VERSION ""

NS_ :

BS_:

BU_: BMU_ID_0 BMU_ID_1 BMU_ID_2 BMU_ID_3 BMU_ID_4 BMU_ID_5 BMU_ID_6 BMU_ID_7 BMU_ID_8 BMU_ID_9 BMU_ID_10 BMU_ID_11 BMU_ID_12 BMU_ID_13 BMU_ID_14 BMU_ID_15

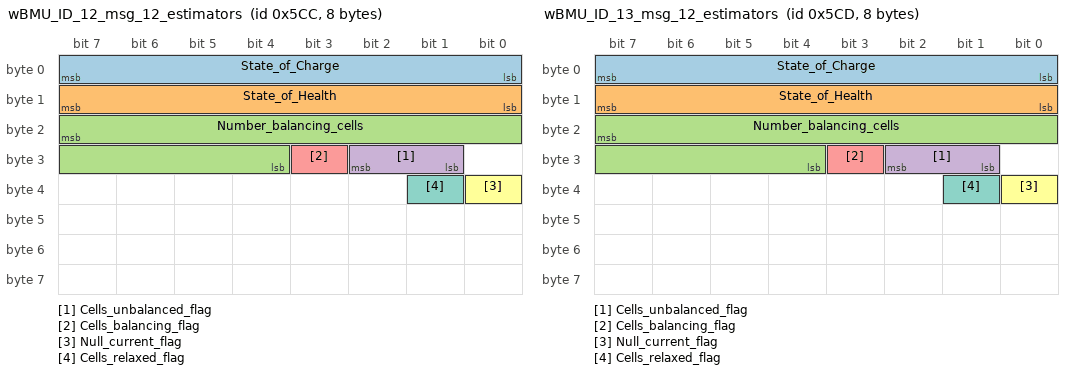
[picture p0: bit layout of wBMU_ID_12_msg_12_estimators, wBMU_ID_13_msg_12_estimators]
BO_ 1484 wBMU_ID_12_msg_12_estimators: 8 BMU_ID_12
 SG_ State_of_Charge : 7|8@0+ (1,0) [0|0] "%"  BMU_ID_0
 SG_ State_of_Health : 15|8@0+ (1,0) [0|0] "%"  BMU_ID_0
 SG_ Number_balancing_cells : 23|12@0+ (1,0) [0|0] "-"  BMU_ID_0
 SG_ Cells_unbalanced_flag : 26|2@0+ (1,0) [0|0] "-"  BMU_ID_0
 SG_ Cells_balancing_flag : 27|1@0+ (1,0) [0|0] "-"  BMU_ID_0
 SG_ Null_current_flag : 32|1@0+ (1,0) [0|0] "" Vector__XXX
 SG_ Cells_relaxed_flag : 33|1@0+ (1,0) [0|0] "" Vector__XXX

BO_ 1485 wBMU_ID_13_msg_12_estimators: 8 BMU_ID_13
 SG_ State_of_Charge : 7|8@0+ (1,0) [0|0] "%"  BMU_ID_0
 SG_ State_of_Health : 15|8@0+ (1,0) [0|0] "%"  BMU_ID_0
 SG_ Number_balancing_cells : 23|12@0+ (1,0) [0|0] "-"  BMU_ID_0
 SG_ Cells_unbalanced_flag : 26|2@0+ (1,0) [0|0] "-"  BMU_ID_0
 SG_ Cells_balancing_flag : 27|1@0+ (1,0) [0|0] "-"  BMU_ID_0
 SG_ Null_current_flag : 32|1@0+ (1,0) [0|0] "" Vector__XXX
 SG_ Cells_relaxed_flag : 33|1@0+ (1,0) [0|0] "" Vector__XXX

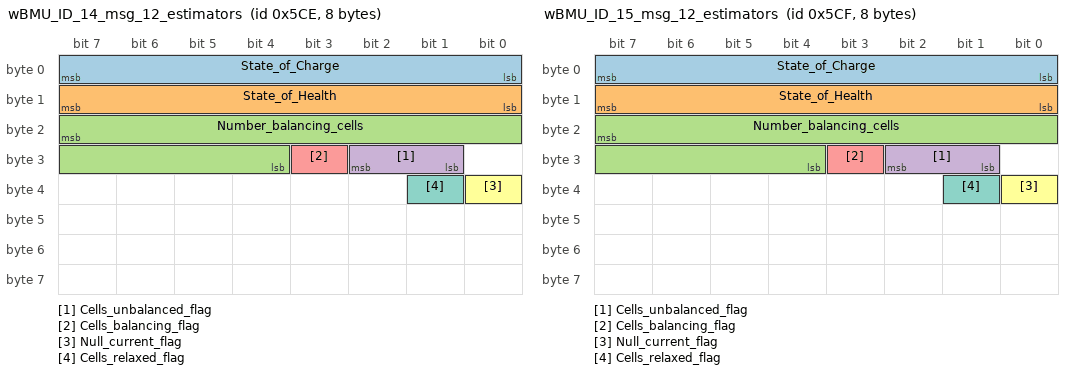
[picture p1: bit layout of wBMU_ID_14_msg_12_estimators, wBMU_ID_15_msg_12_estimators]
BO_ 1486 wBMU_ID_14_msg_12_estimators: 8 BMU_ID_14
 SG_ State_of_Charge : 7|8@0+ (1,0) [0|0] "%"  BMU_ID_0
 SG_ State_of_Health : 15|8@0+ (1,0) [0|0] "%"  BMU_ID_0
 SG_ Number_balancing_cells : 23|12@0+ (1,0) [0|0] "-"  BMU_ID_0
 SG_ Cells_unbalanced_flag : 26|2@0+ (1,0) [0|0] "-"  BMU_ID_0
 SG_ Cells_balancing_flag : 27|1@0+ (1,0) [0|0] "-"  BMU_ID_0
 SG_ Null_current_flag : 32|1@0+ (1,0) [0|0] "" Vector__XXX
 SG_ Cells_relaxed_flag : 33|1@0+ (1,0) [0|0] "" Vector__XXX

BO_ 1487 wBMU_ID_15_msg_12_estimators: 8 BMU_ID_15
 SG_ State_of_Charge : 7|8@0+ (1,0) [0|0] "%"  BMU_ID_0
 SG_ State_of_Health : 15|8@0+ (1,0) [0|0] "%"  BMU_ID_0
 SG_ Number_balancing_cells : 23|12@0+ (1,0) [0|0] "-"  BMU_ID_0
 SG_ Cells_unbalanced_flag : 26|2@0+ (1,0) [0|0] "-"  BMU_ID_0
 SG_ Cells_balancing_flag : 27|1@0+ (1,0) [0|0] "-"  BMU_ID_0
 SG_ Null_current_flag : 32|1@0+ (1,0) [0|0] "" Vector__XXX
 SG_ Cells_relaxed_flag : 33|1@0+ (1,0) [0|0] "" Vector__XXX

BO_ 1488 wBMU_ID_0_msg_13_io: 8 BMU_ID_0
 SG_ Content_ID M : 7|8@0+ (1,0) [0|0] ""  BMU_ID_0
 SG_ Positive_power_relay_status m0 : 8|1@0+ (1,0) [0|0] ""  BMU_ID_0
 SG_ Negative_power_relay_status m0 : 9|1@0+ (1,0) [0|0] ""  BMU_ID_0
 SG_ Precharge_power_relay_status m0 : 10|1@0+ (1,0) [0|0] ""  BMU_ID_0
 SG_ Middle_power_relay_status m0 : 11|1@0+ (1,0) [0|0] ""  BMU_ID_0
 SG_ Sleep_mode_request_flag m0 : 12|1@0+ (1,0) [0|0] ""  BMU_ID_0
 SG_ Emergency_button_alarm_flag m0 : 13|1@0+ (1,0) [0|0] ""  BMU_ID_0
 SG_ Start_signal_interlock_flag m0 : 14|1@0+ (1,0) [0|0] ""  BMU_ID_0
 SG_ Start_signal_actuation_req_flag m0 : 15|1@0+ (1,0) [0|0] ""  BMU_ID_0
 SG_ Heating_pad_request_flag m0 : 48|1@0+ (1,0) [0|0] ""  BMU_ID_0
 SG_ Input_1_state m0 : 16|1@0+ (1,0) [0|0] ""  BMU_ID_0
 SG_ Input_2_state m0 : 17|1@0+ (1,0) [0|0] ""  BMU_ID_0
 SG_ Input_3_state m0 : 18|1@0+ (1,0) [0|0] ""  BMU_ID_0
 SG_ Input_4_state m0 : 19|1@0+ (1,0) [0|0] ""  BMU_ID_0
 SG_ Input_5_state m0 : 20|1@0+ (1,0) [0|0] ""  BMU_ID_0
 SG_ Output_1_state m0 : 32|1@0+ (1,0) [0|0] ""  BMU_ID_0
 SG_ Output_2_state m0 : 33|1@0+ (1,0) [0|0] ""  BMU_ID_0
 SG_ Output_3_state m0 : 34|1@0+ (1,0) [0|0] ""  BMU_ID_0
 SG_ Output_4_state m0 : 35|1@0+ (1,0) [0|0] ""  BMU_ID_0
 SG_ Output_5_state m0 : 36|1@0+ (1,0) [0|0] ""  BMU_ID_0
 SG_ Output_6_state m0 : 37|1@0+ (1,0) [0|0] ""  BMU_ID_0
 SG_ Input_6_state m0 : 21|1@0+ (1,0) [0|0] ""  BMU_ID_0
 SG_ Input_7_state m0 : 22|1@0+ (1,0) [0|0] ""  BMU_ID_0
 SG_ Input_8_state m0 : 23|1@0+ (1,0) [0|0] ""  BMU_ID_0
 SG_ Input_9_state m0 : 24|1@0+ (1,0) [0|0] ""  BMU_ID_0
 SG_ Input_10_state m0 : 25|1@0+ (1,0) [0|0] ""  BMU_ID_0
 SG_ Input_11_state m0 : 26|1@0+ (1,0) [0|0] ""  BMU_ID_0
 SG_ Input_12_state m0 : 27|1@0+ (1,0) [0|0] ""  BMU_ID_0
 SG_ Output_7_state m0 : 38|1@0+ (1,0) [0|0] ""  BMU_ID_0
 SG_ Output_8_state m0 : 39|1@0+ (1,0) [0|0] ""  BMU_ID_0
 SG_ Output_9_state m0 : 40|1@0+ (1,0) [0|0] ""  BMU_ID_0
 SG_ Output_10_state m0 : 41|1@0+ (1,0) [0|0] ""  BMU_ID_0
 SG_ Output_11_state m0 : 42|1@0+ (1,0) [0|0] ""  BMU_ID_0
 SG_ Output_12_state m0 : 43|1@0+ (1,0) [0|0] ""  BMU_ID_0
 SG_ Output_13_state m0 : 44|1@0+ (1,0) [0|0] ""  BMU_ID_0
 SG_ Analog_input_1 m1 : 15|16@0+ (1,0) [0|0] "mV"  BMU_ID_0
 SG_ Analog_input_2 m1 : 31|16@0+ (1,0) [0|0] "mV"  BMU_ID_0
 SG_ Analog_input_3 m1 : 47|16@0+ (1,0) [0|0] "mV"  BMU_ID_0

BO_ 1489 wBMU_ID_1_msg_13_io: 8 BMU_ID_1
 SG_ Content_ID M : 7|8@0+ (1,0) [0|0] ""  BMU_ID_0
 SG_ Positive_power_relay_status m0 : 8|1@0+ (1,0) [0|0] ""  BMU_ID_0
 SG_ Negative_power_relay_status m0 : 9|1@0+ (1,0) [0|0] ""  BMU_ID_0
 SG_ Precharge_power_relay_status m0 : 10|1@0+ (1,0) [0|0] ""  BMU_ID_0
 SG_ Middle_power_relay_status m0 : 11|1@0+ (1,0) [0|0] ""  BMU_ID_0
 SG_ Sleep_mode_request_flag m0 : 12|1@0+ (1,0) [0|0] ""  BMU_ID_0
 SG_ Emergency_button_alarm_flag m0 : 13|1@0+ (1,0) [0|0] ""  BMU_ID_0
 SG_ Start_signal_interlock_flag m0 : 14|1@0+ (1,0) [0|0] ""  BMU_ID_0
 SG_ Start_signal_actuation_req_flag m0 : 15|1@0+ (1,0) [0|0] ""  BMU_ID_0
 SG_ Heating_pad_request_flag m0 : 48|1@0+ (1,0) [0|0] ""  BMU_ID_0
 SG_ Input_1_state m0 : 16|1@0+ (1,0) [0|0] ""  BMU_ID_0
 SG_ Input_2_state m0 : 17|1@0+ (1,0) [0|0] ""  BMU_ID_0
 SG_ Input_3_state m0 : 18|1@0+ (1,0) [0|0] ""  BMU_ID_0
 SG_ Input_4_state m0 : 19|1@0+ (1,0) [0|0] ""  BMU_ID_0
 SG_ Input_5_state m0 : 20|1@0+ (1,0) [0|0] ""  BMU_ID_0
 SG_ Output_1_state m0 : 32|1@0+ (1,0) [0|0] ""  BMU_ID_0
 SG_ Output_2_state m0 : 33|1@0+ (1,0) [0|0] ""  BMU_ID_0
 SG_ Output_3_state m0 : 34|1@0+ (1,0) [0|0] ""  BMU_ID_0
 SG_ Output_4_state m0 : 35|1@0+ (1,0) [0|0] ""  BMU_ID_0
 SG_ Output_5_state m0 : 36|1@0+ (1,0) [0|0] ""  BMU_ID_0
 SG_ Output_6_state m0 : 37|1@0+ (1,0) [0|0] ""  BMU_ID_0
 SG_ Input_6_state m0 : 21|1@0+ (1,0) [0|0] ""  BMU_ID_0
 SG_ Input_7_state m0 : 22|1@0+ (1,0) [0|0] ""  BMU_ID_0
 SG_ Input_8_state m0 : 23|1@0+ (1,0) [0|0] ""  BMU_ID_0
 SG_ Input_9_state m0 : 24|1@0+ (1,0) [0|0] ""  BMU_ID_0
 SG_ Input_10_state m0 : 25|1@0+ (1,0) [0|0] ""  BMU_ID_0
 SG_ Input_11_state m0 : 26|1@0+ (1,0) [0|0] ""  BMU_ID_0
 SG_ Input_12_state m0 : 27|1@0+ (1,0) [0|0] ""  BMU_ID_0
 SG_ Output_7_state m0 : 38|1@0+ (1,0) [0|0] ""  BMU_ID_0
 SG_ Output_8_state m0 : 39|1@0+ (1,0) [0|0] ""  BMU_ID_0
 SG_ Output_9_state m0 : 40|1@0+ (1,0) [0|0] ""  BMU_ID_0
 SG_ Output_10_state m0 : 41|1@0+ (1,0) [0|0] ""  BMU_ID_0
 SG_ Output_11_state m0 : 42|1@0+ (1,0) [0|0] ""  BMU_ID_0
 SG_ Output_12_state m0 : 43|1@0+ (1,0) [0|0] ""  BMU_ID_0
 SG_ Output_13_state m0 : 44|1@0+ (1,0) [0|0] ""  BMU_ID_0
 SG_ Analog_input_1 m1 : 15|16@0+ (1,0) [0|0] "mV"  BMU_ID_0
 SG_ Analog_input_2 m1 : 31|16@0+ (1,0) [0|0] "mV"  BMU_ID_0
 SG_ Analog_input_3 m1 : 47|16@0+ (1,0) [0|0] "mV"  BMU_ID_0

BO_ 1490 wBMU_ID_2_msg_13_io: 8 BMU_ID_2
 SG_ Content_ID M : 7|8@0+ (1,0) [0|0] ""  BMU_ID_0
 SG_ Positive_power_relay_status m0 : 8|1@0+ (1,0) [0|0] ""  BMU_ID_0
 SG_ Negative_power_relay_status m0 : 9|1@0+ (1,0) [0|0] ""  BMU_ID_0
 SG_ Precharge_power_relay_status m0 : 10|1@0+ (1,0) [0|0] ""  BMU_ID_0
 SG_ Middle_power_relay_status m0 : 11|1@0+ (1,0) [0|0] ""  BMU_ID_0
 SG_ Sleep_mode_request_flag m0 : 12|1@0+ (1,0) [0|0] ""  BMU_ID_0
 SG_ Emergency_button_alarm_flag m0 : 13|1@0+ (1,0) [0|0] ""  BMU_ID_0
 SG_ Start_signal_interlock_flag m0 : 14|1@0+ (1,0) [0|0] ""  BMU_ID_0
 SG_ Start_signal_actuation_req_flag m0 : 15|1@0+ (1,0) [0|0] ""  BMU_ID_0
 SG_ Heating_pad_request_flag m0 : 48|1@0+ (1,0) [0|0] ""  BMU_ID_0
 SG_ Input_1_state m0 : 16|1@0+ (1,0) [0|0] ""  BMU_ID_0
 SG_ Input_2_state m0 : 17|1@0+ (1,0) [0|0] ""  BMU_ID_0
 SG_ Input_3_state m0 : 18|1@0+ (1,0) [0|0] ""  BMU_ID_0
 SG_ Input_4_state m0 : 19|1@0+ (1,0) [0|0] ""  BMU_ID_0
 SG_ Input_5_state m0 : 20|1@0+ (1,0) [0|0] ""  BMU_ID_0
 SG_ Output_1_state m0 : 32|1@0+ (1,0) [0|0] ""  BMU_ID_0
 SG_ Output_2_state m0 : 33|1@0+ (1,0) [0|0] ""  BMU_ID_0
 SG_ Output_3_state m0 : 34|1@0+ (1,0) [0|0] ""  BMU_ID_0
 SG_ Output_4_state m0 : 35|1@0+ (1,0) [0|0] ""  BMU_ID_0
 SG_ Output_5_state m0 : 36|1@0+ (1,0) [0|0] ""  BMU_ID_0
 SG_ Output_6_state m0 : 37|1@0+ (1,0) [0|0] ""  BMU_ID_0
 SG_ Input_6_state m0 : 21|1@0+ (1,0) [0|0] ""  BMU_ID_0
 SG_ Input_7_state m0 : 22|1@0+ (1,0) [0|0] ""  BMU_ID_0
 SG_ Input_8_state m0 : 23|1@0+ (1,0) [0|0] ""  BMU_ID_0
 SG_ Input_9_state m0 : 24|1@0+ (1,0) [0|0] ""  BMU_ID_0
 SG_ Input_10_state m0 : 25|1@0+ (1,0) [0|0] ""  BMU_ID_0
 SG_ Input_11_state m0 : 26|1@0+ (1,0) [0|0] ""  BMU_ID_0
 SG_ Input_12_state m0 : 27|1@0+ (1,0) [0|0] ""  BMU_ID_0
 SG_ Output_7_state m0 : 38|1@0+ (1,0) [0|0] ""  BMU_ID_0
 SG_ Output_8_state m0 : 39|1@0+ (1,0) [0|0] ""  BMU_ID_0
 SG_ Output_9_state m0 : 40|1@0+ (1,0) [0|0] ""  BMU_ID_0
 SG_ Output_10_state m0 : 41|1@0+ (1,0) [0|0] ""  BMU_ID_0
 SG_ Output_11_state m0 : 42|1@0+ (1,0) [0|0] ""  BMU_ID_0
 SG_ Output_12_state m0 : 43|1@0+ (1,0) [0|0] ""  BMU_ID_0
 SG_ Output_13_state m0 : 44|1@0+ (1,0) [0|0] ""  BMU_ID_0
 SG_ Analog_input_1 m1 : 15|16@0+ (1,0) [0|0] "mV"  BMU_ID_0
 SG_ Analog_input_2 m1 : 31|16@0+ (1,0) [0|0] "mV"  BMU_ID_0
 SG_ Analog_input_3 m1 : 47|16@0+ (1,0) [0|0] "mV"  BMU_ID_0

BO_ 1491 wBMU_ID_3_msg_13_io: 8 BMU_ID_3
 SG_ Content_ID M : 7|8@0+ (1,0) [0|0] ""  BMU_ID_0
 SG_ Positive_power_relay_status m0 : 8|1@0+ (1,0) [0|0] ""  BMU_ID_0
 SG_ Negative_power_relay_status m0 : 9|1@0+ (1,0) [0|0] ""  BMU_ID_0
 SG_ Precharge_power_relay_status m0 : 10|1@0+ (1,0) [0|0] ""  BMU_ID_0
 SG_ Middle_power_relay_status m0 : 11|1@0+ (1,0) [0|0] ""  BMU_ID_0
 SG_ Sleep_mode_request_flag m0 : 12|1@0+ (1,0) [0|0] ""  BMU_ID_0
 SG_ Emergency_button_alarm_flag m0 : 13|1@0+ (1,0) [0|0] ""  BMU_ID_0
 SG_ Start_signal_interlock_flag m0 : 14|1@0+ (1,0) [0|0] ""  BMU_ID_0
 SG_ Start_signal_actuation_req_flag m0 : 15|1@0+ (1,0) [0|0] ""  BMU_ID_0
 SG_ Heating_pad_request_flag m0 : 48|1@0+ (1,0) [0|0] ""  BMU_ID_0
 SG_ Input_1_state m0 : 16|1@0+ (1,0) [0|0] ""  BMU_ID_0
 SG_ Input_2_state m0 : 17|1@0+ (1,0) [0|0] ""  BMU_ID_0
 SG_ Input_3_state m0 : 18|1@0+ (1,0) [0|0] ""  BMU_ID_0
 SG_ Input_4_state m0 : 19|1@0+ (1,0) [0|0] ""  BMU_ID_0
 SG_ Input_5_state m0 : 20|1@0+ (1,0) [0|0] ""  BMU_ID_0
 SG_ Output_1_state m0 : 32|1@0+ (1,0) [0|0] ""  BMU_ID_0
 SG_ Output_2_state m0 : 33|1@0+ (1,0) [0|0] ""  BMU_ID_0
 SG_ Output_3_state m0 : 34|1@0+ (1,0) [0|0] ""  BMU_ID_0
 SG_ Output_4_state m0 : 35|1@0+ (1,0) [0|0] ""  BMU_ID_0
 SG_ Output_5_state m0 : 36|1@0+ (1,0) [0|0] ""  BMU_ID_0
 SG_ Output_6_state m0 : 37|1@0+ (1,0) [0|0] ""  BMU_ID_0
 SG_ Input_6_state m0 : 21|1@0+ (1,0) [0|0] ""  BMU_ID_0
 SG_ Input_7_state m0 : 22|1@0+ (1,0) [0|0] ""  BMU_ID_0
 SG_ Input_8_state m0 : 23|1@0+ (1,0) [0|0] ""  BMU_ID_0
 SG_ Input_9_state m0 : 24|1@0+ (1,0) [0|0] ""  BMU_ID_0
 SG_ Input_10_state m0 : 25|1@0+ (1,0) [0|0] ""  BMU_ID_0
 SG_ Input_11_state m0 : 26|1@0+ (1,0) [0|0] ""  BMU_ID_0
 SG_ Input_12_state m0 : 27|1@0+ (1,0) [0|0] ""  BMU_ID_0
 SG_ Output_7_state m0 : 38|1@0+ (1,0) [0|0] ""  BMU_ID_0
 SG_ Output_8_state m0 : 39|1@0+ (1,0) [0|0] ""  BMU_ID_0
 SG_ Output_9_state m0 : 40|1@0+ (1,0) [0|0] ""  BMU_ID_0
 SG_ Output_10_state m0 : 41|1@0+ (1,0) [0|0] ""  BMU_ID_0
 SG_ Output_11_state m0 : 42|1@0+ (1,0) [0|0] ""  BMU_ID_0
 SG_ Output_12_state m0 : 43|1@0+ (1,0) [0|0] ""  BMU_ID_0
 SG_ Output_13_state m0 : 44|1@0+ (1,0) [0|0] ""  BMU_ID_0
 SG_ Analog_input_1 m1 : 15|16@0+ (1,0) [0|0] "mV"  BMU_ID_0
 SG_ Analog_input_2 m1 : 31|16@0+ (1,0) [0|0] "mV"  BMU_ID_0
 SG_ Analog_input_3 m1 : 47|16@0+ (1,0) [0|0] "mV"  BMU_ID_0

BO_ 1492 wBMU_ID_4_msg_13_io: 8 BMU_ID_4
 SG_ Content_ID M : 7|8@0+ (1,0) [0|0] ""  BMU_ID_0
 SG_ Positive_power_relay_status m0 : 8|1@0+ (1,0) [0|0] ""  BMU_ID_0
 SG_ Negative_power_relay_status m0 : 9|1@0+ (1,0) [0|0] ""  BMU_ID_0
 SG_ Precharge_power_relay_status m0 : 10|1@0+ (1,0) [0|0] ""  BMU_ID_0
 SG_ Middle_power_relay_status m0 : 11|1@0+ (1,0) [0|0] ""  BMU_ID_0
 SG_ Sleep_mode_request_flag m0 : 12|1@0+ (1,0) [0|0] ""  BMU_ID_0
 SG_ Emergency_button_alarm_flag m0 : 13|1@0+ (1,0) [0|0] ""  BMU_ID_0
 SG_ Start_signal_interlock_flag m0 : 14|1@0+ (1,0) [0|0] ""  BMU_ID_0
 SG_ Start_signal_actuation_req_flag m0 : 15|1@0+ (1,0) [0|0] ""  BMU_ID_0
 SG_ Heating_pad_request_flag m0 : 48|1@0+ (1,0) [0|0] ""  BMU_ID_0
 SG_ Input_1_state m0 : 16|1@0+ (1,0) [0|0] ""  BMU_ID_0
 SG_ Input_2_state m0 : 17|1@0+ (1,0) [0|0] ""  BMU_ID_0
 SG_ Input_3_state m0 : 18|1@0+ (1,0) [0|0] ""  BMU_ID_0
 SG_ Input_4_state m0 : 19|1@0+ (1,0) [0|0] ""  BMU_ID_0
 SG_ Input_5_state m0 : 20|1@0+ (1,0) [0|0] ""  BMU_ID_0
 SG_ Output_1_state m0 : 32|1@0+ (1,0) [0|0] ""  BMU_ID_0
 SG_ Output_2_state m0 : 33|1@0+ (1,0) [0|0] ""  BMU_ID_0
 SG_ Output_3_state m0 : 34|1@0+ (1,0) [0|0] ""  BMU_ID_0
 SG_ Output_4_state m0 : 35|1@0+ (1,0) [0|0] ""  BMU_ID_0
 SG_ Output_5_state m0 : 36|1@0+ (1,0) [0|0] ""  BMU_ID_0
 SG_ Output_6_state m0 : 37|1@0+ (1,0) [0|0] ""  BMU_ID_0
 SG_ Input_6_state m0 : 21|1@0+ (1,0) [0|0] ""  BMU_ID_0
 SG_ Input_7_state m0 : 22|1@0+ (1,0) [0|0] ""  BMU_ID_0
 SG_ Input_8_state m0 : 23|1@0+ (1,0) [0|0] ""  BMU_ID_0
 SG_ Input_9_state m0 : 24|1@0+ (1,0) [0|0] ""  BMU_ID_0
 SG_ Input_10_state m0 : 25|1@0+ (1,0) [0|0] ""  BMU_ID_0
 SG_ Input_11_state m0 : 26|1@0+ (1,0) [0|0] ""  BMU_ID_0
 SG_ Input_12_state m0 : 27|1@0+ (1,0) [0|0] ""  BMU_ID_0
 SG_ Output_7_state m0 : 38|1@0+ (1,0) [0|0] ""  BMU_ID_0
 SG_ Output_8_state m0 : 39|1@0+ (1,0) [0|0] ""  BMU_ID_0
 SG_ Output_9_state m0 : 40|1@0+ (1,0) [0|0] ""  BMU_ID_0
 SG_ Output_10_state m0 : 41|1@0+ (1,0) [0|0] ""  BMU_ID_0
 SG_ Output_11_state m0 : 42|1@0+ (1,0) [0|0] ""  BMU_ID_0
 SG_ Output_12_state m0 : 43|1@0+ (1,0) [0|0] ""  BMU_ID_0
 SG_ Output_13_state m0 : 44|1@0+ (1,0) [0|0] ""  BMU_ID_0
 SG_ Analog_input_1 m1 : 15|16@0+ (1,0) [0|0] "mV"  BMU_ID_0
 SG_ Analog_input_2 m1 : 31|16@0+ (1,0) [0|0] "mV"  BMU_ID_0
 SG_ Analog_input_3 m1 : 47|16@0+ (1,0) [0|0] "mV"  BMU_ID_0

BO_ 1493 wBMU_ID_5_msg_13_io: 8 BMU_ID_5
 SG_ Content_ID M : 7|8@0+ (1,0) [0|0] ""  BMU_ID_0
 SG_ Positive_power_relay_status m0 : 8|1@0+ (1,0) [0|0] ""  BMU_ID_0
 SG_ Negative_power_relay_status m0 : 9|1@0+ (1,0) [0|0] ""  BMU_ID_0
 SG_ Precharge_power_relay_status m0 : 10|1@0+ (1,0) [0|0] ""  BMU_ID_0
 SG_ Middle_power_relay_status m0 : 11|1@0+ (1,0) [0|0] ""  BMU_ID_0
 SG_ Sleep_mode_request_flag m0 : 12|1@0+ (1,0) [0|0] ""  BMU_ID_0
 SG_ Emergency_button_alarm_flag m0 : 13|1@0+ (1,0) [0|0] ""  BMU_ID_0
 SG_ Start_signal_interlock_flag m0 : 14|1@0+ (1,0) [0|0] ""  BMU_ID_0
 SG_ Start_signal_actuation_req_flag m0 : 15|1@0+ (1,0) [0|0] ""  BMU_ID_0
 SG_ Heating_pad_request_flag m0 : 48|1@0+ (1,0) [0|0] ""  BMU_ID_0
 SG_ Input_1_state m0 : 16|1@0+ (1,0) [0|0] ""  BMU_ID_0
 SG_ Input_2_state m0 : 17|1@0+ (1,0) [0|0] ""  BMU_ID_0
 SG_ Input_3_state m0 : 18|1@0+ (1,0) [0|0] ""  BMU_ID_0
 SG_ Input_4_state m0 : 19|1@0+ (1,0) [0|0] ""  BMU_ID_0
 SG_ Input_5_state m0 : 20|1@0+ (1,0) [0|0] ""  BMU_ID_0
 SG_ Output_1_state m0 : 32|1@0+ (1,0) [0|0] ""  BMU_ID_0
 SG_ Output_2_state m0 : 33|1@0+ (1,0) [0|0] ""  BMU_ID_0
 SG_ Output_3_state m0 : 34|1@0+ (1,0) [0|0] ""  BMU_ID_0
 SG_ Output_4_state m0 : 35|1@0+ (1,0) [0|0] ""  BMU_ID_0
 SG_ Output_5_state m0 : 36|1@0+ (1,0) [0|0] ""  BMU_ID_0
 SG_ Output_6_state m0 : 37|1@0+ (1,0) [0|0] ""  BMU_ID_0
 SG_ Input_6_state m0 : 21|1@0+ (1,0) [0|0] ""  BMU_ID_0
 SG_ Input_7_state m0 : 22|1@0+ (1,0) [0|0] ""  BMU_ID_0
 SG_ Input_8_state m0 : 23|1@0+ (1,0) [0|0] ""  BMU_ID_0
 SG_ Input_9_state m0 : 24|1@0+ (1,0) [0|0] ""  BMU_ID_0
 SG_ Input_10_state m0 : 25|1@0+ (1,0) [0|0] ""  BMU_ID_0
 SG_ Input_11_state m0 : 26|1@0+ (1,0) [0|0] ""  BMU_ID_0
 SG_ Input_12_state m0 : 27|1@0+ (1,0) [0|0] ""  BMU_ID_0
 SG_ Output_7_state m0 : 38|1@0+ (1,0) [0|0] ""  BMU_ID_0
 SG_ Output_8_state m0 : 39|1@0+ (1,0) [0|0] ""  BMU_ID_0
 SG_ Output_9_state m0 : 40|1@0+ (1,0) [0|0] ""  BMU_ID_0
 SG_ Output_10_state m0 : 41|1@0+ (1,0) [0|0] ""  BMU_ID_0
 SG_ Output_11_state m0 : 42|1@0+ (1,0) [0|0] ""  BMU_ID_0
 SG_ Output_12_state m0 : 43|1@0+ (1,0) [0|0] ""  BMU_ID_0
 SG_ Output_13_state m0 : 44|1@0+ (1,0) [0|0] ""  BMU_ID_0
 SG_ Analog_input_1 m1 : 15|16@0+ (1,0) [0|0] "mV"  BMU_ID_0
 SG_ Analog_input_2 m1 : 31|16@0+ (1,0) [0|0] "mV"  BMU_ID_0
 SG_ Analog_input_3 m1 : 47|16@0+ (1,0) [0|0] "mV"  BMU_ID_0

BO_ 1494 wBMU_ID_6_msg_13_io: 8 BMU_ID_6
 SG_ Content_ID M : 7|8@0+ (1,0) [0|0] ""  BMU_ID_0
 SG_ Positive_power_relay_status m0 : 8|1@0+ (1,0) [0|0] ""  BMU_ID_0
 SG_ Negative_power_relay_status m0 : 9|1@0+ (1,0) [0|0] ""  BMU_ID_0
 SG_ Precharge_power_relay_status m0 : 10|1@0+ (1,0) [0|0] ""  BMU_ID_0
 SG_ Middle_power_relay_status m0 : 11|1@0+ (1,0) [0|0] ""  BMU_ID_0
 SG_ Sleep_mode_request_flag m0 : 12|1@0+ (1,0) [0|0] ""  BMU_ID_0
 SG_ Emergency_button_alarm_flag m0 : 13|1@0+ (1,0) [0|0] ""  BMU_ID_0
 SG_ Start_signal_interlock_flag m0 : 14|1@0+ (1,0) [0|0] ""  BMU_ID_0
 SG_ Start_signal_actuation_req_flag m0 : 15|1@0+ (1,0) [0|0] ""  BMU_ID_0
 SG_ Heating_pad_request_flag m0 : 48|1@0+ (1,0) [0|0] ""  BMU_ID_0
 SG_ Input_1_state m0 : 16|1@0+ (1,0) [0|0] ""  BMU_ID_0
 SG_ Input_2_state m0 : 17|1@0+ (1,0) [0|0] ""  BMU_ID_0
 SG_ Input_3_state m0 : 18|1@0+ (1,0) [0|0] ""  BMU_ID_0
 SG_ Input_4_state m0 : 19|1@0+ (1,0) [0|0] ""  BMU_ID_0
 SG_ Input_5_state m0 : 20|1@0+ (1,0) [0|0] ""  BMU_ID_0
 SG_ Output_1_state m0 : 32|1@0+ (1,0) [0|0] ""  BMU_ID_0
 SG_ Output_2_state m0 : 33|1@0+ (1,0) [0|0] ""  BMU_ID_0
 SG_ Output_3_state m0 : 34|1@0+ (1,0) [0|0] ""  BMU_ID_0
 SG_ Output_4_state m0 : 35|1@0+ (1,0) [0|0] ""  BMU_ID_0
 SG_ Output_5_state m0 : 36|1@0+ (1,0) [0|0] ""  BMU_ID_0
 SG_ Output_6_state m0 : 37|1@0+ (1,0) [0|0] ""  BMU_ID_0
 SG_ Input_6_state m0 : 21|1@0+ (1,0) [0|0] ""  BMU_ID_0
 SG_ Input_7_state m0 : 22|1@0+ (1,0) [0|0] ""  BMU_ID_0
 SG_ Input_8_state m0 : 23|1@0+ (1,0) [0|0] ""  BMU_ID_0
 SG_ Input_9_state m0 : 24|1@0+ (1,0) [0|0] ""  BMU_ID_0
 SG_ Input_10_state m0 : 25|1@0+ (1,0) [0|0] ""  BMU_ID_0
 SG_ Input_11_state m0 : 26|1@0+ (1,0) [0|0] ""  BMU_ID_0
 SG_ Input_12_state m0 : 27|1@0+ (1,0) [0|0] ""  BMU_ID_0
 SG_ Output_7_state m0 : 38|1@0+ (1,0) [0|0] ""  BMU_ID_0
 SG_ Output_8_state m0 : 39|1@0+ (1,0) [0|0] ""  BMU_ID_0
 SG_ Output_9_state m0 : 40|1@0+ (1,0) [0|0] ""  BMU_ID_0
 SG_ Output_10_state m0 : 41|1@0+ (1,0) [0|0] ""  BMU_ID_0
 SG_ Output_11_state m0 : 42|1@0+ (1,0) [0|0] ""  BMU_ID_0
 SG_ Output_12_state m0 : 43|1@0+ (1,0) [0|0] ""  BMU_ID_0
 SG_ Output_13_state m0 : 44|1@0+ (1,0) [0|0] ""  BMU_ID_0
 SG_ Analog_input_1 m1 : 15|16@0+ (1,0) [0|0] "mV"  BMU_ID_0
 SG_ Analog_input_2 m1 : 31|16@0+ (1,0) [0|0] "mV"  BMU_ID_0
 SG_ Analog_input_3 m1 : 47|16@0+ (1,0) [0|0] "mV"  BMU_ID_0

BO_ 1495 wBMU_ID_7_msg_13_io: 8 BMU_ID_7
 SG_ Content_ID M : 7|8@0+ (1,0) [0|0] ""  BMU_ID_0
 SG_ Positive_power_relay_status m0 : 8|1@0+ (1,0) [0|0] ""  BMU_ID_0
 SG_ Negative_power_relay_status m0 : 9|1@0+ (1,0) [0|0] ""  BMU_ID_0
 SG_ Precharge_power_relay_status m0 : 10|1@0+ (1,0) [0|0] ""  BMU_ID_0
 SG_ Middle_power_relay_status m0 : 11|1@0+ (1,0) [0|0] ""  BMU_ID_0
 SG_ Sleep_mode_request_flag m0 : 12|1@0+ (1,0) [0|0] ""  BMU_ID_0
 SG_ Emergency_button_alarm_flag m0 : 13|1@0+ (1,0) [0|0] ""  BMU_ID_0
 SG_ Start_signal_interlock_flag m0 : 14|1@0+ (1,0) [0|0] ""  BMU_ID_0
 SG_ Start_signal_actuation_req_flag m0 : 15|1@0+ (1,0) [0|0] ""  BMU_ID_0
 SG_ Heating_pad_request_flag m0 : 48|1@0+ (1,0) [0|0] ""  BMU_ID_0
 SG_ Input_1_state m0 : 16|1@0+ (1,0) [0|0] ""  BMU_ID_0
 SG_ Input_2_state m0 : 17|1@0+ (1,0) [0|0] ""  BMU_ID_0
 SG_ Input_3_state m0 : 18|1@0+ (1,0) [0|0] ""  BMU_ID_0
 SG_ Input_4_state m0 : 19|1@0+ (1,0) [0|0] ""  BMU_ID_0
 SG_ Input_5_state m0 : 20|1@0+ (1,0) [0|0] ""  BMU_ID_0
 SG_ Output_1_state m0 : 32|1@0+ (1,0) [0|0] ""  BMU_ID_0
 SG_ Output_2_state m0 : 33|1@0+ (1,0) [0|0] ""  BMU_ID_0
 SG_ Output_3_state m0 : 34|1@0+ (1,0) [0|0] ""  BMU_ID_0
 SG_ Output_4_state m0 : 35|1@0+ (1,0) [0|0] ""  BMU_ID_0
 SG_ Output_5_state m0 : 36|1@0+ (1,0) [0|0] ""  BMU_ID_0
 SG_ Output_6_state m0 : 37|1@0+ (1,0) [0|0] ""  BMU_ID_0
 SG_ Input_6_state m0 : 21|1@0+ (1,0) [0|0] ""  BMU_ID_0
 SG_ Input_7_state m0 : 22|1@0+ (1,0) [0|0] ""  BMU_ID_0
 SG_ Input_8_state m0 : 23|1@0+ (1,0) [0|0] ""  BMU_ID_0
 SG_ Input_9_state m0 : 24|1@0+ (1,0) [0|0] ""  BMU_ID_0
 SG_ Input_10_state m0 : 25|1@0+ (1,0) [0|0] ""  BMU_ID_0
 SG_ Input_11_state m0 : 26|1@0+ (1,0) [0|0] ""  BMU_ID_0
 SG_ Input_12_state m0 : 27|1@0+ (1,0) [0|0] ""  BMU_ID_0
 SG_ Output_7_state m0 : 38|1@0+ (1,0) [0|0] ""  BMU_ID_0
 SG_ Output_8_state m0 : 39|1@0+ (1,0) [0|0] ""  BMU_ID_0
 SG_ Output_9_state m0 : 40|1@0+ (1,0) [0|0] ""  BMU_ID_0
 SG_ Output_10_state m0 : 41|1@0+ (1,0) [0|0] ""  BMU_ID_0
 SG_ Output_11_state m0 : 42|1@0+ (1,0) [0|0] ""  BMU_ID_0
 SG_ Output_12_state m0 : 43|1@0+ (1,0) [0|0] ""  BMU_ID_0
 SG_ Output_13_state m0 : 44|1@0+ (1,0) [0|0] ""  BMU_ID_0
 SG_ Analog_input_1 m1 : 15|16@0+ (1,0) [0|0] "mV"  BMU_ID_0
 SG_ Analog_input_2 m1 : 31|16@0+ (1,0) [0|0] "mV"  BMU_ID_0
 SG_ Analog_input_3 m1 : 47|16@0+ (1,0) [0|0] "mV"  BMU_ID_0

BO_ 1496 wBMU_ID_8_msg_13_io: 8 BMU_ID_8
 SG_ Content_ID M : 7|8@0+ (1,0) [0|0] ""  BMU_ID_0
 SG_ Positive_power_relay_status m0 : 8|1@0+ (1,0) [0|0] ""  BMU_ID_0
 SG_ Negative_power_relay_status m0 : 9|1@0+ (1,0) [0|0] ""  BMU_ID_0
 SG_ Precharge_power_relay_status m0 : 10|1@0+ (1,0) [0|0] ""  BMU_ID_0
 SG_ Middle_power_relay_status m0 : 11|1@0+ (1,0) [0|0] ""  BMU_ID_0
 SG_ Sleep_mode_request_flag m0 : 12|1@0+ (1,0) [0|0] ""  BMU_ID_0
 SG_ Emergency_button_alarm_flag m0 : 13|1@0+ (1,0) [0|0] ""  BMU_ID_0
 SG_ Start_signal_interlock_flag m0 : 14|1@0+ (1,0) [0|0] ""  BMU_ID_0
 SG_ Start_signal_actuation_req_flag m0 : 15|1@0+ (1,0) [0|0] ""  BMU_ID_0
 SG_ Heating_pad_request_flag m0 : 48|1@0+ (1,0) [0|0] ""  BMU_ID_0
 SG_ Input_1_state m0 : 16|1@0+ (1,0) [0|0] ""  BMU_ID_0
 SG_ Input_2_state m0 : 17|1@0+ (1,0) [0|0] ""  BMU_ID_0
 SG_ Input_3_state m0 : 18|1@0+ (1,0) [0|0] ""  BMU_ID_0
 SG_ Input_4_state m0 : 19|1@0+ (1,0) [0|0] ""  BMU_ID_0
 SG_ Input_5_state m0 : 20|1@0+ (1,0) [0|0] ""  BMU_ID_0
 SG_ Output_1_state m0 : 32|1@0+ (1,0) [0|0] ""  BMU_ID_0
 SG_ Output_2_state m0 : 33|1@0+ (1,0) [0|0] ""  BMU_ID_0
 SG_ Output_3_state m0 : 34|1@0+ (1,0) [0|0] ""  BMU_ID_0
 SG_ Output_4_state m0 : 35|1@0+ (1,0) [0|0] ""  BMU_ID_0
 SG_ Output_5_state m0 : 36|1@0+ (1,0) [0|0] ""  BMU_ID_0
 SG_ Output_6_state m0 : 37|1@0+ (1,0) [0|0] ""  BMU_ID_0
 SG_ Input_6_state m0 : 21|1@0+ (1,0) [0|0] ""  BMU_ID_0
 SG_ Input_7_state m0 : 22|1@0+ (1,0) [0|0] ""  BMU_ID_0
 SG_ Input_8_state m0 : 23|1@0+ (1,0) [0|0] ""  BMU_ID_0
 SG_ Input_9_state m0 : 24|1@0+ (1,0) [0|0] ""  BMU_ID_0
 SG_ Input_10_state m0 : 25|1@0+ (1,0) [0|0] ""  BMU_ID_0
 SG_ Input_11_state m0 : 26|1@0+ (1,0) [0|0] ""  BMU_ID_0
 SG_ Input_12_state m0 : 27|1@0+ (1,0) [0|0] ""  BMU_ID_0
 SG_ Output_7_state m0 : 38|1@0+ (1,0) [0|0] ""  BMU_ID_0
 SG_ Output_8_state m0 : 39|1@0+ (1,0) [0|0] ""  BMU_ID_0
 SG_ Output_9_state m0 : 40|1@0+ (1,0) [0|0] ""  BMU_ID_0
 SG_ Output_10_state m0 : 41|1@0+ (1,0) [0|0] ""  BMU_ID_0
 SG_ Output_11_state m0 : 42|1@0+ (1,0) [0|0] ""  BMU_ID_0
 SG_ Output_12_state m0 : 43|1@0+ (1,0) [0|0] ""  BMU_ID_0
 SG_ Output_13_state m0 : 44|1@0+ (1,0) [0|0] ""  BMU_ID_0
 SG_ Analog_input_1 m1 : 15|16@0+ (1,0) [0|0] "mV"  BMU_ID_0
 SG_ Analog_input_2 m1 : 31|16@0+ (1,0) [0|0] "mV"  BMU_ID_0
 SG_ Analog_input_3 m1 : 47|16@0+ (1,0) [0|0] "mV"  BMU_ID_0

BO_ 1497 wBMU_ID_9_msg_13_io: 8 BMU_ID_9
 SG_ Content_ID M : 7|8@0+ (1,0) [0|0] ""  BMU_ID_0
 SG_ Positive_power_relay_status m0 : 8|1@0+ (1,0) [0|0] ""  BMU_ID_0
 SG_ Negative_power_relay_status m0 : 9|1@0+ (1,0) [0|0] ""  BMU_ID_0
 SG_ Precharge_power_relay_status m0 : 10|1@0+ (1,0) [0|0] ""  BMU_ID_0
 SG_ Middle_power_relay_status m0 : 11|1@0+ (1,0) [0|0] ""  BMU_ID_0
 SG_ Sleep_mode_request_flag m0 : 12|1@0+ (1,0) [0|0] ""  BMU_ID_0
 SG_ Emergency_button_alarm_flag m0 : 13|1@0+ (1,0) [0|0] ""  BMU_ID_0
 SG_ Start_signal_interlock_flag m0 : 14|1@0+ (1,0) [0|0] ""  BMU_ID_0
 SG_ Start_signal_actuation_req_flag m0 : 15|1@0+ (1,0) [0|0] ""  BMU_ID_0
 SG_ Heating_pad_request_flag m0 : 48|1@0+ (1,0) [0|0] ""  BMU_ID_0
 SG_ Input_1_state m0 : 16|1@0+ (1,0) [0|0] ""  BMU_ID_0
 SG_ Input_2_state m0 : 17|1@0+ (1,0) [0|0] ""  BMU_ID_0
 SG_ Input_3_state m0 : 18|1@0+ (1,0) [0|0] ""  BMU_ID_0
 SG_ Input_4_state m0 : 19|1@0+ (1,0) [0|0] ""  BMU_ID_0
 SG_ Input_5_state m0 : 20|1@0+ (1,0) [0|0] ""  BMU_ID_0
 SG_ Output_1_state m0 : 32|1@0+ (1,0) [0|0] ""  BMU_ID_0
 SG_ Output_2_state m0 : 33|1@0+ (1,0) [0|0] ""  BMU_ID_0
 SG_ Output_3_state m0 : 34|1@0+ (1,0) [0|0] ""  BMU_ID_0
 SG_ Output_4_state m0 : 35|1@0+ (1,0) [0|0] ""  BMU_ID_0
 SG_ Output_5_state m0 : 36|1@0+ (1,0) [0|0] ""  BMU_ID_0
 SG_ Output_6_state m0 : 37|1@0+ (1,0) [0|0] ""  BMU_ID_0
 SG_ Input_6_state m0 : 21|1@0+ (1,0) [0|0] ""  BMU_ID_0
 SG_ Input_7_state m0 : 22|1@0+ (1,0) [0|0] ""  BMU_ID_0
 SG_ Input_8_state m0 : 23|1@0+ (1,0) [0|0] ""  BMU_ID_0
 SG_ Input_9_state m0 : 24|1@0+ (1,0) [0|0] ""  BMU_ID_0
 SG_ Input_10_state m0 : 25|1@0+ (1,0) [0|0] ""  BMU_ID_0
 SG_ Input_11_state m0 : 26|1@0+ (1,0) [0|0] ""  BMU_ID_0
 SG_ Input_12_state m0 : 27|1@0+ (1,0) [0|0] ""  BMU_ID_0
 SG_ Output_7_state m0 : 38|1@0+ (1,0) [0|0] ""  BMU_ID_0
 SG_ Output_8_state m0 : 39|1@0+ (1,0) [0|0] ""  BMU_ID_0
 SG_ Output_9_state m0 : 40|1@0+ (1,0) [0|0] ""  BMU_ID_0
 SG_ Output_10_state m0 : 41|1@0+ (1,0) [0|0] ""  BMU_ID_0
 SG_ Output_11_state m0 : 42|1@0+ (1,0) [0|0] ""  BMU_ID_0
 SG_ Output_12_state m0 : 43|1@0+ (1,0) [0|0] ""  BMU_ID_0
 SG_ Output_13_state m0 : 44|1@0+ (1,0) [0|0] ""  BMU_ID_0
 SG_ Analog_input_1 m1 : 15|16@0+ (1,0) [0|0] "mV"  BMU_ID_0
 SG_ Analog_input_2 m1 : 31|16@0+ (1,0) [0|0] "mV"  BMU_ID_0
 SG_ Analog_input_3 m1 : 47|16@0+ (1,0) [0|0] "mV"  BMU_ID_0

BO_ 1498 wBMU_ID_10_msg_13_io: 8 BMU_ID_10
 SG_ Content_ID M : 7|8@0+ (1,0) [0|0] ""  BMU_ID_0
 SG_ Positive_power_relay_status m0 : 8|1@0+ (1,0) [0|0] ""  BMU_ID_0
 SG_ Negative_power_relay_status m0 : 9|1@0+ (1,0) [0|0] ""  BMU_ID_0
 SG_ Precharge_power_relay_status m0 : 10|1@0+ (1,0) [0|0] ""  BMU_ID_0
 SG_ Middle_power_relay_status m0 : 11|1@0+ (1,0) [0|0] ""  BMU_ID_0
 SG_ Sleep_mode_request_flag m0 : 12|1@0+ (1,0) [0|0] ""  BMU_ID_0
 SG_ Emergency_button_alarm_flag m0 : 13|1@0+ (1,0) [0|0] ""  BMU_ID_0
 SG_ Start_signal_interlock_flag m0 : 14|1@0+ (1,0) [0|0] ""  BMU_ID_0
 SG_ Start_signal_actuation_req_flag m0 : 15|1@0+ (1,0) [0|0] ""  BMU_ID_0
 SG_ Heating_pad_request_flag m0 : 48|1@0+ (1,0) [0|0] ""  BMU_ID_0
 SG_ Input_1_state m0 : 16|1@0+ (1,0) [0|0] ""  BMU_ID_0
 SG_ Input_2_state m0 : 17|1@0+ (1,0) [0|0] ""  BMU_ID_0
 SG_ Input_3_state m0 : 18|1@0+ (1,0) [0|0] ""  BMU_ID_0
 SG_ Input_4_state m0 : 19|1@0+ (1,0) [0|0] ""  BMU_ID_0
 SG_ Input_5_state m0 : 20|1@0+ (1,0) [0|0] ""  BMU_ID_0
 SG_ Output_1_state m0 : 32|1@0+ (1,0) [0|0] ""  BMU_ID_0
 SG_ Output_2_state m0 : 33|1@0+ (1,0) [0|0] ""  BMU_ID_0
 SG_ Output_3_state m0 : 34|1@0+ (1,0) [0|0] ""  BMU_ID_0
 SG_ Output_4_state m0 : 35|1@0+ (1,0) [0|0] ""  BMU_ID_0
 SG_ Output_5_state m0 : 36|1@0+ (1,0) [0|0] ""  BMU_ID_0
 SG_ Output_6_state m0 : 37|1@0+ (1,0) [0|0] ""  BMU_ID_0
 SG_ Input_6_state m0 : 21|1@0+ (1,0) [0|0] ""  BMU_ID_0
 SG_ Input_7_state m0 : 22|1@0+ (1,0) [0|0] ""  BMU_ID_0
 SG_ Input_8_state m0 : 23|1@0+ (1,0) [0|0] ""  BMU_ID_0
 SG_ Input_9_state m0 : 24|1@0+ (1,0) [0|0] ""  BMU_ID_0
 SG_ Input_10_state m0 : 25|1@0+ (1,0) [0|0] ""  BMU_ID_0
 SG_ Input_11_state m0 : 26|1@0+ (1,0) [0|0] ""  BMU_ID_0
 SG_ Input_12_state m0 : 27|1@0+ (1,0) [0|0] ""  BMU_ID_0
 SG_ Output_7_state m0 : 38|1@0+ (1,0) [0|0] ""  BMU_ID_0
 SG_ Output_8_state m0 : 39|1@0+ (1,0) [0|0] ""  BMU_ID_0
 SG_ Output_9_state m0 : 40|1@0+ (1,0) [0|0] ""  BMU_ID_0
 SG_ Output_10_state m0 : 41|1@0+ (1,0) [0|0] ""  BMU_ID_0
 SG_ Output_11_state m0 : 42|1@0+ (1,0) [0|0] ""  BMU_ID_0
 SG_ Output_12_state m0 : 43|1@0+ (1,0) [0|0] ""  BMU_ID_0
 SG_ Output_13_state m0 : 44|1@0+ (1,0) [0|0] ""  BMU_ID_0
 SG_ Analog_input_1 m1 : 15|16@0+ (1,0) [0|0] "mV"  BMU_ID_0
 SG_ Analog_input_2 m1 : 31|16@0+ (1,0) [0|0] "mV"  BMU_ID_0
 SG_ Analog_input_3 m1 : 47|16@0+ (1,0) [0|0] "mV"  BMU_ID_0

BO_ 1499 wBMU_ID_11_msg_13_io: 8 BMU_ID_11
 SG_ Content_ID M : 7|8@0+ (1,0) [0|0] ""  BMU_ID_0
 SG_ Positive_power_relay_status m0 : 8|1@0+ (1,0) [0|0] ""  BMU_ID_0
 SG_ Negative_power_relay_status m0 : 9|1@0+ (1,0) [0|0] ""  BMU_ID_0
 SG_ Precharge_power_relay_status m0 : 10|1@0+ (1,0) [0|0] ""  BMU_ID_0
 SG_ Middle_power_relay_status m0 : 11|1@0+ (1,0) [0|0] ""  BMU_ID_0
 SG_ Sleep_mode_request_flag m0 : 12|1@0+ (1,0) [0|0] ""  BMU_ID_0
 SG_ Emergency_button_alarm_flag m0 : 13|1@0+ (1,0) [0|0] ""  BMU_ID_0
 SG_ Start_signal_interlock_flag m0 : 14|1@0+ (1,0) [0|0] ""  BMU_ID_0
 SG_ Start_signal_actuation_req_flag m0 : 15|1@0+ (1,0) [0|0] ""  BMU_ID_0
 SG_ Heating_pad_request_flag m0 : 48|1@0+ (1,0) [0|0] ""  BMU_ID_0
 SG_ Input_1_state m0 : 16|1@0+ (1,0) [0|0] ""  BMU_ID_0
 SG_ Input_2_state m0 : 17|1@0+ (1,0) [0|0] ""  BMU_ID_0
 SG_ Input_3_state m0 : 18|1@0+ (1,0) [0|0] ""  BMU_ID_0
 SG_ Input_4_state m0 : 19|1@0+ (1,0) [0|0] ""  BMU_ID_0
 SG_ Input_5_state m0 : 20|1@0+ (1,0) [0|0] ""  BMU_ID_0
 SG_ Output_1_state m0 : 32|1@0+ (1,0) [0|0] ""  BMU_ID_0
 SG_ Output_2_state m0 : 33|1@0+ (1,0) [0|0] ""  BMU_ID_0
 SG_ Output_3_state m0 : 34|1@0+ (1,0) [0|0] ""  BMU_ID_0
 SG_ Output_4_state m0 : 35|1@0+ (1,0) [0|0] ""  BMU_ID_0
 SG_ Output_5_state m0 : 36|1@0+ (1,0) [0|0] ""  BMU_ID_0
 SG_ Output_6_state m0 : 37|1@0+ (1,0) [0|0] ""  BMU_ID_0
 SG_ Input_6_state m0 : 21|1@0+ (1,0) [0|0] ""  BMU_ID_0
 SG_ Input_7_state m0 : 22|1@0+ (1,0) [0|0] ""  BMU_ID_0
 SG_ Input_8_state m0 : 23|1@0+ (1,0) [0|0] ""  BMU_ID_0
 SG_ Input_9_state m0 : 24|1@0+ (1,0) [0|0] ""  BMU_ID_0
 SG_ Input_10_state m0 : 25|1@0+ (1,0) [0|0] ""  BMU_ID_0
 SG_ Input_11_state m0 : 26|1@0+ (1,0) [0|0] ""  BMU_ID_0
 SG_ Input_12_state m0 : 27|1@0+ (1,0) [0|0] ""  BMU_ID_0
 SG_ Output_7_state m0 : 38|1@0+ (1,0) [0|0] ""  BMU_ID_0
 SG_ Output_8_state m0 : 39|1@0+ (1,0) [0|0] ""  BMU_ID_0
 SG_ Output_9_state m0 : 40|1@0+ (1,0) [0|0] ""  BMU_ID_0
 SG_ Output_10_state m0 : 41|1@0+ (1,0) [0|0] ""  BMU_ID_0
 SG_ Output_11_state m0 : 42|1@0+ (1,0) [0|0] ""  BMU_ID_0
 SG_ Output_12_state m0 : 43|1@0+ (1,0) [0|0] ""  BMU_ID_0
 SG_ Output_13_state m0 : 44|1@0+ (1,0) [0|0] ""  BMU_ID_0
 SG_ Analog_input_1 m1 : 15|16@0+ (1,0) [0|0] "mV"  BMU_ID_0
 SG_ Analog_input_2 m1 : 31|16@0+ (1,0) [0|0] "mV"  BMU_ID_0
 SG_ Analog_input_3 m1 : 47|16@0+ (1,0) [0|0] "mV"  BMU_ID_0

BO_ 1500 wBMU_ID_12_msg_13_io: 8 BMU_ID_12
 SG_ Content_ID M : 7|8@0+ (1,0) [0|0] ""  BMU_ID_0
 SG_ Positive_power_relay_status m0 : 8|1@0+ (1,0) [0|0] ""  BMU_ID_0
 SG_ Negative_power_relay_status m0 : 9|1@0+ (1,0) [0|0] ""  BMU_ID_0
 SG_ Precharge_power_relay_status m0 : 10|1@0+ (1,0) [0|0] ""  BMU_ID_0
 SG_ Middle_power_relay_status m0 : 11|1@0+ (1,0) [0|0] ""  BMU_ID_0
 SG_ Sleep_mode_request_flag m0 : 12|1@0+ (1,0) [0|0] ""  BMU_ID_0
 SG_ Emergency_button_alarm_flag m0 : 13|1@0+ (1,0) [0|0] ""  BMU_ID_0
 SG_ Start_signal_interlock_flag m0 : 14|1@0+ (1,0) [0|0] ""  BMU_ID_0
 SG_ Start_signal_actuation_req_flag m0 : 15|1@0+ (1,0) [0|0] ""  BMU_ID_0
 SG_ Heating_pad_request_flag m0 : 48|1@0+ (1,0) [0|0] ""  BMU_ID_0
 SG_ Input_1_state m0 : 16|1@0+ (1,0) [0|0] ""  BMU_ID_0
 SG_ Input_2_state m0 : 17|1@0+ (1,0) [0|0] ""  BMU_ID_0
 SG_ Input_3_state m0 : 18|1@0+ (1,0) [0|0] ""  BMU_ID_0
 SG_ Input_4_state m0 : 19|1@0+ (1,0) [0|0] ""  BMU_ID_0
 SG_ Input_5_state m0 : 20|1@0+ (1,0) [0|0] ""  BMU_ID_0
 SG_ Output_1_state m0 : 32|1@0+ (1,0) [0|0] ""  BMU_ID_0
 SG_ Output_2_state m0 : 33|1@0+ (1,0) [0|0] ""  BMU_ID_0
 SG_ Output_3_state m0 : 34|1@0+ (1,0) [0|0] ""  BMU_ID_0
 SG_ Output_4_state m0 : 35|1@0+ (1,0) [0|0] ""  BMU_ID_0
 SG_ Output_5_state m0 : 36|1@0+ (1,0) [0|0] ""  BMU_ID_0
 SG_ Output_6_state m0 : 37|1@0+ (1,0) [0|0] ""  BMU_ID_0
 SG_ Input_6_state m0 : 21|1@0+ (1,0) [0|0] ""  BMU_ID_0
 SG_ Input_7_state m0 : 22|1@0+ (1,0) [0|0] ""  BMU_ID_0
 SG_ Input_8_state m0 : 23|1@0+ (1,0) [0|0] ""  BMU_ID_0
 SG_ Input_9_state m0 : 24|1@0+ (1,0) [0|0] ""  BMU_ID_0
 SG_ Input_10_state m0 : 25|1@0+ (1,0) [0|0] ""  BMU_ID_0
 SG_ Input_11_state m0 : 26|1@0+ (1,0) [0|0] ""  BMU_ID_0
 SG_ Input_12_state m0 : 27|1@0+ (1,0) [0|0] ""  BMU_ID_0
 SG_ Output_7_state m0 : 38|1@0+ (1,0) [0|0] ""  BMU_ID_0
 SG_ Output_8_state m0 : 39|1@0+ (1,0) [0|0] ""  BMU_ID_0
 SG_ Output_9_state m0 : 40|1@0+ (1,0) [0|0] ""  BMU_ID_0
 SG_ Output_10_state m0 : 41|1@0+ (1,0) [0|0] ""  BMU_ID_0
 SG_ Output_11_state m0 : 42|1@0+ (1,0) [0|0] ""  BMU_ID_0
 SG_ Output_12_state m0 : 43|1@0+ (1,0) [0|0] ""  BMU_ID_0
 SG_ Output_13_state m0 : 44|1@0+ (1,0) [0|0] ""  BMU_ID_0
 SG_ Analog_input_1 m1 : 15|16@0+ (1,0) [0|0] "mV"  BMU_ID_0
 SG_ Analog_input_2 m1 : 31|16@0+ (1,0) [0|0] "mV"  BMU_ID_0
 SG_ Analog_input_3 m1 : 47|16@0+ (1,0) [0|0] "mV"  BMU_ID_0

BO_ 1501 wBMU_ID_13_msg_13_io: 8 BMU_ID_13
 SG_ Content_ID M : 7|8@0+ (1,0) [0|0] ""  BMU_ID_0
 SG_ Positive_power_relay_status m0 : 8|1@0+ (1,0) [0|0] ""  BMU_ID_0
 SG_ Negative_power_relay_status m0 : 9|1@0+ (1,0) [0|0] ""  BMU_ID_0
 SG_ Precharge_power_relay_status m0 : 10|1@0+ (1,0) [0|0] ""  BMU_ID_0
 SG_ Middle_power_relay_status m0 : 11|1@0+ (1,0) [0|0] ""  BMU_ID_0
 SG_ Sleep_mode_request_flag m0 : 12|1@0+ (1,0) [0|0] ""  BMU_ID_0
 SG_ Emergency_button_alarm_flag m0 : 13|1@0+ (1,0) [0|0] ""  BMU_ID_0
 SG_ Start_signal_interlock_flag m0 : 14|1@0+ (1,0) [0|0] ""  BMU_ID_0
 SG_ Start_signal_actuation_req_flag m0 : 15|1@0+ (1,0) [0|0] ""  BMU_ID_0
 SG_ Heating_pad_request_flag m0 : 48|1@0+ (1,0) [0|0] ""  BMU_ID_0
 SG_ Input_1_state m0 : 16|1@0+ (1,0) [0|0] ""  BMU_ID_0
 SG_ Input_2_state m0 : 17|1@0+ (1,0) [0|0] ""  BMU_ID_0
 SG_ Input_3_state m0 : 18|1@0+ (1,0) [0|0] ""  BMU_ID_0
 SG_ Input_4_state m0 : 19|1@0+ (1,0) [0|0] ""  BMU_ID_0
 SG_ Input_5_state m0 : 20|1@0+ (1,0) [0|0] ""  BMU_ID_0
 SG_ Output_1_state m0 : 32|1@0+ (1,0) [0|0] ""  BMU_ID_0
 SG_ Output_2_state m0 : 33|1@0+ (1,0) [0|0] ""  BMU_ID_0
 SG_ Output_3_state m0 : 34|1@0+ (1,0) [0|0] ""  BMU_ID_0
 SG_ Output_4_state m0 : 35|1@0+ (1,0) [0|0] ""  BMU_ID_0
 SG_ Output_5_state m0 : 36|1@0+ (1,0) [0|0] ""  BMU_ID_0
 SG_ Output_6_state m0 : 37|1@0+ (1,0) [0|0] ""  BMU_ID_0
 SG_ Input_6_state m0 : 21|1@0+ (1,0) [0|0] ""  BMU_ID_0
 SG_ Input_7_state m0 : 22|1@0+ (1,0) [0|0] ""  BMU_ID_0
 SG_ Input_8_state m0 : 23|1@0+ (1,0) [0|0] ""  BMU_ID_0
 SG_ Input_9_state m0 : 24|1@0+ (1,0) [0|0] ""  BMU_ID_0
 SG_ Input_10_state m0 : 25|1@0+ (1,0) [0|0] ""  BMU_ID_0
 SG_ Input_11_state m0 : 26|1@0+ (1,0) [0|0] ""  BMU_ID_0
 SG_ Input_12_state m0 : 27|1@0+ (1,0) [0|0] ""  BMU_ID_0
 SG_ Output_7_state m0 : 38|1@0+ (1,0) [0|0] ""  BMU_ID_0
 SG_ Output_8_state m0 : 39|1@0+ (1,0) [0|0] ""  BMU_ID_0
 SG_ Output_9_state m0 : 40|1@0+ (1,0) [0|0] ""  BMU_ID_0
 SG_ Output_10_state m0 : 41|1@0+ (1,0) [0|0] ""  BMU_ID_0
 SG_ Output_11_state m0 : 42|1@0+ (1,0) [0|0] ""  BMU_ID_0
 SG_ Output_12_state m0 : 43|1@0+ (1,0) [0|0] ""  BMU_ID_0
 SG_ Output_13_state m0 : 44|1@0+ (1,0) [0|0] ""  BMU_ID_0
 SG_ Analog_input_1 m1 : 15|16@0+ (1,0) [0|0] "mV"  BMU_ID_0
 SG_ Analog_input_2 m1 : 31|16@0+ (1,0) [0|0] "mV"  BMU_ID_0
 SG_ Analog_input_3 m1 : 47|16@0+ (1,0) [0|0] "mV"  BMU_ID_0

BO_ 1502 wBMU_ID_14_msg_13_io: 8 BMU_ID_14
 SG_ Content_ID M : 7|8@0+ (1,0) [0|0] ""  BMU_ID_0
 SG_ Positive_power_relay_status m0 : 8|1@0+ (1,0) [0|0] ""  BMU_ID_0
 SG_ Negative_power_relay_status m0 : 9|1@0+ (1,0) [0|0] ""  BMU_ID_0
 SG_ Precharge_power_relay_status m0 : 10|1@0+ (1,0) [0|0] ""  BMU_ID_0
 SG_ Middle_power_relay_status m0 : 11|1@0+ (1,0) [0|0] ""  BMU_ID_0
 SG_ Sleep_mode_request_flag m0 : 12|1@0+ (1,0) [0|0] ""  BMU_ID_0
 SG_ Emergency_button_alarm_flag m0 : 13|1@0+ (1,0) [0|0] ""  BMU_ID_0
 SG_ Start_signal_interlock_flag m0 : 14|1@0+ (1,0) [0|0] ""  BMU_ID_0
 SG_ Start_signal_actuation_req_flag m0 : 15|1@0+ (1,0) [0|0] ""  BMU_ID_0
 SG_ Heating_pad_request_flag m0 : 48|1@0+ (1,0) [0|0] ""  BMU_ID_0
 SG_ Input_1_state m0 : 16|1@0+ (1,0) [0|0] ""  BMU_ID_0
 SG_ Input_2_state m0 : 17|1@0+ (1,0) [0|0] ""  BMU_ID_0
 SG_ Input_3_state m0 : 18|1@0+ (1,0) [0|0] ""  BMU_ID_0
 SG_ Input_4_state m0 : 19|1@0+ (1,0) [0|0] ""  BMU_ID_0
 SG_ Input_5_state m0 : 20|1@0+ (1,0) [0|0] ""  BMU_ID_0
 SG_ Output_1_state m0 : 32|1@0+ (1,0) [0|0] ""  BMU_ID_0
 SG_ Output_2_state m0 : 33|1@0+ (1,0) [0|0] ""  BMU_ID_0
 SG_ Output_3_state m0 : 34|1@0+ (1,0) [0|0] ""  BMU_ID_0
 SG_ Output_4_state m0 : 35|1@0+ (1,0) [0|0] ""  BMU_ID_0
 SG_ Output_5_state m0 : 36|1@0+ (1,0) [0|0] ""  BMU_ID_0
 SG_ Output_6_state m0 : 37|1@0+ (1,0) [0|0] ""  BMU_ID_0
 SG_ Input_6_state m0 : 21|1@0+ (1,0) [0|0] ""  BMU_ID_0
 SG_ Input_7_state m0 : 22|1@0+ (1,0) [0|0] ""  BMU_ID_0
 SG_ Input_8_state m0 : 23|1@0+ (1,0) [0|0] ""  BMU_ID_0
 SG_ Input_9_state m0 : 24|1@0+ (1,0) [0|0] ""  BMU_ID_0
 SG_ Input_10_state m0 : 25|1@0+ (1,0) [0|0] ""  BMU_ID_0
 SG_ Input_11_state m0 : 26|1@0+ (1,0) [0|0] ""  BMU_ID_0
 SG_ Input_12_state m0 : 27|1@0+ (1,0) [0|0] ""  BMU_ID_0
 SG_ Output_7_state m0 : 38|1@0+ (1,0) [0|0] ""  BMU_ID_0
 SG_ Output_8_state m0 : 39|1@0+ (1,0) [0|0] ""  BMU_ID_0
 SG_ Output_9_state m0 : 40|1@0+ (1,0) [0|0] ""  BMU_ID_0
 SG_ Output_10_state m0 : 41|1@0+ (1,0) [0|0] ""  BMU_ID_0
 SG_ Output_11_state m0 : 42|1@0+ (1,0) [0|0] ""  BMU_ID_0
 SG_ Output_12_state m0 : 43|1@0+ (1,0) [0|0] ""  BMU_ID_0
 SG_ Output_13_state m0 : 44|1@0+ (1,0) [0|0] ""  BMU_ID_0
 SG_ Analog_input_1 m1 : 15|16@0+ (1,0) [0|0] "mV"  BMU_ID_0
 SG_ Analog_input_2 m1 : 31|16@0+ (1,0) [0|0] "mV"  BMU_ID_0
 SG_ Analog_input_3 m1 : 47|16@0+ (1,0) [0|0] "mV"  BMU_ID_0

BO_ 1503 wBMU_ID_15_msg_13_io: 8 BMU_ID_15
 SG_ Content_ID M : 7|8@0+ (1,0) [0|0] ""  BMU_ID_0
 SG_ Positive_power_relay_status m0 : 8|1@0+ (1,0) [0|0] ""  BMU_ID_0
 SG_ Negative_power_relay_status m0 : 9|1@0+ (1,0) [0|0] ""  BMU_ID_0
 SG_ Precharge_power_relay_status m0 : 10|1@0+ (1,0) [0|0] ""  BMU_ID_0
 SG_ Middle_power_relay_status m0 : 11|1@0+ (1,0) [0|0] ""  BMU_ID_0
 SG_ Sleep_mode_request_flag m0 : 12|1@0+ (1,0) [0|0] ""  BMU_ID_0
 SG_ Emergency_button_alarm_flag m0 : 13|1@0+ (1,0) [0|0] ""  BMU_ID_0
 SG_ Start_signal_interlock_flag m0 : 14|1@0+ (1,0) [0|0] ""  BMU_ID_0
 SG_ Start_signal_actuation_req_flag m0 : 15|1@0+ (1,0) [0|0] ""  BMU_ID_0
 SG_ Heating_pad_request_flag m0 : 48|1@0+ (1,0) [0|0] ""  BMU_ID_0
 SG_ Input_1_state m0 : 16|1@0+ (1,0) [0|0] ""  BMU_ID_0
 SG_ Input_2_state m0 : 17|1@0+ (1,0) [0|0] ""  BMU_ID_0
 SG_ Input_3_state m0 : 18|1@0+ (1,0) [0|0] ""  BMU_ID_0
 SG_ Input_4_state m0 : 19|1@0+ (1,0) [0|0] ""  BMU_ID_0
 SG_ Input_5_state m0 : 20|1@0+ (1,0) [0|0] ""  BMU_ID_0
 SG_ Output_1_state m0 : 32|1@0+ (1,0) [0|0] ""  BMU_ID_0
 SG_ Output_2_state m0 : 33|1@0+ (1,0) [0|0] ""  BMU_ID_0
 SG_ Output_3_state m0 : 34|1@0+ (1,0) [0|0] ""  BMU_ID_0
 SG_ Output_4_state m0 : 35|1@0+ (1,0) [0|0] ""  BMU_ID_0
 SG_ Output_5_state m0 : 36|1@0+ (1,0) [0|0] ""  BMU_ID_0
 SG_ Output_6_state m0 : 37|1@0+ (1,0) [0|0] ""  BMU_ID_0
 SG_ Input_6_state m0 : 21|1@0+ (1,0) [0|0] ""  BMU_ID_0
 SG_ Input_7_state m0 : 22|1@0+ (1,0) [0|0] ""  BMU_ID_0
 SG_ Input_8_state m0 : 23|1@0+ (1,0) [0|0] ""  BMU_ID_0
 SG_ Input_9_state m0 : 24|1@0+ (1,0) [0|0] ""  BMU_ID_0
 SG_ Input_10_state m0 : 25|1@0+ (1,0) [0|0] ""  BMU_ID_0
 SG_ Input_11_state m0 : 26|1@0+ (1,0) [0|0] ""  BMU_ID_0
 SG_ Input_12_state m0 : 27|1@0+ (1,0) [0|0] ""  BMU_ID_0
 SG_ Output_7_state m0 : 38|1@0+ (1,0) [0|0] ""  BMU_ID_0
 SG_ Output_8_state m0 : 39|1@0+ (1,0) [0|0] ""  BMU_ID_0
 SG_ Output_9_state m0 : 40|1@0+ (1,0) [0|0] ""  BMU_ID_0
 SG_ Output_10_state m0 : 41|1@0+ (1,0) [0|0] ""  BMU_ID_0
 SG_ Output_11_state m0 : 42|1@0+ (1,0) [0|0] ""  BMU_ID_0
 SG_ Output_12_state m0 : 43|1@0+ (1,0) [0|0] ""  BMU_ID_0
 SG_ Output_13_state m0 : 44|1@0+ (1,0) [0|0] ""  BMU_ID_0
 SG_ Analog_input_1 m1 : 15|16@0+ (1,0) [0|0] "mV"  BMU_ID_0
 SG_ Analog_input_2 m1 : 31|16@0+ (1,0) [0|0] "mV"  BMU_ID_0
 SG_ Analog_input_3 m1 : 47|16@0+ (1,0) [0|0] "mV"  BMU_ID_0

BO_ 1504 wBMU_ID_0_msg_14_maximeters: 8 BMU_ID_0
 SG_ Content_ID M : 7|8@0+ (1,0) [0|0] ""  BMU_ID_0
 SG_ Remaining_capacity m0 : 15|16@0+ (1,0) [0|0] "Ah"  BMU_ID_0
 SG_ Contactors_opened_under_load_cnt m0 : 31|24@0+ (1,0) [0|0] "-"  BMU_ID_0
 SG_ Equivalent_cycles m1 : 15|16@0+ (1,0) [0|0] "- "  BMU_ID_0
 SG_ Cycles_since_fully_charged m1 : 31|16@0+ (1,0) [0|0] "- "  BMU_ID_0
 SG_ Fully_charged_counter m1 : 47|16@0+ (1,0) [0|0] "- "  BMU_ID_0
 SG_ Total_charged_energy m2 : 15|24@0+ (1,0) [0|0] "kWh"  BMU_ID_0
 SG_ Total_discharged_energy m2 : 39|24@0+ (1,0) [0|0] "kWh"  BMU_ID_0
 SG_ Overvoltage_protection_counter m2 : 63|8@0+ (1,0) [0|0] "-"  BMU_ID_0
 SG_ Total_charged_capacity m3 : 15|32@0+ (0.1,0) [0|0] "Ah"  BMU_ID_0
 SG_ Fully_discharged_counter m3 : 47|16@0+ (1,0) [0|0] ""  BMU_ID_0
 SG_ Overcurrent_protection_counter m3 : 63|8@0+ (1,0) [0|0] ""  BMU_ID_0
 SG_ Total_discharged_capacity m4 : 15|32@0+ (0.1,0) [0|0] "Ah"  BMU_ID_0
 SG_ Overtemperature_protection_count m4 : 47|8@0+ (1,0) [0|0] ""  BMU_ID_0
 SG_ Undertemperature_protection_coun m4 : 55|8@0+ (1,0) [0|0] ""  BMU_ID_0
 SG_ Undervoltage_protection_counter m4 : 63|8@0+ (1,0) [0|0] ""  BMU_ID_0

BO_ 1505 wBMU_ID_1_msg_14_maximeters: 8 BMU_ID_1
 SG_ Content_ID M : 7|8@0+ (1,0) [0|0] ""  BMU_ID_0
 SG_ Remaining_capacity m0 : 15|16@0+ (1,0) [0|0] "Ah"  BMU_ID_0
 SG_ Contactors_opened_under_load_cnt m0 : 31|24@0+ (1,0) [0|0] "-"  BMU_ID_0
 SG_ Equivalent_cycles m1 : 15|16@0+ (1,0) [0|0] "- "  BMU_ID_0
 SG_ Cycles_since_fully_charged m1 : 31|16@0+ (1,0) [0|0] "- "  BMU_ID_0
 SG_ Fully_charged_counter m1 : 47|16@0+ (1,0) [0|0] "- "  BMU_ID_0
 SG_ Total_charged_energy m2 : 15|24@0+ (1,0) [0|0] "kWh"  BMU_ID_0
 SG_ Total_discharged_energy m2 : 39|24@0+ (1,0) [0|0] "kWh"  BMU_ID_0
 SG_ Overvoltage_protection_counter m2 : 63|8@0+ (1,0) [0|0] "-"  BMU_ID_0
 SG_ Total_charged_capacity m3 : 15|32@0+ (0.1,0) [0|0] "Ah"  BMU_ID_0
 SG_ Fully_discharged_counter m3 : 47|16@0+ (1,0) [0|0] ""  BMU_ID_0
 SG_ Overcurrent_protection_counter m3 : 63|8@0+ (1,0) [0|0] ""  BMU_ID_0
 SG_ Total_discharged_capacity m4 : 15|32@0+ (0.1,0) [0|0] "Ah"  BMU_ID_0
 SG_ Overtemperature_protection_count m4 : 47|8@0+ (1,0) [0|0] ""  BMU_ID_0
 SG_ Undertemperature_protection_coun m4 : 55|8@0+ (1,0) [0|0] ""  BMU_ID_0
 SG_ Undervoltage_protection_counter m4 : 63|8@0+ (1,0) [0|0] ""  BMU_ID_0

BO_ 1506 wBMU_ID_2_msg_14_maximeters: 8 BMU_ID_2
 SG_ Content_ID M : 7|8@0+ (1,0) [0|0] ""  BMU_ID_0
 SG_ Remaining_capacity m0 : 15|16@0+ (1,0) [0|0] "Ah"  BMU_ID_0
 SG_ Contactors_opened_under_load_cnt m0 : 31|24@0+ (1,0) [0|0] "-"  BMU_ID_0
 SG_ Equivalent_cycles m1 : 15|16@0+ (1,0) [0|0] "- "  BMU_ID_0
 SG_ Cycles_since_fully_charged m1 : 31|16@0+ (1,0) [0|0] "- "  BMU_ID_0
 SG_ Fully_charged_counter m1 : 47|16@0+ (1,0) [0|0] "- "  BMU_ID_0
 SG_ Total_charged_energy m2 : 15|24@0+ (1,0) [0|0] "kWh"  BMU_ID_0
 SG_ Total_discharged_energy m2 : 39|24@0+ (1,0) [0|0] "kWh"  BMU_ID_0
 SG_ Overvoltage_protection_counter m2 : 63|8@0+ (1,0) [0|0] "-"  BMU_ID_0
 SG_ Total_charged_capacity m3 : 15|32@0+ (0.1,0) [0|0] "Ah"  BMU_ID_0
 SG_ Fully_discharged_counter m3 : 47|16@0+ (1,0) [0|0] ""  BMU_ID_0
 SG_ Overcurrent_protection_counter m3 : 63|8@0+ (1,0) [0|0] ""  BMU_ID_0
 SG_ Total_discharged_capacity m4 : 15|32@0+ (0.1,0) [0|0] "Ah"  BMU_ID_0
 SG_ Overtemperature_protection_count m4 : 47|8@0+ (1,0) [0|0] ""  BMU_ID_0
 SG_ Undertemperature_protection_coun m4 : 55|8@0+ (1,0) [0|0] ""  BMU_ID_0
 SG_ Undervoltage_protection_counter m4 : 63|8@0+ (1,0) [0|0] ""  BMU_ID_0

BO_ 1507 wBMU_ID_3_msg_14_maximeters: 8 BMU_ID_3
 SG_ Content_ID M : 7|8@0+ (1,0) [0|0] ""  BMU_ID_0
 SG_ Remaining_capacity m0 : 15|16@0+ (1,0) [0|0] "Ah"  BMU_ID_0
 SG_ Contactors_opened_under_load_cnt m0 : 31|24@0+ (1,0) [0|0] "-"  BMU_ID_0
 SG_ Equivalent_cycles m1 : 15|16@0+ (1,0) [0|0] "- "  BMU_ID_0
 SG_ Cycles_since_fully_charged m1 : 31|16@0+ (1,0) [0|0] "- "  BMU_ID_0
 SG_ Fully_charged_counter m1 : 47|16@0+ (1,0) [0|0] "- "  BMU_ID_0
 SG_ Total_charged_energy m2 : 15|24@0+ (1,0) [0|0] "kWh"  BMU_ID_0
 SG_ Total_discharged_energy m2 : 39|24@0+ (1,0) [0|0] "kWh"  BMU_ID_0
 SG_ Overvoltage_protection_counter m2 : 63|8@0+ (1,0) [0|0] "-"  BMU_ID_0
 SG_ Total_charged_capacity m3 : 15|32@0+ (0.1,0) [0|0] "Ah"  BMU_ID_0
 SG_ Fully_discharged_counter m3 : 47|16@0+ (1,0) [0|0] ""  BMU_ID_0
 SG_ Overcurrent_protection_counter m3 : 63|8@0+ (1,0) [0|0] ""  BMU_ID_0
 SG_ Total_discharged_capacity m4 : 15|32@0+ (0.1,0) [0|0] "Ah"  BMU_ID_0
 SG_ Overtemperature_protection_count m4 : 47|8@0+ (1,0) [0|0] ""  BMU_ID_0
 SG_ Undertemperature_protection_coun m4 : 55|8@0+ (1,0) [0|0] ""  BMU_ID_0
 SG_ Undervoltage_protection_counter m4 : 63|8@0+ (1,0) [0|0] ""  BMU_ID_0

BO_ 1508 wBMU_ID_4_msg_14_maximeters: 8 BMU_ID_4
 SG_ Content_ID M : 7|8@0+ (1,0) [0|0] ""  BMU_ID_0
 SG_ Remaining_capacity m0 : 15|16@0+ (1,0) [0|0] "Ah"  BMU_ID_0
 SG_ Contactors_opened_under_load_cnt m0 : 31|24@0+ (1,0) [0|0] "-"  BMU_ID_0
 SG_ Equivalent_cycles m1 : 15|16@0+ (1,0) [0|0] "- "  BMU_ID_0
 SG_ Cycles_since_fully_charged m1 : 31|16@0+ (1,0) [0|0] "- "  BMU_ID_0
 SG_ Fully_charged_counter m1 : 47|16@0+ (1,0) [0|0] "- "  BMU_ID_0
 SG_ Total_charged_energy m2 : 15|24@0+ (1,0) [0|0] "kWh"  BMU_ID_0
 SG_ Total_discharged_energy m2 : 39|24@0+ (1,0) [0|0] "kWh"  BMU_ID_0
 SG_ Overvoltage_protection_counter m2 : 63|8@0+ (1,0) [0|0] "-"  BMU_ID_0
 SG_ Total_charged_capacity m3 : 15|32@0+ (0.1,0) [0|0] "Ah"  BMU_ID_0
 SG_ Fully_discharged_counter m3 : 47|16@0+ (1,0) [0|0] ""  BMU_ID_0
 SG_ Overcurrent_protection_counter m3 : 63|8@0+ (1,0) [0|0] ""  BMU_ID_0
 SG_ Total_discharged_capacity m4 : 15|32@0+ (0.1,0) [0|0] "Ah"  BMU_ID_0
 SG_ Overtemperature_protection_count m4 : 47|8@0+ (1,0) [0|0] ""  BMU_ID_0
 SG_ Undertemperature_protection_coun m4 : 55|8@0+ (1,0) [0|0] ""  BMU_ID_0
 SG_ Undervoltage_protection_counter m4 : 63|8@0+ (1,0) [0|0] ""  BMU_ID_0

BO_ 1509 wBMU_ID_5_msg_14_maximeters: 8 BMU_ID_5
 SG_ Content_ID M : 7|8@0+ (1,0) [0|0] ""  BMU_ID_0
 SG_ Remaining_capacity m0 : 15|16@0+ (1,0) [0|0] "Ah"  BMU_ID_0
 SG_ Contactors_opened_under_load_cnt m0 : 31|24@0+ (1,0) [0|0] "-"  BMU_ID_0
 SG_ Equivalent_cycles m1 : 15|16@0+ (1,0) [0|0] "- "  BMU_ID_0
 SG_ Cycles_since_fully_charged m1 : 31|16@0+ (1,0) [0|0] "- "  BMU_ID_0
 SG_ Fully_charged_counter m1 : 47|16@0+ (1,0) [0|0] "- "  BMU_ID_0
 SG_ Total_charged_energy m2 : 15|24@0+ (1,0) [0|0] "kWh"  BMU_ID_0
 SG_ Total_discharged_energy m2 : 39|24@0+ (1,0) [0|0] "kWh"  BMU_ID_0
 SG_ Overvoltage_protection_counter m2 : 63|8@0+ (1,0) [0|0] "-"  BMU_ID_0
 SG_ Total_charged_capacity m3 : 15|32@0+ (0.1,0) [0|0] "Ah"  BMU_ID_0
 SG_ Fully_discharged_counter m3 : 47|16@0+ (1,0) [0|0] ""  BMU_ID_0
 SG_ Overcurrent_protection_counter m3 : 63|8@0+ (1,0) [0|0] ""  BMU_ID_0
 SG_ Total_discharged_capacity m4 : 15|32@0+ (0.1,0) [0|0] "Ah"  BMU_ID_0
 SG_ Overtemperature_protection_count m4 : 47|8@0+ (1,0) [0|0] ""  BMU_ID_0
 SG_ Undertemperature_protection_coun m4 : 55|8@0+ (1,0) [0|0] ""  BMU_ID_0
 SG_ Undervoltage_protection_counter m4 : 63|8@0+ (1,0) [0|0] ""  BMU_ID_0

BO_ 1510 wBMU_ID_6_msg_14_maximeters: 8 BMU_ID_6
 SG_ Content_ID M : 7|8@0+ (1,0) [0|0] ""  BMU_ID_0
 SG_ Remaining_capacity m0 : 15|16@0+ (1,0) [0|0] "Ah"  BMU_ID_0
 SG_ Contactors_opened_under_load_cnt m0 : 31|24@0+ (1,0) [0|0] "-"  BMU_ID_0
 SG_ Equivalent_cycles m1 : 15|16@0+ (1,0) [0|0] "- "  BMU_ID_0
 SG_ Cycles_since_fully_charged m1 : 31|16@0+ (1,0) [0|0] "- "  BMU_ID_0
 SG_ Fully_charged_counter m1 : 47|16@0+ (1,0) [0|0] "- "  BMU_ID_0
 SG_ Total_charged_energy m2 : 15|24@0+ (1,0) [0|0] "kWh"  BMU_ID_0
 SG_ Total_discharged_energy m2 : 39|24@0+ (1,0) [0|0] "kWh"  BMU_ID_0
 SG_ Overvoltage_protection_counter m2 : 63|8@0+ (1,0) [0|0] "-"  BMU_ID_0
 SG_ Total_charged_capacity m3 : 15|32@0+ (0.1,0) [0|0] "Ah"  BMU_ID_0
 SG_ Fully_discharged_counter m3 : 47|16@0+ (1,0) [0|0] ""  BMU_ID_0
 SG_ Overcurrent_protection_counter m3 : 63|8@0+ (1,0) [0|0] ""  BMU_ID_0
 SG_ Total_discharged_capacity m4 : 15|32@0+ (0.1,0) [0|0] "Ah"  BMU_ID_0
 SG_ Overtemperature_protection_count m4 : 47|8@0+ (1,0) [0|0] ""  BMU_ID_0
 SG_ Undertemperature_protection_coun m4 : 55|8@0+ (1,0) [0|0] ""  BMU_ID_0
 SG_ Undervoltage_protection_counter m4 : 63|8@0+ (1,0) [0|0] ""  BMU_ID_0

BO_ 1511 wBMU_ID_7_msg_14_maximeters: 8 BMU_ID_7
 SG_ Content_ID M : 7|8@0+ (1,0) [0|0] ""  BMU_ID_0
 SG_ Remaining_capacity m0 : 15|16@0+ (1,0) [0|0] "Ah"  BMU_ID_0
 SG_ Contactors_opened_under_load_cnt m0 : 31|24@0+ (1,0) [0|0] "-"  BMU_ID_0
 SG_ Equivalent_cycles m1 : 15|16@0+ (1,0) [0|0] "- "  BMU_ID_0
 SG_ Cycles_since_fully_charged m1 : 31|16@0+ (1,0) [0|0] "- "  BMU_ID_0
 SG_ Fully_charged_counter m1 : 47|16@0+ (1,0) [0|0] "- "  BMU_ID_0
 SG_ Total_charged_energy m2 : 15|24@0+ (1,0) [0|0] "kWh"  BMU_ID_0
 SG_ Total_discharged_energy m2 : 39|24@0+ (1,0) [0|0] "kWh"  BMU_ID_0
 SG_ Overvoltage_protection_counter m2 : 63|8@0+ (1,0) [0|0] "-"  BMU_ID_0
 SG_ Total_charged_capacity m3 : 15|32@0+ (0.1,0) [0|0] "Ah"  BMU_ID_0
 SG_ Fully_discharged_counter m3 : 47|16@0+ (1,0) [0|0] ""  BMU_ID_0
 SG_ Overcurrent_protection_counter m3 : 63|8@0+ (1,0) [0|0] ""  BMU_ID_0
 SG_ Total_discharged_capacity m4 : 15|32@0+ (0.1,0) [0|0] "Ah"  BMU_ID_0
 SG_ Overtemperature_protection_count m4 : 47|8@0+ (1,0) [0|0] ""  BMU_ID_0
 SG_ Undertemperature_protection_coun m4 : 55|8@0+ (1,0) [0|0] ""  BMU_ID_0
 SG_ Undervoltage_protection_counter m4 : 63|8@0+ (1,0) [0|0] ""  BMU_ID_0

BO_ 1512 wBMU_ID_8_msg_14_maximeters: 8 BMU_ID_8
 SG_ Content_ID M : 7|8@0+ (1,0) [0|0] ""  BMU_ID_0
 SG_ Remaining_capacity m0 : 15|16@0+ (1,0) [0|0] "Ah"  BMU_ID_0
 SG_ Contactors_opened_under_load_cnt m0 : 31|24@0+ (1,0) [0|0] "-"  BMU_ID_0
 SG_ Equivalent_cycles m1 : 15|16@0+ (1,0) [0|0] "- "  BMU_ID_0
 SG_ Cycles_since_fully_charged m1 : 31|16@0+ (1,0) [0|0] "- "  BMU_ID_0
 SG_ Fully_charged_counter m1 : 47|16@0+ (1,0) [0|0] "- "  BMU_ID_0
 SG_ Total_charged_energy m2 : 15|24@0+ (1,0) [0|0] "kWh"  BMU_ID_0
 SG_ Total_discharged_energy m2 : 39|24@0+ (1,0) [0|0] "kWh"  BMU_ID_0
 SG_ Overvoltage_protection_counter m2 : 63|8@0+ (1,0) [0|0] "-"  BMU_ID_0
 SG_ Total_charged_capacity m3 : 15|32@0+ (0.1,0) [0|0] "Ah"  BMU_ID_0
 SG_ Fully_discharged_counter m3 : 47|16@0+ (1,0) [0|0] ""  BMU_ID_0
 SG_ Overcurrent_protection_counter m3 : 63|8@0+ (1,0) [0|0] ""  BMU_ID_0
 SG_ Total_discharged_capacity m4 : 15|32@0+ (0.1,0) [0|0] "Ah"  BMU_ID_0
 SG_ Overtemperature_protection_count m4 : 47|8@0+ (1,0) [0|0] ""  BMU_ID_0
 SG_ Undertemperature_protection_coun m4 : 55|8@0+ (1,0) [0|0] ""  BMU_ID_0
 SG_ Undervoltage_protection_counter m4 : 63|8@0+ (1,0) [0|0] ""  BMU_ID_0

BO_ 1513 wBMU_ID_9_msg_14_maximeters: 8 BMU_ID_9
 SG_ Content_ID M : 7|8@0+ (1,0) [0|0] ""  BMU_ID_0
 SG_ Remaining_capacity m0 : 15|16@0+ (1,0) [0|0] "Ah"  BMU_ID_0
 SG_ Contactors_opened_under_load_cnt m0 : 31|24@0+ (1,0) [0|0] "-"  BMU_ID_0
 SG_ Equivalent_cycles m1 : 15|16@0+ (1,0) [0|0] "- "  BMU_ID_0
 SG_ Cycles_since_fully_charged m1 : 31|16@0+ (1,0) [0|0] "- "  BMU_ID_0
 SG_ Fully_charged_counter m1 : 47|16@0+ (1,0) [0|0] "- "  BMU_ID_0
 SG_ Total_charged_energy m2 : 15|24@0+ (1,0) [0|0] "kWh"  BMU_ID_0
 SG_ Total_discharged_energy m2 : 39|24@0+ (1,0) [0|0] "kWh"  BMU_ID_0
 SG_ Overvoltage_protection_counter m2 : 63|8@0+ (1,0) [0|0] "-"  BMU_ID_0
 SG_ Total_charged_capacity m3 : 15|32@0+ (0.1,0) [0|0] "Ah"  BMU_ID_0
 SG_ Fully_discharged_counter m3 : 47|16@0+ (1,0) [0|0] ""  BMU_ID_0
 SG_ Overcurrent_protection_counter m3 : 63|8@0+ (1,0) [0|0] ""  BMU_ID_0
 SG_ Total_discharged_capacity m4 : 15|32@0+ (0.1,0) [0|0] "Ah"  BMU_ID_0
 SG_ Overtemperature_protection_count m4 : 47|8@0+ (1,0) [0|0] ""  BMU_ID_0
 SG_ Undertemperature_protection_coun m4 : 55|8@0+ (1,0) [0|0] ""  BMU_ID_0
 SG_ Undervoltage_protection_counter m4 : 63|8@0+ (1,0) [0|0] ""  BMU_ID_0

BO_ 1514 wBMU_ID_10_msg_14_maximeters: 8 BMU_ID_10
 SG_ Content_ID M : 7|8@0+ (1,0) [0|0] ""  BMU_ID_0
 SG_ Remaining_capacity m0 : 15|16@0+ (1,0) [0|0] "Ah"  BMU_ID_0
 SG_ Contactors_opened_under_load_cnt m0 : 31|24@0+ (1,0) [0|0] "-"  BMU_ID_0
 SG_ Equivalent_cycles m1 : 15|16@0+ (1,0) [0|0] "- "  BMU_ID_0
 SG_ Cycles_since_fully_charged m1 : 31|16@0+ (1,0) [0|0] "- "  BMU_ID_0
 SG_ Fully_charged_counter m1 : 47|16@0+ (1,0) [0|0] "- "  BMU_ID_0
 SG_ Total_charged_energy m2 : 15|24@0+ (1,0) [0|0] "kWh"  BMU_ID_0
 SG_ Total_discharged_energy m2 : 39|24@0+ (1,0) [0|0] "kWh"  BMU_ID_0
 SG_ Overvoltage_protection_counter m2 : 63|8@0+ (1,0) [0|0] "-"  BMU_ID_0
 SG_ Total_charged_capacity m3 : 15|32@0+ (0.1,0) [0|0] "Ah"  BMU_ID_0
 SG_ Fully_discharged_counter m3 : 47|16@0+ (1,0) [0|0] ""  BMU_ID_0
 SG_ Overcurrent_protection_counter m3 : 63|8@0+ (1,0) [0|0] ""  BMU_ID_0
 SG_ Total_discharged_capacity m4 : 15|32@0+ (0.1,0) [0|0] "Ah"  BMU_ID_0
 SG_ Overtemperature_protection_count m4 : 47|8@0+ (1,0) [0|0] ""  BMU_ID_0
 SG_ Undertemperature_protection_coun m4 : 55|8@0+ (1,0) [0|0] ""  BMU_ID_0
 SG_ Undervoltage_protection_counter m4 : 63|8@0+ (1,0) [0|0] ""  BMU_ID_0

BO_ 1515 wBMU_ID_11_msg_14_maximeters: 8 BMU_ID_11
 SG_ Content_ID M : 7|8@0+ (1,0) [0|0] ""  BMU_ID_0
 SG_ Remaining_capacity m0 : 15|16@0+ (1,0) [0|0] "Ah"  BMU_ID_0
 SG_ Contactors_opened_under_load_cnt m0 : 31|24@0+ (1,0) [0|0] "-"  BMU_ID_0
 SG_ Equivalent_cycles m1 : 15|16@0+ (1,0) [0|0] "- "  BMU_ID_0
 SG_ Cycles_since_fully_charged m1 : 31|16@0+ (1,0) [0|0] "- "  BMU_ID_0
 SG_ Fully_charged_counter m1 : 47|16@0+ (1,0) [0|0] "- "  BMU_ID_0
 SG_ Total_charged_energy m2 : 15|24@0+ (1,0) [0|0] "kWh"  BMU_ID_0
 SG_ Total_discharged_energy m2 : 39|24@0+ (1,0) [0|0] "kWh"  BMU_ID_0
 SG_ Overvoltage_protection_counter m2 : 63|8@0+ (1,0) [0|0] "-"  BMU_ID_0
 SG_ Total_charged_capacity m3 : 15|32@0+ (0.1,0) [0|0] "Ah"  BMU_ID_0
 SG_ Fully_discharged_counter m3 : 47|16@0+ (1,0) [0|0] ""  BMU_ID_0
 SG_ Overcurrent_protection_counter m3 : 63|8@0+ (1,0) [0|0] ""  BMU_ID_0
 SG_ Total_discharged_capacity m4 : 15|32@0+ (0.1,0) [0|0] "Ah"  BMU_ID_0
 SG_ Overtemperature_protection_count m4 : 47|8@0+ (1,0) [0|0] ""  BMU_ID_0
 SG_ Undertemperature_protection_coun m4 : 55|8@0+ (1,0) [0|0] ""  BMU_ID_0
 SG_ Undervoltage_protection_counter m4 : 63|8@0+ (1,0) [0|0] ""  BMU_ID_0

BO_ 1516 wBMU_ID_12_msg_14_maximeters: 8 BMU_ID_12
 SG_ Content_ID M : 7|8@0+ (1,0) [0|0] ""  BMU_ID_0
 SG_ Remaining_capacity m0 : 15|16@0+ (1,0) [0|0] "Ah"  BMU_ID_0
 SG_ Contactors_opened_under_load_cnt m0 : 31|24@0+ (1,0) [0|0] "-"  BMU_ID_0
 SG_ Equivalent_cycles m1 : 15|16@0+ (1,0) [0|0] "- "  BMU_ID_0
 SG_ Cycles_since_fully_charged m1 : 31|16@0+ (1,0) [0|0] "- "  BMU_ID_0
 SG_ Fully_charged_counter m1 : 47|16@0+ (1,0) [0|0] "- "  BMU_ID_0
 SG_ Total_charged_energy m2 : 15|24@0+ (1,0) [0|0] "kWh"  BMU_ID_0
 SG_ Total_discharged_energy m2 : 39|24@0+ (1,0) [0|0] "kWh"  BMU_ID_0
 SG_ Overvoltage_protection_counter m2 : 63|8@0+ (1,0) [0|0] "-"  BMU_ID_0
 SG_ Total_charged_capacity m3 : 15|32@0+ (0.1,0) [0|0] "Ah"  BMU_ID_0
 SG_ Fully_discharged_counter m3 : 47|16@0+ (1,0) [0|0] ""  BMU_ID_0
 SG_ Overcurrent_protection_counter m3 : 63|8@0+ (1,0) [0|0] ""  BMU_ID_0
 SG_ Total_discharged_capacity m4 : 15|32@0+ (0.1,0) [0|0] "Ah"  BMU_ID_0
 SG_ Overtemperature_protection_count m4 : 47|8@0+ (1,0) [0|0] ""  BMU_ID_0
 SG_ Undertemperature_protection_coun m4 : 55|8@0+ (1,0) [0|0] ""  BMU_ID_0
 SG_ Undervoltage_protection_counter m4 : 63|8@0+ (1,0) [0|0] ""  BMU_ID_0

BO_ 1517 wBMU_ID_13_msg_14_maximeters: 8 BMU_ID_13
 SG_ Content_ID M : 7|8@0+ (1,0) [0|0] ""  BMU_ID_0
 SG_ Remaining_capacity m0 : 15|16@0+ (1,0) [0|0] "Ah"  BMU_ID_0
 SG_ Contactors_opened_under_load_cnt m0 : 31|24@0+ (1,0) [0|0] "-"  BMU_ID_0
 SG_ Equivalent_cycles m1 : 15|16@0+ (1,0) [0|0] "- "  BMU_ID_0
 SG_ Cycles_since_fully_charged m1 : 31|16@0+ (1,0) [0|0] "- "  BMU_ID_0
 SG_ Fully_charged_counter m1 : 47|16@0+ (1,0) [0|0] "- "  BMU_ID_0
 SG_ Total_charged_energy m2 : 15|24@0+ (1,0) [0|0] "kWh"  BMU_ID_0
 SG_ Total_discharged_energy m2 : 39|24@0+ (1,0) [0|0] "kWh"  BMU_ID_0
 SG_ Overvoltage_protection_counter m2 : 63|8@0+ (1,0) [0|0] "-"  BMU_ID_0
 SG_ Total_charged_capacity m3 : 15|32@0+ (0.1,0) [0|0] "Ah"  BMU_ID_0
 SG_ Fully_discharged_counter m3 : 47|16@0+ (1,0) [0|0] ""  BMU_ID_0
 SG_ Overcurrent_protection_counter m3 : 63|8@0+ (1,0) [0|0] ""  BMU_ID_0
 SG_ Total_discharged_capacity m4 : 15|32@0+ (0.1,0) [0|0] "Ah"  BMU_ID_0
 SG_ Overtemperature_protection_count m4 : 47|8@0+ (1,0) [0|0] ""  BMU_ID_0
 SG_ Undertemperature_protection_coun m4 : 55|8@0+ (1,0) [0|0] ""  BMU_ID_0
 SG_ Undervoltage_protection_counter m4 : 63|8@0+ (1,0) [0|0] ""  BMU_ID_0

BO_ 1518 wBMU_ID_14_msg_14_maximeters: 8 BMU_ID_14
 SG_ Content_ID M : 7|8@0+ (1,0) [0|0] ""  BMU_ID_0
 SG_ Remaining_capacity m0 : 15|16@0+ (1,0) [0|0] "Ah"  BMU_ID_0
 SG_ Contactors_opened_under_load_cnt m0 : 31|24@0+ (1,0) [0|0] "-"  BMU_ID_0
 SG_ Equivalent_cycles m1 : 15|16@0+ (1,0) [0|0] "- "  BMU_ID_0
 SG_ Cycles_since_fully_charged m1 : 31|16@0+ (1,0) [0|0] "- "  BMU_ID_0
 SG_ Fully_charged_counter m1 : 47|16@0+ (1,0) [0|0] "- "  BMU_ID_0
 SG_ Total_charged_energy m2 : 15|24@0+ (1,0) [0|0] "kWh"  BMU_ID_0
 SG_ Total_discharged_energy m2 : 39|24@0+ (1,0) [0|0] "kWh"  BMU_ID_0
 SG_ Overvoltage_protection_counter m2 : 63|8@0+ (1,0) [0|0] "-"  BMU_ID_0
 SG_ Total_charged_capacity m3 : 15|32@0+ (0.1,0) [0|0] "Ah"  BMU_ID_0
 SG_ Fully_discharged_counter m3 : 47|16@0+ (1,0) [0|0] ""  BMU_ID_0
 SG_ Overcurrent_protection_counter m3 : 63|8@0+ (1,0) [0|0] ""  BMU_ID_0
 SG_ Total_discharged_capacity m4 : 15|32@0+ (0.1,0) [0|0] "Ah"  BMU_ID_0
 SG_ Overtemperature_protection_count m4 : 47|8@0+ (1,0) [0|0] ""  BMU_ID_0
 SG_ Undertemperature_protection_coun m4 : 55|8@0+ (1,0) [0|0] ""  BMU_ID_0
 SG_ Undervoltage_protection_counter m4 : 63|8@0+ (1,0) [0|0] ""  BMU_ID_0

BO_ 1519 wBMU_ID_15_msg_14_maximeters: 8 BMU_ID_15
 SG_ Content_ID M : 7|8@0+ (1,0) [0|0] ""  BMU_ID_0
 SG_ Remaining_capacity m0 : 15|16@0+ (1,0) [0|0] "Ah"  BMU_ID_0
 SG_ Contactors_opened_under_load_cnt m0 : 31|24@0+ (1,0) [0|0] "-"  BMU_ID_0
 SG_ Equivalent_cycles m1 : 15|16@0+ (1,0) [0|0] "- "  BMU_ID_0
 SG_ Cycles_since_fully_charged m1 : 31|16@0+ (1,0) [0|0] "- "  BMU_ID_0
 SG_ Fully_charged_counter m1 : 47|16@0+ (1,0) [0|0] "- "  BMU_ID_0
 SG_ Total_charged_energy m2 : 15|24@0+ (1,0) [0|0] "kWh"  BMU_ID_0
 SG_ Total_discharged_energy m2 : 39|24@0+ (1,0) [0|0] "kWh"  BMU_ID_0
 SG_ Overvoltage_protection_counter m2 : 63|8@0+ (1,0) [0|0] "-"  BMU_ID_0
 SG_ Total_charged_capacity m3 : 15|32@0+ (0.1,0) [0|0] "Ah"  BMU_ID_0
 SG_ Fully_discharged_counter m3 : 47|16@0+ (1,0) [0|0] ""  BMU_ID_0
 SG_ Overcurrent_protection_counter m3 : 63|8@0+ (1,0) [0|0] ""  BMU_ID_0
 SG_ Total_discharged_capacity m4 : 15|32@0+ (0.1,0) [0|0] "Ah"  BMU_ID_0
 SG_ Overtemperature_protection_count m4 : 47|8@0+ (1,0) [0|0] ""  BMU_ID_0
 SG_ Undertemperature_protection_coun m4 : 55|8@0+ (1,0) [0|0] ""  BMU_ID_0
 SG_ Undervoltage_protection_counter m4 : 63|8@0+ (1,0) [0|0] ""  BMU_ID_0

BO_ 1520 wBMU_ID_0_msg_15_configuration: 8 BMU_ID_0
 SG_ Content_ID M : 7|8@0+ (1,0) [0|0] ""  BMU_ID_0
 SG_ Configuration_CRC m2 : 15|32@0+ (1,0) [0|0] "-"  BMU_ID_0
 SG_ String_capacity m2 : 47|16@0+ (1,0) [0|0] "Ah"  BMU_ID_0
 SG_ Number_of_CMU_link_devices_found m2 : 62|7@0+ (1,0) [0|0] "-"  BMU_ID_0
 SG_ Device_ID m0 : 15|32@0+ (1,0) [0|0] "-"  BMU_ID_0
 SG_ Software_version_major m0 : 47|8@0+ (1,0) [0|0] "-"  BMU_ID_0
 SG_ Software_version_minor m0 : 55|8@0+ (1,0) [0|0] "-"  BMU_ID_0
 SG_ Software_version_patch m0 : 63|8@0+ (1,0) [0|0] "-"  BMU_ID_0
 SG_ Bootloader_version_major m1 : 15|8@0+ (1,0) [0|0] "-"  BMU_ID_0
 SG_ Bootloader_version_minor m1 : 23|8@0+ (1,0) [0|0] "-"  BMU_ID_0
 SG_ Hardware_version_major m1 : 31|8@0+ (1,0) [0|0] "-"  BMU_ID_0
 SG_ Hardware_version_minor m1 : 39|8@0+ (1,0) [0|0] "-"  BMU_ID_0
 SG_ Hardware_type m1 : 47|16@0+ (1,0) [0|0] "-"  BMU_ID_0
 SG_ Precharge_configured_time m1 : 63|8@0+ (1,0) [0|0] "s"  BMU_ID_0
 SG_ Reserved m3 : 15|56@0+ (1,0) [0|0] ""  BMU_ID_0

BO_ 1521 wBMU_ID_1_msg_15_configuration: 8 BMU_ID_1
 SG_ Content_ID M : 7|8@0+ (1,0) [0|0] ""  BMU_ID_0
 SG_ Configuration_CRC m2 : 15|32@0+ (1,0) [0|0] "-"  BMU_ID_0
 SG_ String_capacity m2 : 47|16@0+ (1,0) [0|0] "Ah"  BMU_ID_0
 SG_ Number_of_CMU_link_devices_found m2 : 62|7@0+ (1,0) [0|0] "-"  BMU_ID_0
 SG_ Device_ID m0 : 15|32@0+ (1,0) [0|0] "-"  BMU_ID_0
 SG_ Software_version_major m0 : 47|8@0+ (1,0) [0|0] "-"  BMU_ID_0
 SG_ Software_version_minor m0 : 55|8@0+ (1,0) [0|0] "-"  BMU_ID_0
 SG_ Software_version_patch m0 : 63|8@0+ (1,0) [0|0] "-"  BMU_ID_0
 SG_ Bootloader_version_major m1 : 15|8@0+ (1,0) [0|0] "-"  BMU_ID_0
 SG_ Bootloader_version_minor m1 : 23|8@0+ (1,0) [0|0] "-"  BMU_ID_0
 SG_ Hardware_version_major m1 : 31|8@0+ (1,0) [0|0] "-"  BMU_ID_0
 SG_ Hardware_version_minor m1 : 39|8@0+ (1,0) [0|0] "-"  BMU_ID_0
 SG_ Hardware_type m1 : 47|16@0+ (1,0) [0|0] "-"  BMU_ID_0
 SG_ Precharge_configured_time m1 : 63|8@0+ (1,0) [0|0] "s"  BMU_ID_0
 SG_ Reserved m3 : 15|56@0+ (1,0) [0|0] ""  BMU_ID_0

BO_ 1522 wBMU_ID_2_msg_15_configuration: 8 BMU_ID_2
 SG_ Content_ID M : 7|8@0+ (1,0) [0|0] ""  BMU_ID_0
 SG_ Configuration_CRC m2 : 15|32@0+ (1,0) [0|0] "-"  BMU_ID_0
 SG_ String_capacity m2 : 47|16@0+ (1,0) [0|0] "Ah"  BMU_ID_0
 SG_ Number_of_CMU_link_devices_found m2 : 62|7@0+ (1,0) [0|0] "-"  BMU_ID_0
 SG_ Device_ID m0 : 15|32@0+ (1,0) [0|0] "-"  BMU_ID_0
 SG_ Software_version_major m0 : 47|8@0+ (1,0) [0|0] "-"  BMU_ID_0
 SG_ Software_version_minor m0 : 55|8@0+ (1,0) [0|0] "-"  BMU_ID_0
 SG_ Software_version_patch m0 : 63|8@0+ (1,0) [0|0] "-"  BMU_ID_0
 SG_ Bootloader_version_major m1 : 15|8@0+ (1,0) [0|0] "-"  BMU_ID_0
 SG_ Bootloader_version_minor m1 : 23|8@0+ (1,0) [0|0] "-"  BMU_ID_0
 SG_ Hardware_version_major m1 : 31|8@0+ (1,0) [0|0] "-"  BMU_ID_0
 SG_ Hardware_version_minor m1 : 39|8@0+ (1,0) [0|0] "-"  BMU_ID_0
 SG_ Hardware_type m1 : 47|16@0+ (1,0) [0|0] "-"  BMU_ID_0
 SG_ Precharge_configured_time m1 : 63|8@0+ (1,0) [0|0] "s"  BMU_ID_0
 SG_ Reserved m3 : 15|56@0+ (1,0) [0|0] ""  BMU_ID_0

BO_ 1523 wBMU_ID_3_msg_15_configuration: 8 BMU_ID_3
 SG_ Content_ID M : 7|8@0+ (1,0) [0|0] ""  BMU_ID_0
 SG_ Configuration_CRC m2 : 15|32@0+ (1,0) [0|0] "-"  BMU_ID_0
 SG_ String_capacity m2 : 47|16@0+ (1,0) [0|0] "Ah"  BMU_ID_0
 SG_ Number_of_CMU_link_devices_found m2 : 62|7@0+ (1,0) [0|0] "-"  BMU_ID_0
 SG_ Device_ID m0 : 15|32@0+ (1,0) [0|0] "-"  BMU_ID_0
 SG_ Software_version_major m0 : 47|8@0+ (1,0) [0|0] "-"  BMU_ID_0
 SG_ Software_version_minor m0 : 55|8@0+ (1,0) [0|0] "-"  BMU_ID_0
 SG_ Software_version_patch m0 : 63|8@0+ (1,0) [0|0] "-"  BMU_ID_0
 SG_ Bootloader_version_major m1 : 15|8@0+ (1,0) [0|0] "-"  BMU_ID_0
 SG_ Bootloader_version_minor m1 : 23|8@0+ (1,0) [0|0] "-"  BMU_ID_0
 SG_ Hardware_version_major m1 : 31|8@0+ (1,0) [0|0] "-"  BMU_ID_0
 SG_ Hardware_version_minor m1 : 39|8@0+ (1,0) [0|0] "-"  BMU_ID_0
 SG_ Hardware_type m1 : 47|16@0+ (1,0) [0|0] "-"  BMU_ID_0
 SG_ Precharge_configured_time m1 : 63|8@0+ (1,0) [0|0] "s"  BMU_ID_0
 SG_ Reserved m3 : 15|56@0+ (1,0) [0|0] ""  BMU_ID_0

BO_ 1524 wBMU_ID_4_msg_15_configuration: 8 BMU_ID_4
 SG_ Content_ID M : 7|8@0+ (1,0) [0|0] ""  BMU_ID_0
 SG_ Configuration_CRC m2 : 15|32@0+ (1,0) [0|0] "-"  BMU_ID_0
 SG_ String_capacity m2 : 47|16@0+ (1,0) [0|0] "Ah"  BMU_ID_0
 SG_ Number_of_CMU_link_devices_found m2 : 62|7@0+ (1,0) [0|0] "-"  BMU_ID_0
 SG_ BMU_ID m0 : 15|32@0+ (1,0) [0|0] "-"  BMU_ID_0
 SG_ Software_version_major m0 : 47|8@0+ (1,0) [0|0] "-"  BMU_ID_0
 SG_ Software_version_minor m0 : 55|8@0+ (1,0) [0|0] "-"  BMU_ID_0
 SG_ Software_version_patch m0 : 63|8@0+ (1,0) [0|0] "-"  BMU_ID_0
 SG_ Bootloader_version_major m1 : 15|8@0+ (1,0) [0|0] "-"  BMU_ID_0
 SG_ Bootloader_version_minor m1 : 23|8@0+ (1,0) [0|0] "-"  BMU_ID_0
 SG_ Hardware_version_major m1 : 31|8@0+ (1,0) [0|0] "-"  BMU_ID_0
 SG_ Hardware_version_minor m1 : 39|8@0+ (1,0) [0|0] "-"  BMU_ID_0
 SG_ Hardware_type m1 : 47|16@0+ (1,0) [0|0] "-"  BMU_ID_0
 SG_ Precharge_configured_time m1 : 63|8@0+ (1,0) [0|0] "s"  BMU_ID_0
 SG_ Reserved m3 : 15|56@0+ (1,0) [0|0] ""  BMU_ID_0

BO_ 1525 wBMU_ID_5_msg_15_configuration: 8 BMU_ID_5
 SG_ Content_ID M : 7|8@0+ (1,0) [0|0] ""  BMU_ID_0
 SG_ Configuration_CRC m2 : 15|32@0+ (1,0) [0|0] "-"  BMU_ID_0
 SG_ String_capacity m2 : 47|16@0+ (1,0) [0|0] "Ah"  BMU_ID_0
 SG_ Number_of_CMU_link_devices_found m2 : 62|7@0+ (1,0) [0|0] "-"  BMU_ID_0
 SG_ Device_ID m0 : 15|32@0+ (1,0) [0|0] "-"  BMU_ID_0
 SG_ Software_version_major m0 : 47|8@0+ (1,0) [0|0] "-"  BMU_ID_0
 SG_ Software_version_minor m0 : 55|8@0+ (1,0) [0|0] "-"  BMU_ID_0
 SG_ Software_version_patch m0 : 63|8@0+ (1,0) [0|0] "-"  BMU_ID_0
 SG_ Bootloader_version_major m1 : 15|8@0+ (1,0) [0|0] "-"  BMU_ID_0
 SG_ Bootloader_version_minor m1 : 23|8@0+ (1,0) [0|0] "-"  BMU_ID_0
 SG_ Hardware_version_major m1 : 31|8@0+ (1,0) [0|0] "-"  BMU_ID_0
 SG_ Hardware_version_minor m1 : 39|8@0+ (1,0) [0|0] "-"  BMU_ID_0
 SG_ Hardware_type m1 : 47|16@0+ (1,0) [0|0] "-"  BMU_ID_0
 SG_ Precharge_configured_time m1 : 63|8@0+ (1,0) [0|0] "s"  BMU_ID_0
 SG_ Reserved m3 : 15|56@0+ (1,0) [0|0] ""  BMU_ID_0

BO_ 1526 wBMU_ID_6_msg_15_configuration: 8 BMU_ID_6
 SG_ Content_ID M : 7|8@0+ (1,0) [0|0] ""  BMU_ID_0
 SG_ Configuration_CRC m2 : 15|32@0+ (1,0) [0|0] "-"  BMU_ID_0
 SG_ String_capacity m2 : 47|16@0+ (1,0) [0|0] "Ah"  BMU_ID_0
 SG_ Number_of_CMU_link_devices_found m2 : 62|7@0+ (1,0) [0|0] "-"  BMU_ID_0
 SG_ Device_ID m0 : 15|32@0+ (1,0) [0|0] "-"  BMU_ID_0
 SG_ Software_version_major m0 : 47|8@0+ (1,0) [0|0] "-"  BMU_ID_0
 SG_ Software_version_minor m0 : 55|8@0+ (1,0) [0|0] "-"  BMU_ID_0
 SG_ Software_version_patch m0 : 63|8@0+ (1,0) [0|0] "-"  BMU_ID_0
 SG_ Bootloader_version_major m1 : 15|8@0+ (1,0) [0|0] "-"  BMU_ID_0
 SG_ Bootloader_version_minor m1 : 23|8@0+ (1,0) [0|0] "-"  BMU_ID_0
 SG_ Hardware_version_major m1 : 31|8@0+ (1,0) [0|0] "-"  BMU_ID_0
 SG_ Hardware_version_minor m1 : 39|8@0+ (1,0) [0|0] "-"  BMU_ID_0
 SG_ Hardware_type m1 : 47|16@0+ (1,0) [0|0] "-"  BMU_ID_0
 SG_ Precharge_configured_time m1 : 63|8@0+ (1,0) [0|0] "s"  BMU_ID_0
 SG_ Reserved m3 : 15|56@0+ (1,0) [0|0] ""  BMU_ID_0

BO_ 1527 wBMU_ID_7_msg_15_configuration: 8 BMU_ID_7
 SG_ Content_ID M : 7|8@0+ (1,0) [0|0] ""  BMU_ID_0
 SG_ Configuration_CRC m2 : 15|32@0+ (1,0) [0|0] "-"  BMU_ID_0
 SG_ String_capacity m2 : 47|16@0+ (1,0) [0|0] "Ah"  BMU_ID_0
 SG_ Number_of_CMU_link_devices_found m2 : 62|7@0+ (1,0) [0|0] "-"  BMU_ID_0
 SG_ Device_ID m0 : 15|32@0+ (1,0) [0|0] "-"  BMU_ID_0
 SG_ Software_version_major m0 : 47|8@0+ (1,0) [0|0] "-"  BMU_ID_0
 SG_ Software_version_minor m0 : 55|8@0+ (1,0) [0|0] "-"  BMU_ID_0
 SG_ Software_version_patch m0 : 63|8@0+ (1,0) [0|0] "-"  BMU_ID_0
 SG_ Bootloader_version_major m1 : 15|8@0+ (1,0) [0|0] "-"  BMU_ID_0
 SG_ Bootloader_version_minor m1 : 23|8@0+ (1,0) [0|0] "-"  BMU_ID_0
 SG_ Hardware_version_major m1 : 31|8@0+ (1,0) [0|0] "-"  BMU_ID_0
 SG_ Hardware_version_minor m1 : 39|8@0+ (1,0) [0|0] "-"  BMU_ID_0
 SG_ Hardware_type m1 : 47|16@0+ (1,0) [0|0] "-"  BMU_ID_0
 SG_ Precharge_configured_time m1 : 63|8@0+ (1,0) [0|0] "s"  BMU_ID_0
 SG_ Reserved m3 : 15|56@0+ (1,0) [0|0] ""  BMU_ID_0

BO_ 1528 wBMU_ID_8_msg_15_configuration: 8 BMU_ID_8
 SG_ Content_ID M : 7|8@0+ (1,0) [0|0] ""  BMU_ID_0
 SG_ Configuration_CRC m2 : 15|32@0+ (1,0) [0|0] "-"  BMU_ID_0
 SG_ String_capacity m2 : 47|16@0+ (1,0) [0|0] "Ah"  BMU_ID_0
 SG_ Number_of_CMU_link_devices_found m2 : 62|7@0+ (1,0) [0|0] "-"  BMU_ID_0
 SG_ Device_ID m0 : 15|32@0+ (1,0) [0|0] "-"  BMU_ID_0
 SG_ Software_version_major m0 : 47|8@0+ (1,0) [0|0] "-"  BMU_ID_0
 SG_ Software_version_minor m0 : 55|8@0+ (1,0) [0|0] "-"  BMU_ID_0
 SG_ Software_version_patch m0 : 63|8@0+ (1,0) [0|0] "-"  BMU_ID_0
 SG_ Bootloader_version_major m1 : 15|8@0+ (1,0) [0|0] "-"  BMU_ID_0
 SG_ Bootloader_version_minor m1 : 23|8@0+ (1,0) [0|0] "-"  BMU_ID_0
 SG_ Hardware_version_major m1 : 31|8@0+ (1,0) [0|0] "-"  BMU_ID_0
 SG_ Hardware_version_minor m1 : 39|8@0+ (1,0) [0|0] "-"  BMU_ID_0
 SG_ Hardware_type m1 : 47|16@0+ (1,0) [0|0] "-"  BMU_ID_0
 SG_ Precharge_configured_time m1 : 63|8@0+ (1,0) [0|0] "s"  BMU_ID_0
 SG_ Reserved m3 : 15|56@0+ (1,0) [0|0] ""  BMU_ID_0

BO_ 1529 wBMU_ID_9_msg_15_configuration: 8 BMU_ID_9
 SG_ Content_ID M : 7|8@0+ (1,0) [0|0] ""  BMU_ID_0
 SG_ Configuration_CRC m2 : 15|32@0+ (1,0) [0|0] "-"  BMU_ID_0
 SG_ String_capacity m2 : 47|16@0+ (1,0) [0|0] "Ah"  BMU_ID_0
 SG_ Number_of_CMU_link_devices_found m2 : 62|7@0+ (1,0) [0|0] "-"  BMU_ID_0
 SG_ Device_ID m0 : 15|32@0+ (1,0) [0|0] "-"  BMU_ID_0
 SG_ Software_version_major m0 : 47|8@0+ (1,0) [0|0] "-"  BMU_ID_0
 SG_ Software_version_minor m0 : 55|8@0+ (1,0) [0|0] "-"  BMU_ID_0
 SG_ Software_version_patch m0 : 63|8@0+ (1,0) [0|0] "-"  BMU_ID_0
 SG_ Bootloader_version_major m1 : 15|8@0+ (1,0) [0|0] "-"  BMU_ID_0
 SG_ Bootloader_version_minor m1 : 23|8@0+ (1,0) [0|0] "-"  BMU_ID_0
 SG_ Hardware_version_major m1 : 31|8@0+ (1,0) [0|0] "-"  BMU_ID_0
 SG_ Hardware_version_minor m1 : 39|8@0+ (1,0) [0|0] "-"  BMU_ID_0
 SG_ Hardware_type m1 : 47|16@0+ (1,0) [0|0] "-"  BMU_ID_0
 SG_ Precharge_configured_time m1 : 63|8@0+ (1,0) [0|0] "s"  BMU_ID_0
 SG_ Reserved m3 : 15|56@0+ (1,0) [0|0] ""  BMU_ID_0

BO_ 1530 wBMU_ID_10_msg_15_configuration: 8 BMU_ID_10
 SG_ Content_ID M : 7|8@0+ (1,0) [0|0] ""  BMU_ID_0
 SG_ Configuration_CRC m2 : 15|32@0+ (1,0) [0|0] "-"  BMU_ID_0
 SG_ String_capacity m2 : 47|16@0+ (1,0) [0|0] "Ah"  BMU_ID_0
 SG_ Number_of_CMU_link_devices_found m2 : 62|7@0+ (1,0) [0|0] "-"  BMU_ID_0
 SG_ Device_ID m0 : 15|32@0+ (1,0) [0|0] "-"  BMU_ID_0
 SG_ Software_version_major m0 : 47|8@0+ (1,0) [0|0] "-"  BMU_ID_0
 SG_ Software_version_minor m0 : 55|8@0+ (1,0) [0|0] "-"  BMU_ID_0
 SG_ Software_version_patch m0 : 63|8@0+ (1,0) [0|0] "-"  BMU_ID_0
 SG_ Bootloader_version_major m1 : 15|8@0+ (1,0) [0|0] "-"  BMU_ID_0
 SG_ Bootloader_version_minor m1 : 23|8@0+ (1,0) [0|0] "-"  BMU_ID_0
 SG_ Hardware_version_major m1 : 31|8@0+ (1,0) [0|0] "-"  BMU_ID_0
 SG_ Hardware_version_minor m1 : 39|8@0+ (1,0) [0|0] "-"  BMU_ID_0
 SG_ Hardware_type m1 : 47|16@0+ (1,0) [0|0] "-"  BMU_ID_0
 SG_ Precharge_configured_time m1 : 63|8@0+ (1,0) [0|0] "s"  BMU_ID_0
 SG_ Reserved m3 : 15|56@0+ (1,0) [0|0] ""  BMU_ID_0

BO_ 1531 wBMU_ID_11_msg_15_configuration: 8 BMU_ID_11
 SG_ Content_ID M : 7|8@0+ (1,0) [0|0] ""  BMU_ID_0
 SG_ Configuration_CRC m2 : 15|32@0+ (1,0) [0|0] "-"  BMU_ID_0
 SG_ String_capacity m2 : 47|16@0+ (1,0) [0|0] "Ah"  BMU_ID_0
 SG_ Number_of_CMU_link_devices_found m2 : 62|7@0+ (1,0) [0|0] "-"  BMU_ID_0
 SG_ Device_ID m0 : 15|32@0+ (1,0) [0|0] "-"  BMU_ID_0
 SG_ Software_version_major m0 : 47|8@0+ (1,0) [0|0] "-"  BMU_ID_0
 SG_ Software_version_minor m0 : 55|8@0+ (1,0) [0|0] "-"  BMU_ID_0
 SG_ Software_version_patch m0 : 63|8@0+ (1,0) [0|0] "-"  BMU_ID_0
 SG_ Bootloader_version_major m1 : 15|8@0+ (1,0) [0|0] "-"  BMU_ID_0
 SG_ Bootloader_version_minor m1 : 23|8@0+ (1,0) [0|0] "-"  BMU_ID_0
 SG_ Hardware_version_major m1 : 31|8@0+ (1,0) [0|0] "-"  BMU_ID_0
 SG_ Hardware_version_minor m1 : 39|8@0+ (1,0) [0|0] "-"  BMU_ID_0
 SG_ Hardware_type m1 : 47|16@0+ (1,0) [0|0] "-"  BMU_ID_0
 SG_ Precharge_configured_time m1 : 63|8@0+ (1,0) [0|0] "s"  BMU_ID_0
 SG_ Reserved m3 : 15|56@0+ (1,0) [0|0] ""  BMU_ID_0

BO_ 1532 wBMU_ID_12_msg_15_configuration: 8 BMU_ID_12
 SG_ Content_ID M : 7|8@0+ (1,0) [0|0] ""  BMU_ID_0
 SG_ Configuration_CRC m2 : 15|32@0+ (1,0) [0|0] "-"  BMU_ID_0
 SG_ String_capacity m2 : 47|16@0+ (1,0) [0|0] "Ah"  BMU_ID_0
 SG_ Number_of_CMU_link_devices_found m2 : 62|7@0+ (1,0) [0|0] "-"  BMU_ID_0
 SG_ Device_ID m0 : 15|32@0+ (1,0) [0|0] "-"  BMU_ID_0
 SG_ Software_version_major m0 : 47|8@0+ (1,0) [0|0] "-"  BMU_ID_0
 SG_ Software_version_minor m0 : 55|8@0+ (1,0) [0|0] "-"  BMU_ID_0
 SG_ Software_version_patch m0 : 63|8@0+ (1,0) [0|0] "-"  BMU_ID_0
 SG_ Bootloader_version_major m1 : 15|8@0+ (1,0) [0|0] "-"  BMU_ID_0
 SG_ Bootloader_version_minor m1 : 23|8@0+ (1,0) [0|0] "-"  BMU_ID_0
 SG_ Hardware_version_major m1 : 31|8@0+ (1,0) [0|0] "-"  BMU_ID_0
 SG_ Hardware_version_minor m1 : 39|8@0+ (1,0) [0|0] "-"  BMU_ID_0
 SG_ Hardware_type m1 : 47|16@0+ (1,0) [0|0] "-"  BMU_ID_0
 SG_ Precharge_configured_time m1 : 63|8@0+ (1,0) [0|0] "s"  BMU_ID_0
 SG_ Reserved m3 : 15|56@0+ (1,0) [0|0] ""  BMU_ID_0

BO_ 1533 wBMU_ID_13_msg_15_configuration: 8 BMU_ID_13
 SG_ Content_ID M : 7|8@0+ (1,0) [0|0] ""  BMU_ID_0
 SG_ Configuration_CRC m2 : 15|32@0+ (1,0) [0|0] "-"  BMU_ID_0
 SG_ String_capacity m2 : 47|16@0+ (1,0) [0|0] "Ah"  BMU_ID_0
 SG_ Number_of_CMU_link_devices_found m2 : 62|7@0+ (1,0) [0|0] "-"  BMU_ID_0
 SG_ Device_ID m0 : 15|32@0+ (1,0) [0|0] "-"  BMU_ID_0
 SG_ Software_version_major m0 : 47|8@0+ (1,0) [0|0] "-"  BMU_ID_0
 SG_ Software_version_minor m0 : 55|8@0+ (1,0) [0|0] "-"  BMU_ID_0
 SG_ Software_version_patch m0 : 63|8@0+ (1,0) [0|0] "-"  BMU_ID_0
 SG_ Bootloader_version_major m1 : 15|8@0+ (1,0) [0|0] "-"  BMU_ID_0
 SG_ Bootloader_version_minor m1 : 23|8@0+ (1,0) [0|0] "-"  BMU_ID_0
 SG_ Hardware_version_major m1 : 31|8@0+ (1,0) [0|0] "-"  BMU_ID_0
 SG_ Hardware_version_minor m1 : 39|8@0+ (1,0) [0|0] "-"  BMU_ID_0
 SG_ Hardware_type m1 : 47|16@0+ (1,0) [0|0] "-"  BMU_ID_0
 SG_ Precharge_configured_time m1 : 63|8@0+ (1,0) [0|0] "s"  BMU_ID_0
 SG_ Reserved m3 : 15|56@0+ (1,0) [0|0] ""  BMU_ID_0

BO_ 1534 wBMU_ID_14_msg_15_configuration: 8 BMU_ID_14
 SG_ Content_ID M : 7|8@0+ (1,0) [0|0] ""  BMU_ID_0
 SG_ Configuration_CRC m2 : 15|32@0+ (1,0) [0|0] "-"  BMU_ID_0
 SG_ String_capacity m2 : 47|16@0+ (1,0) [0|0] "Ah"  BMU_ID_0
 SG_ Number_of_CMU_link_devices_found m2 : 62|7@0+ (1,0) [0|0] "-"  BMU_ID_0
 SG_ Device_ID m0 : 15|32@0+ (1,0) [0|0] "-"  BMU_ID_0
 SG_ Software_version_major m0 : 47|8@0+ (1,0) [0|0] "-"  BMU_ID_0
 SG_ Software_version_minor m0 : 55|8@0+ (1,0) [0|0] "-"  BMU_ID_0
 SG_ Software_version_patch m0 : 63|8@0+ (1,0) [0|0] "-"  BMU_ID_0
 SG_ Bootloader_version_major m1 : 15|8@0+ (1,0) [0|0] "-"  BMU_ID_0
 SG_ Bootloader_version_minor m1 : 23|8@0+ (1,0) [0|0] "-"  BMU_ID_0
 SG_ Hardware_version_major m1 : 31|8@0+ (1,0) [0|0] "-"  BMU_ID_0
 SG_ Hardware_version_minor m1 : 39|8@0+ (1,0) [0|0] "-"  BMU_ID_0
 SG_ Hardware_type m1 : 47|16@0+ (1,0) [0|0] "-"  BMU_ID_0
 SG_ Precharge_configured_time m1 : 63|8@0+ (1,0) [0|0] "s"  BMU_ID_0
 SG_ Reserved m3 : 15|56@0+ (1,0) [0|0] ""  BMU_ID_0

BO_ 1535 wBMU_ID_15_msg_15_configuration: 8 BMU_ID_15
 SG_ Content_ID M : 7|8@0+ (1,0) [0|0] ""  BMU_ID_0
 SG_ Configuration_CRC m2 : 15|32@0+ (1,0) [0|0] "-"  BMU_ID_0
 SG_ String_capacity m2 : 47|16@0+ (1,0) [0|0] "Ah"  BMU_ID_0
 SG_ Number_of_CMU_link_devices_found m2 : 62|7@0+ (1,0) [0|0] "-"  BMU_ID_0
 SG_ Device_ID m0 : 15|32@0+ (1,0) [0|0] "-"  BMU_ID_0
 SG_ Software_version_major m0 : 47|8@0+ (1,0) [0|0] "-"  BMU_ID_0
 SG_ Software_version_minor m0 : 55|8@0+ (1,0) [0|0] "-"  BMU_ID_0
 SG_ Software_version_patch m0 : 63|8@0+ (1,0) [0|0] "-"  BMU_ID_0
 SG_ Bootloader_version_major m1 : 15|8@0+ (1,0) [0|0] "-"  BMU_ID_0
 SG_ Bootloader_version_minor m1 : 23|8@0+ (1,0) [0|0] "-"  BMU_ID_0
 SG_ Hardware_version_major m1 : 31|8@0+ (1,0) [0|0] "-"  BMU_ID_0
 SG_ Hardware_version_minor m1 : 39|8@0+ (1,0) [0|0] "-"  BMU_ID_0
 SG_ Hardware_type m1 : 47|16@0+ (1,0) [0|0] "-"  BMU_ID_0
 SG_ Precharge_configured_time m1 : 63|8@0+ (1,0) [0|0] "s"  BMU_ID_0
 SG_ Reserved m3 : 15|56@0+ (1,0) [0|0] ""  BMU_ID_0

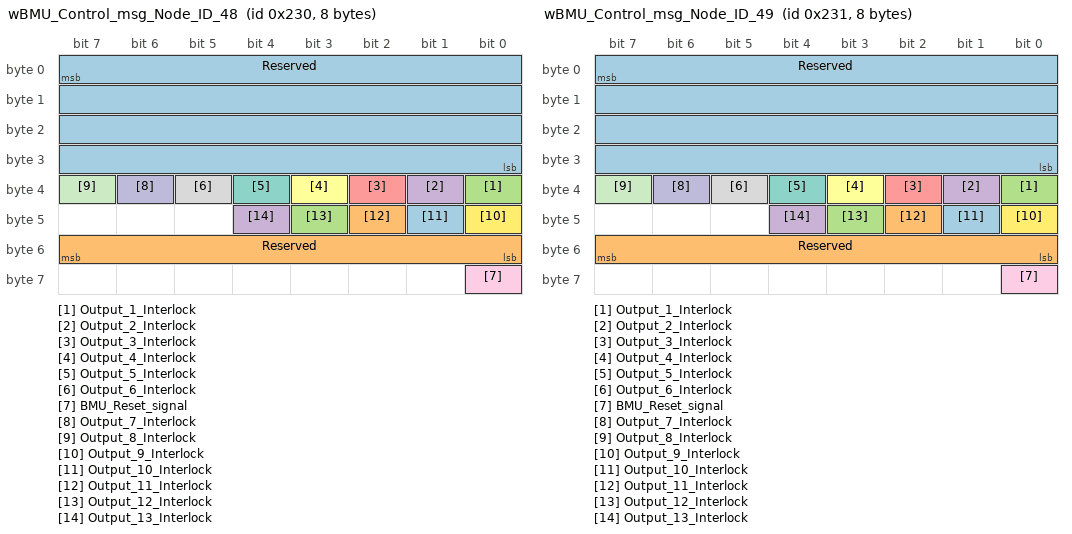
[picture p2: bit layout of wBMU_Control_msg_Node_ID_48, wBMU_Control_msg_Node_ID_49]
BO_ 560 wBMU_Control_msg_Node_ID_48: 8 Vector__XXX
 SG_ Reserved : 7|32@0+ (1,0) [0|0] "" Vector__XXX
 SG_ Reserved : 55|8@0+ (1,0) [0|0] "" Vector__XXX
 SG_ Output_1_Interlock : 32|1@0+ (1,0) [0|0] "" Vector__XXX
 SG_ Output_2_Interlock : 33|1@0+ (1,0) [0|0] "" Vector__XXX
 SG_ Output_3_Interlock : 34|1@0+ (1,0) [0|0] "" Vector__XXX
 SG_ Output_4_Interlock : 35|1@0+ (1,0) [0|0] "" Vector__XXX
 SG_ Output_5_Interlock : 36|1@0+ (1,0) [0|0] "" Vector__XXX
 SG_ Output_6_Interlock : 37|1@0+ (1,0) [0|0] "" Vector__XXX
 SG_ BMU_Reset_signal : 56|1@0+ (1,0) [0|0] "" Vector__XXX
 SG_ Output_7_Interlock : 38|1@0+ (1,0) [0|0] "" Vector__XXX
 SG_ Output_8_Interlock : 39|1@0+ (1,0) [0|0] "" Vector__XXX
 SG_ Output_9_Interlock : 40|1@0+ (1,0) [0|0] "" Vector__XXX
 SG_ Output_10_Interlock : 41|1@0+ (1,0) [0|0] "" Vector__XXX
 SG_ Output_11_Interlock : 42|1@0+ (1,0) [0|0] "" Vector__XXX
 SG_ Output_12_Interlock : 43|1@0+ (1,0) [0|0] "" Vector__XXX
 SG_ Output_13_Interlock : 44|1@0+ (1,0) [0|0] "" Vector__XXX

BO_ 561 wBMU_Control_msg_Node_ID_49: 8 Vector__XXX
 SG_ Reserved : 7|32@0+ (1,0) [0|0] "" Vector__XXX
 SG_ Reserved : 55|8@0+ (1,0) [0|0] "" Vector__XXX
 SG_ Output_1_Interlock : 32|1@0+ (1,0) [0|0] "" Vector__XXX
 SG_ Output_2_Interlock : 33|1@0+ (1,0) [0|0] "" Vector__XXX
 SG_ Output_3_Interlock : 34|1@0+ (1,0) [0|0] "" Vector__XXX
 SG_ Output_4_Interlock : 35|1@0+ (1,0) [0|0] "" Vector__XXX
 SG_ Output_5_Interlock : 36|1@0+ (1,0) [0|0] "" Vector__XXX
 SG_ Output_6_Interlock : 37|1@0+ (1,0) [0|0] "" Vector__XXX
 SG_ BMU_Reset_signal : 56|1@0+ (1,0) [0|0] "" Vector__XXX
 SG_ Output_7_Interlock : 38|1@0+ (1,0) [0|0] "" Vector__XXX
 SG_ Output_8_Interlock : 39|1@0+ (1,0) [0|0] "" Vector__XXX
 SG_ Output_9_Interlock : 40|1@0+ (1,0) [0|0] "" Vector__XXX
 SG_ Output_10_Interlock : 41|1@0+ (1,0) [0|0] "" Vector__XXX
 SG_ Output_11_Interlock : 42|1@0+ (1,0) [0|0] "" Vector__XXX
 SG_ Output_12_Interlock : 43|1@0+ (1,0) [0|0] "" Vector__XXX
 SG_ Output_13_Interlock : 44|1@0+ (1,0) [0|0] "" Vector__XXX

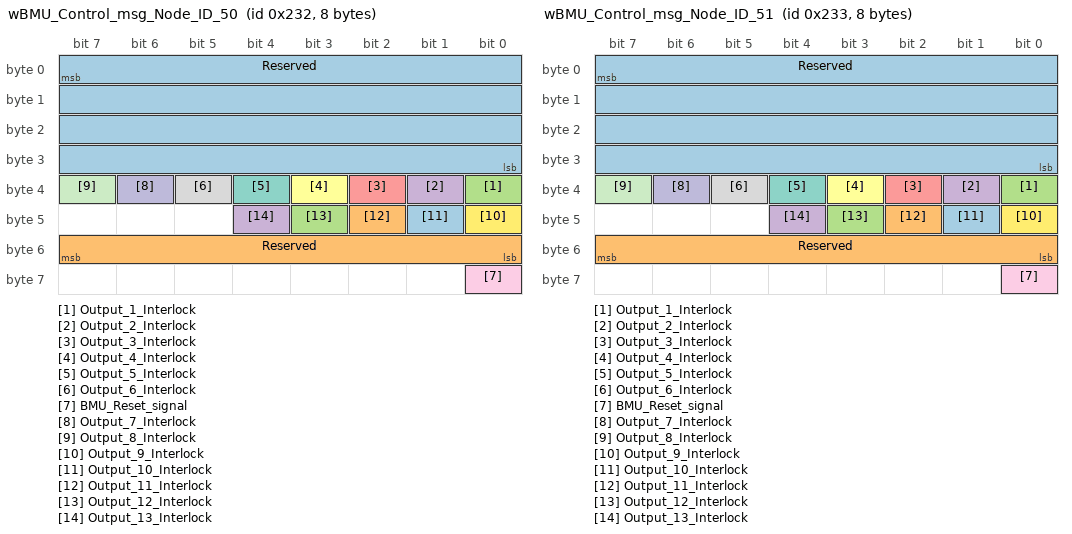
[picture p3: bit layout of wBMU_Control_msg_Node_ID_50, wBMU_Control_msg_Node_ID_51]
BO_ 562 wBMU_Control_msg_Node_ID_50: 8 Vector__XXX
 SG_ Reserved : 7|32@0+ (1,0) [0|0] "" Vector__XXX
 SG_ Reserved : 55|8@0+ (1,0) [0|0] "" Vector__XXX
 SG_ Output_1_Interlock : 32|1@0+ (1,0) [0|0] "" Vector__XXX
 SG_ Output_2_Interlock : 33|1@0+ (1,0) [0|0] "" Vector__XXX
 SG_ Output_3_Interlock : 34|1@0+ (1,0) [0|0] "" Vector__XXX
 SG_ Output_4_Interlock : 35|1@0+ (1,0) [0|0] "" Vector__XXX
 SG_ Output_5_Interlock : 36|1@0+ (1,0) [0|0] "" Vector__XXX
 SG_ Output_6_Interlock : 37|1@0+ (1,0) [0|0] "" Vector__XXX
 SG_ BMU_Reset_signal : 56|1@0+ (1,0) [0|0] "" Vector__XXX
 SG_ Output_7_Interlock : 38|1@0+ (1,0) [0|0] "" Vector__XXX
 SG_ Output_8_Interlock : 39|1@0+ (1,0) [0|0] "" Vector__XXX
 SG_ Output_9_Interlock : 40|1@0+ (1,0) [0|0] "" Vector__XXX
 SG_ Output_10_Interlock : 41|1@0+ (1,0) [0|0] "" Vector__XXX
 SG_ Output_11_Interlock : 42|1@0+ (1,0) [0|0] "" Vector__XXX
 SG_ Output_12_Interlock : 43|1@0+ (1,0) [0|0] "" Vector__XXX
 SG_ Output_13_Interlock : 44|1@0+ (1,0) [0|0] "" Vector__XXX

BO_ 563 wBMU_Control_msg_Node_ID_51: 8 Vector__XXX
 SG_ Reserved : 7|32@0+ (1,0) [0|0] "" Vector__XXX
 SG_ Reserved : 55|8@0+ (1,0) [0|0] "" Vector__XXX
 SG_ Output_1_Interlock : 32|1@0+ (1,0) [0|0] "" Vector__XXX
 SG_ Output_2_Interlock : 33|1@0+ (1,0) [0|0] "" Vector__XXX
 SG_ Output_3_Interlock : 34|1@0+ (1,0) [0|0] "" Vector__XXX
 SG_ Output_4_Interlock : 35|1@0+ (1,0) [0|0] "" Vector__XXX
 SG_ Output_5_Interlock : 36|1@0+ (1,0) [0|0] "" Vector__XXX
 SG_ Output_6_Interlock : 37|1@0+ (1,0) [0|0] "" Vector__XXX
 SG_ BMU_Reset_signal : 56|1@0+ (1,0) [0|0] "" Vector__XXX
 SG_ Output_7_Interlock : 38|1@0+ (1,0) [0|0] "" Vector__XXX
 SG_ Output_8_Interlock : 39|1@0+ (1,0) [0|0] "" Vector__XXX
 SG_ Output_9_Interlock : 40|1@0+ (1,0) [0|0] "" Vector__XXX
 SG_ Output_10_Interlock : 41|1@0+ (1,0) [0|0] "" Vector__XXX
 SG_ Output_11_Interlock : 42|1@0+ (1,0) [0|0] "" Vector__XXX
 SG_ Output_12_Interlock : 43|1@0+ (1,0) [0|0] "" Vector__XXX
 SG_ Output_13_Interlock : 44|1@0+ (1,0) [0|0] "" Vector__XXX

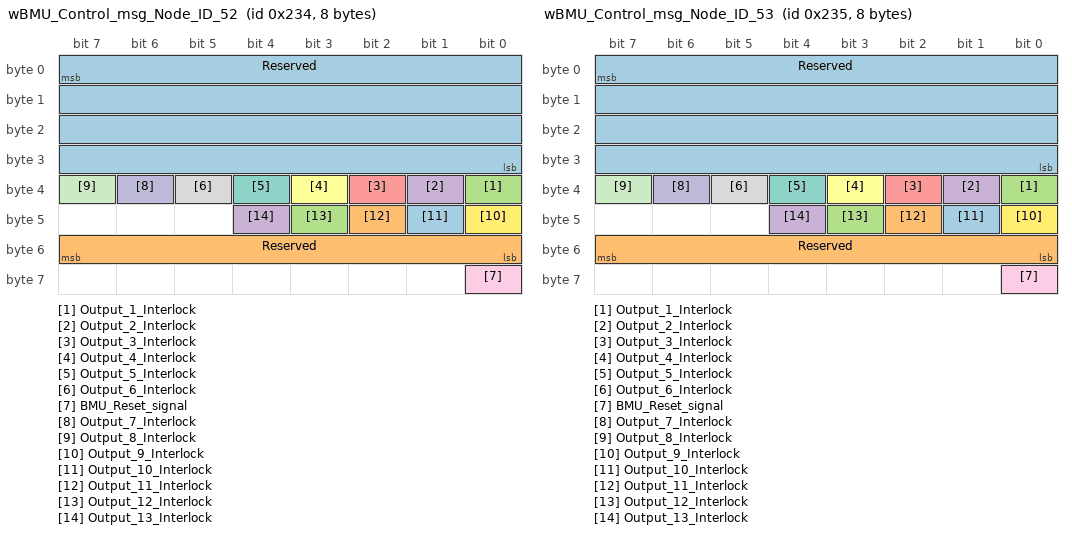
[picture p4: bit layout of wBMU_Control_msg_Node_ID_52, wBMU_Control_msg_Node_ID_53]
BO_ 564 wBMU_Control_msg_Node_ID_52: 8 Vector__XXX
 SG_ Reserved : 7|32@0+ (1,0) [0|0] "" Vector__XXX
 SG_ Reserved : 55|8@0+ (1,0) [0|0] "" Vector__XXX
 SG_ Output_1_Interlock : 32|1@0+ (1,0) [0|0] "" Vector__XXX
 SG_ Output_2_Interlock : 33|1@0+ (1,0) [0|0] "" Vector__XXX
 SG_ Output_3_Interlock : 34|1@0+ (1,0) [0|0] "" Vector__XXX
 SG_ Output_4_Interlock : 35|1@0+ (1,0) [0|0] "" Vector__XXX
 SG_ Output_5_Interlock : 36|1@0+ (1,0) [0|0] "" Vector__XXX
 SG_ Output_6_Interlock : 37|1@0+ (1,0) [0|0] "" Vector__XXX
 SG_ BMU_Reset_signal : 56|1@0+ (1,0) [0|0] "" Vector__XXX
 SG_ Output_7_Interlock : 38|1@0+ (1,0) [0|0] "" Vector__XXX
 SG_ Output_8_Interlock : 39|1@0+ (1,0) [0|0] "" Vector__XXX
 SG_ Output_9_Interlock : 40|1@0+ (1,0) [0|0] "" Vector__XXX
 SG_ Output_10_Interlock : 41|1@0+ (1,0) [0|0] "" Vector__XXX
 SG_ Output_11_Interlock : 42|1@0+ (1,0) [0|0] "" Vector__XXX
 SG_ Output_12_Interlock : 43|1@0+ (1,0) [0|0] "" Vector__XXX
 SG_ Output_13_Interlock : 44|1@0+ (1,0) [0|0] "" Vector__XXX

BO_ 565 wBMU_Control_msg_Node_ID_53: 8 Vector__XXX
 SG_ Reserved : 7|32@0+ (1,0) [0|0] "" Vector__XXX
 SG_ Reserved : 55|8@0+ (1,0) [0|0] "" Vector__XXX
 SG_ Output_1_Interlock : 32|1@0+ (1,0) [0|0] "" Vector__XXX
 SG_ Output_2_Interlock : 33|1@0+ (1,0) [0|0] "" Vector__XXX
 SG_ Output_3_Interlock : 34|1@0+ (1,0) [0|0] "" Vector__XXX
 SG_ Output_4_Interlock : 35|1@0+ (1,0) [0|0] "" Vector__XXX
 SG_ Output_5_Interlock : 36|1@0+ (1,0) [0|0] "" Vector__XXX
 SG_ Output_6_Interlock : 37|1@0+ (1,0) [0|0] "" Vector__XXX
 SG_ BMU_Reset_signal : 56|1@0+ (1,0) [0|0] "" Vector__XXX
 SG_ Output_7_Interlock : 38|1@0+ (1,0) [0|0] "" Vector__XXX
 SG_ Output_8_Interlock : 39|1@0+ (1,0) [0|0] "" Vector__XXX
 SG_ Output_9_Interlock : 40|1@0+ (1,0) [0|0] "" Vector__XXX
 SG_ Output_10_Interlock : 41|1@0+ (1,0) [0|0] "" Vector__XXX
 SG_ Output_11_Interlock : 42|1@0+ (1,0) [0|0] "" Vector__XXX
 SG_ Output_12_Interlock : 43|1@0+ (1,0) [0|0] "" Vector__XXX
 SG_ Output_13_Interlock : 44|1@0+ (1,0) [0|0] "" Vector__XXX

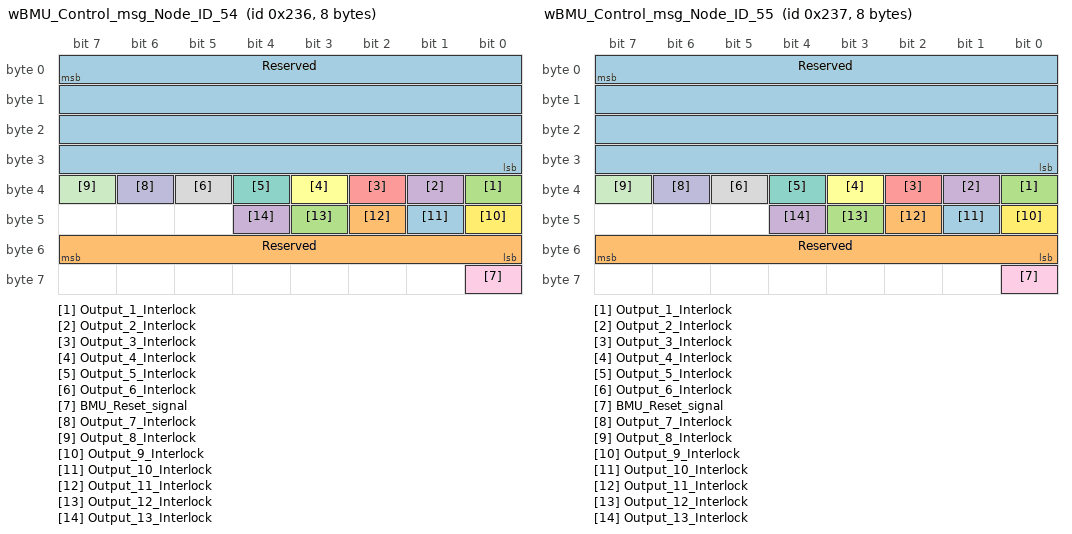
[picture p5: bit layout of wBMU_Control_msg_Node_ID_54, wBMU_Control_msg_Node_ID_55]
BO_ 566 wBMU_Control_msg_Node_ID_54: 8 Vector__XXX
 SG_ Reserved : 7|32@0+ (1,0) [0|0] "" Vector__XXX
 SG_ Reserved : 55|8@0+ (1,0) [0|0] "" Vector__XXX
 SG_ Output_1_Interlock : 32|1@0+ (1,0) [0|0] "" Vector__XXX
 SG_ Output_2_Interlock : 33|1@0+ (1,0) [0|0] "" Vector__XXX
 SG_ Output_3_Interlock : 34|1@0+ (1,0) [0|0] "" Vector__XXX
 SG_ Output_4_Interlock : 35|1@0+ (1,0) [0|0] "" Vector__XXX
 SG_ Output_5_Interlock : 36|1@0+ (1,0) [0|0] "" Vector__XXX
 SG_ Output_6_Interlock : 37|1@0+ (1,0) [0|0] "" Vector__XXX
 SG_ BMU_Reset_signal : 56|1@0+ (1,0) [0|0] "" Vector__XXX
 SG_ Output_7_Interlock : 38|1@0+ (1,0) [0|0] "" Vector__XXX
 SG_ Output_8_Interlock : 39|1@0+ (1,0) [0|0] "" Vector__XXX
 SG_ Output_9_Interlock : 40|1@0+ (1,0) [0|0] "" Vector__XXX
 SG_ Output_10_Interlock : 41|1@0+ (1,0) [0|0] "" Vector__XXX
 SG_ Output_11_Interlock : 42|1@0+ (1,0) [0|0] "" Vector__XXX
 SG_ Output_12_Interlock : 43|1@0+ (1,0) [0|0] "" Vector__XXX
 SG_ Output_13_Interlock : 44|1@0+ (1,0) [0|0] "" Vector__XXX

BO_ 567 wBMU_Control_msg_Node_ID_55: 8 Vector__XXX
 SG_ Reserved : 7|32@0+ (1,0) [0|0] "" Vector__XXX
 SG_ Reserved : 55|8@0+ (1,0) [0|0] "" Vector__XXX
 SG_ Output_1_Interlock : 32|1@0+ (1,0) [0|0] "" Vector__XXX
 SG_ Output_2_Interlock : 33|1@0+ (1,0) [0|0] "" Vector__XXX
 SG_ Output_3_Interlock : 34|1@0+ (1,0) [0|0] "" Vector__XXX
 SG_ Output_4_Interlock : 35|1@0+ (1,0) [0|0] "" Vector__XXX
 SG_ Output_5_Interlock : 36|1@0+ (1,0) [0|0] "" Vector__XXX
 SG_ Output_6_Interlock : 37|1@0+ (1,0) [0|0] "" Vector__XXX
 SG_ BMU_Reset_signal : 56|1@0+ (1,0) [0|0] "" Vector__XXX
 SG_ Output_7_Interlock : 38|1@0+ (1,0) [0|0] "" Vector__XXX
 SG_ Output_8_Interlock : 39|1@0+ (1,0) [0|0] "" Vector__XXX
 SG_ Output_9_Interlock : 40|1@0+ (1,0) [0|0] "" Vector__XXX
 SG_ Output_10_Interlock : 41|1@0+ (1,0) [0|0] "" Vector__XXX
 SG_ Output_11_Interlock : 42|1@0+ (1,0) [0|0] "" Vector__XXX
 SG_ Output_12_Interlock : 43|1@0+ (1,0) [0|0] "" Vector__XXX
 SG_ Output_13_Interlock : 44|1@0+ (1,0) [0|0] "" Vector__XXX

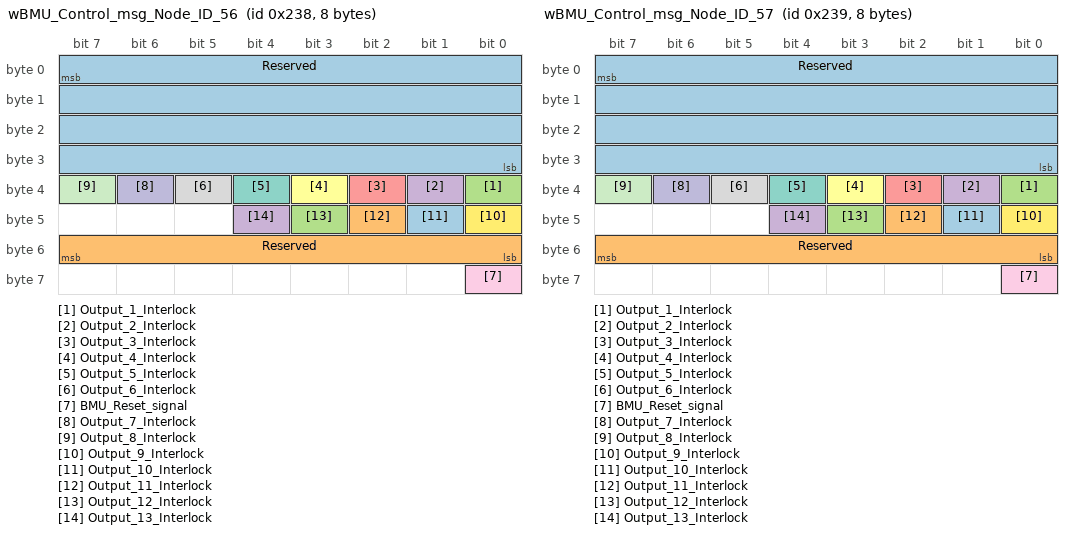
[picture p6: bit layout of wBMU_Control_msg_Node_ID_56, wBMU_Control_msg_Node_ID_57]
BO_ 568 wBMU_Control_msg_Node_ID_56: 8 Vector__XXX
 SG_ Reserved : 7|32@0+ (1,0) [0|0] "" Vector__XXX
 SG_ Reserved : 55|8@0+ (1,0) [0|0] "" Vector__XXX
 SG_ Output_1_Interlock : 32|1@0+ (1,0) [0|0] "" Vector__XXX
 SG_ Output_2_Interlock : 33|1@0+ (1,0) [0|0] "" Vector__XXX
 SG_ Output_3_Interlock : 34|1@0+ (1,0) [0|0] "" Vector__XXX
 SG_ Output_4_Interlock : 35|1@0+ (1,0) [0|0] "" Vector__XXX
 SG_ Output_5_Interlock : 36|1@0+ (1,0) [0|0] "" Vector__XXX
 SG_ Output_6_Interlock : 37|1@0+ (1,0) [0|0] "" Vector__XXX
 SG_ BMU_Reset_signal : 56|1@0+ (1,0) [0|0] "" Vector__XXX
 SG_ Output_7_Interlock : 38|1@0+ (1,0) [0|0] "" Vector__XXX
 SG_ Output_8_Interlock : 39|1@0+ (1,0) [0|0] "" Vector__XXX
 SG_ Output_9_Interlock : 40|1@0+ (1,0) [0|0] "" Vector__XXX
 SG_ Output_10_Interlock : 41|1@0+ (1,0) [0|0] "" Vector__XXX
 SG_ Output_11_Interlock : 42|1@0+ (1,0) [0|0] "" Vector__XXX
 SG_ Output_12_Interlock : 43|1@0+ (1,0) [0|0] "" Vector__XXX
 SG_ Output_13_Interlock : 44|1@0+ (1,0) [0|0] "" Vector__XXX

BO_ 569 wBMU_Control_msg_Node_ID_57: 8 Vector__XXX
 SG_ Reserved : 7|32@0+ (1,0) [0|0] "" Vector__XXX
 SG_ Reserved : 55|8@0+ (1,0) [0|0] "" Vector__XXX
 SG_ Output_1_Interlock : 32|1@0+ (1,0) [0|0] "" Vector__XXX
 SG_ Output_2_Interlock : 33|1@0+ (1,0) [0|0] "" Vector__XXX
 SG_ Output_3_Interlock : 34|1@0+ (1,0) [0|0] "" Vector__XXX
 SG_ Output_4_Interlock : 35|1@0+ (1,0) [0|0] "" Vector__XXX
 SG_ Output_5_Interlock : 36|1@0+ (1,0) [0|0] "" Vector__XXX
 SG_ Output_6_Interlock : 37|1@0+ (1,0) [0|0] "" Vector__XXX
 SG_ BMU_Reset_signal : 56|1@0+ (1,0) [0|0] "" Vector__XXX
 SG_ Output_7_Interlock : 38|1@0+ (1,0) [0|0] "" Vector__XXX
 SG_ Output_8_Interlock : 39|1@0+ (1,0) [0|0] "" Vector__XXX
 SG_ Output_9_Interlock : 40|1@0+ (1,0) [0|0] "" Vector__XXX
 SG_ Output_10_Interlock : 41|1@0+ (1,0) [0|0] "" Vector__XXX
 SG_ Output_11_Interlock : 42|1@0+ (1,0) [0|0] "" Vector__XXX
 SG_ Output_12_Interlock : 43|1@0+ (1,0) [0|0] "" Vector__XXX
 SG_ Output_13_Interlock : 44|1@0+ (1,0) [0|0] "" Vector__XXX

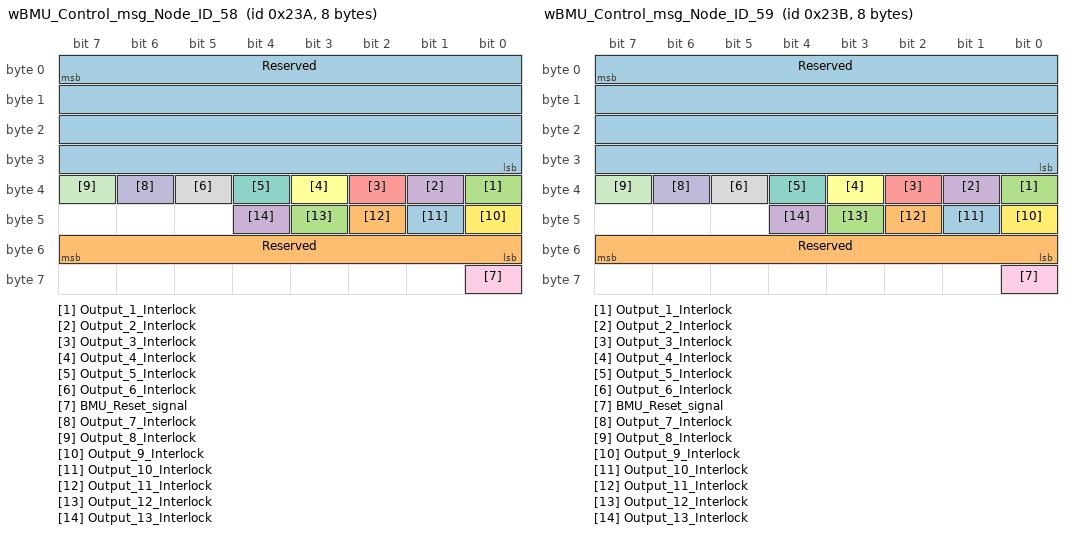
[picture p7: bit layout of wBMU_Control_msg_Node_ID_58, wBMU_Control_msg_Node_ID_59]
BO_ 570 wBMU_Control_msg_Node_ID_58: 8 Vector__XXX
 SG_ Reserved : 7|32@0+ (1,0) [0|0] "" Vector__XXX
 SG_ Reserved : 55|8@0+ (1,0) [0|0] "" Vector__XXX
 SG_ Output_1_Interlock : 32|1@0+ (1,0) [0|0] "" Vector__XXX
 SG_ Output_2_Interlock : 33|1@0+ (1,0) [0|0] "" Vector__XXX
 SG_ Output_3_Interlock : 34|1@0+ (1,0) [0|0] "" Vector__XXX
 SG_ Output_4_Interlock : 35|1@0+ (1,0) [0|0] "" Vector__XXX
 SG_ Output_5_Interlock : 36|1@0+ (1,0) [0|0] "" Vector__XXX
 SG_ Output_6_Interlock : 37|1@0+ (1,0) [0|0] "" Vector__XXX
 SG_ BMU_Reset_signal : 56|1@0+ (1,0) [0|0] "" Vector__XXX
 SG_ Output_7_Interlock : 38|1@0+ (1,0) [0|0] "" Vector__XXX
 SG_ Output_8_Interlock : 39|1@0+ (1,0) [0|0] "" Vector__XXX
 SG_ Output_9_Interlock : 40|1@0+ (1,0) [0|0] "" Vector__XXX
 SG_ Output_10_Interlock : 41|1@0+ (1,0) [0|0] "" Vector__XXX
 SG_ Output_11_Interlock : 42|1@0+ (1,0) [0|0] "" Vector__XXX
 SG_ Output_12_Interlock : 43|1@0+ (1,0) [0|0] "" Vector__XXX
 SG_ Output_13_Interlock : 44|1@0+ (1,0) [0|0] "" Vector__XXX

BO_ 571 wBMU_Control_msg_Node_ID_59: 8 Vector__XXX
 SG_ Reserved : 7|32@0+ (1,0) [0|0] "" Vector__XXX
 SG_ Reserved : 55|8@0+ (1,0) [0|0] "" Vector__XXX
 SG_ Output_1_Interlock : 32|1@0+ (1,0) [0|0] "" Vector__XXX
 SG_ Output_2_Interlock : 33|1@0+ (1,0) [0|0] "" Vector__XXX
 SG_ Output_3_Interlock : 34|1@0+ (1,0) [0|0] "" Vector__XXX
 SG_ Output_4_Interlock : 35|1@0+ (1,0) [0|0] "" Vector__XXX
 SG_ Output_5_Interlock : 36|1@0+ (1,0) [0|0] "" Vector__XXX
 SG_ Output_6_Interlock : 37|1@0+ (1,0) [0|0] "" Vector__XXX
 SG_ BMU_Reset_signal : 56|1@0+ (1,0) [0|0] "" Vector__XXX
 SG_ Output_7_Interlock : 38|1@0+ (1,0) [0|0] "" Vector__XXX
 SG_ Output_8_Interlock : 39|1@0+ (1,0) [0|0] "" Vector__XXX
 SG_ Output_9_Interlock : 40|1@0+ (1,0) [0|0] "" Vector__XXX
 SG_ Output_10_Interlock : 41|1@0+ (1,0) [0|0] "" Vector__XXX
 SG_ Output_11_Interlock : 42|1@0+ (1,0) [0|0] "" Vector__XXX
 SG_ Output_12_Interlock : 43|1@0+ (1,0) [0|0] "" Vector__XXX
 SG_ Output_13_Interlock : 44|1@0+ (1,0) [0|0] "" Vector__XXX

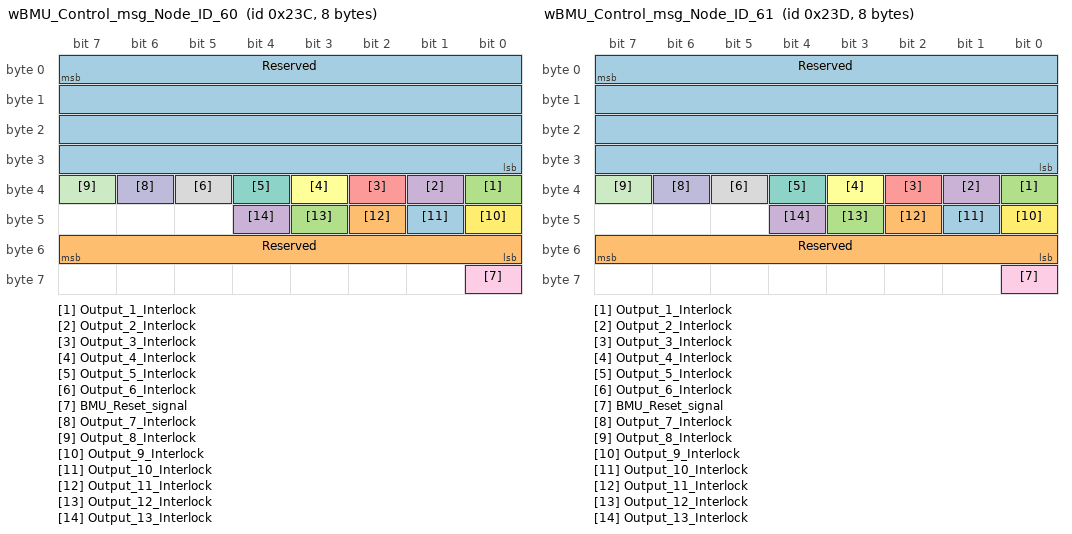
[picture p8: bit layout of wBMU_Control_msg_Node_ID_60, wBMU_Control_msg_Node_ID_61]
BO_ 572 wBMU_Control_msg_Node_ID_60: 8 Vector__XXX
 SG_ Reserved : 7|32@0+ (1,0) [0|0] "" Vector__XXX
 SG_ Reserved : 55|8@0+ (1,0) [0|0] "" Vector__XXX
 SG_ Output_1_Interlock : 32|1@0+ (1,0) [0|0] "" Vector__XXX
 SG_ Output_2_Interlock : 33|1@0+ (1,0) [0|0] "" Vector__XXX
 SG_ Output_3_Interlock : 34|1@0+ (1,0) [0|0] "" Vector__XXX
 SG_ Output_4_Interlock : 35|1@0+ (1,0) [0|0] "" Vector__XXX
 SG_ Output_5_Interlock : 36|1@0+ (1,0) [0|0] "" Vector__XXX
 SG_ Output_6_Interlock : 37|1@0+ (1,0) [0|0] "" Vector__XXX
 SG_ BMU_Reset_signal : 56|1@0+ (1,0) [0|0] "" Vector__XXX
 SG_ Output_7_Interlock : 38|1@0+ (1,0) [0|0] "" Vector__XXX
 SG_ Output_8_Interlock : 39|1@0+ (1,0) [0|0] "" Vector__XXX
 SG_ Output_9_Interlock : 40|1@0+ (1,0) [0|0] "" Vector__XXX
 SG_ Output_10_Interlock : 41|1@0+ (1,0) [0|0] "" Vector__XXX
 SG_ Output_11_Interlock : 42|1@0+ (1,0) [0|0] "" Vector__XXX
 SG_ Output_12_Interlock : 43|1@0+ (1,0) [0|0] "" Vector__XXX
 SG_ Output_13_Interlock : 44|1@0+ (1,0) [0|0] "" Vector__XXX

BO_ 573 wBMU_Control_msg_Node_ID_61: 8 Vector__XXX
 SG_ Reserved : 7|32@0+ (1,0) [0|0] "" Vector__XXX
 SG_ Reserved : 55|8@0+ (1,0) [0|0] "" Vector__XXX
 SG_ Output_1_Interlock : 32|1@0+ (1,0) [0|0] "" Vector__XXX
 SG_ Output_2_Interlock : 33|1@0+ (1,0) [0|0] "" Vector__XXX
 SG_ Output_3_Interlock : 34|1@0+ (1,0) [0|0] "" Vector__XXX
 SG_ Output_4_Interlock : 35|1@0+ (1,0) [0|0] "" Vector__XXX
 SG_ Output_5_Interlock : 36|1@0+ (1,0) [0|0] "" Vector__XXX
 SG_ Output_6_Interlock : 37|1@0+ (1,0) [0|0] "" Vector__XXX
 SG_ BMU_Reset_signal : 56|1@0+ (1,0) [0|0] "" Vector__XXX
 SG_ Output_7_Interlock : 38|1@0+ (1,0) [0|0] "" Vector__XXX
 SG_ Output_8_Interlock : 39|1@0+ (1,0) [0|0] "" Vector__XXX
 SG_ Output_9_Interlock : 40|1@0+ (1,0) [0|0] "" Vector__XXX
 SG_ Output_10_Interlock : 41|1@0+ (1,0) [0|0] "" Vector__XXX
 SG_ Output_11_Interlock : 42|1@0+ (1,0) [0|0] "" Vector__XXX
 SG_ Output_12_Interlock : 43|1@0+ (1,0) [0|0] "" Vector__XXX
 SG_ Output_13_Interlock : 44|1@0+ (1,0) [0|0] "" Vector__XXX

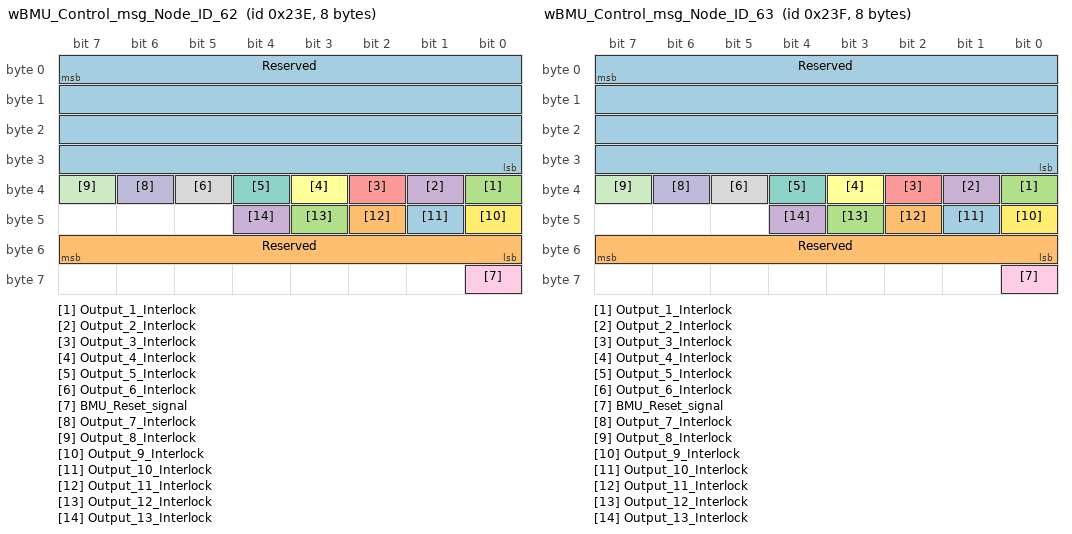
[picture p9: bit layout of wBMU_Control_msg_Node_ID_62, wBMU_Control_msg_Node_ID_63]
BO_ 574 wBMU_Control_msg_Node_ID_62: 8 Vector__XXX
 SG_ Reserved : 7|32@0+ (1,0) [0|0] "" Vector__XXX
 SG_ Reserved : 55|8@0+ (1,0) [0|0] "" Vector__XXX
 SG_ Output_1_Interlock : 32|1@0+ (1,0) [0|0] "" Vector__XXX
 SG_ Output_2_Interlock : 33|1@0+ (1,0) [0|0] "" Vector__XXX
 SG_ Output_3_Interlock : 34|1@0+ (1,0) [0|0] "" Vector__XXX
 SG_ Output_4_Interlock : 35|1@0+ (1,0) [0|0] "" Vector__XXX
 SG_ Output_5_Interlock : 36|1@0+ (1,0) [0|0] "" Vector__XXX
 SG_ Output_6_Interlock : 37|1@0+ (1,0) [0|0] "" Vector__XXX
 SG_ BMU_Reset_signal : 56|1@0+ (1,0) [0|0] "" Vector__XXX
 SG_ Output_7_Interlock : 38|1@0+ (1,0) [0|0] "" Vector__XXX
 SG_ Output_8_Interlock : 39|1@0+ (1,0) [0|0] "" Vector__XXX
 SG_ Output_9_Interlock : 40|1@0+ (1,0) [0|0] "" Vector__XXX
 SG_ Output_10_Interlock : 41|1@0+ (1,0) [0|0] "" Vector__XXX
 SG_ Output_11_Interlock : 42|1@0+ (1,0) [0|0] "" Vector__XXX
 SG_ Output_12_Interlock : 43|1@0+ (1,0) [0|0] "" Vector__XXX
 SG_ Output_13_Interlock : 44|1@0+ (1,0) [0|0] "" Vector__XXX

BO_ 575 wBMU_Control_msg_Node_ID_63: 8 Vector__XXX
 SG_ Reserved : 7|32@0+ (1,0) [0|0] "" Vector__XXX
 SG_ Reserved : 55|8@0+ (1,0) [0|0] "" Vector__XXX
 SG_ Output_1_Interlock : 32|1@0+ (1,0) [0|0] "" Vector__XXX
 SG_ Output_2_Interlock : 33|1@0+ (1,0) [0|0] "" Vector__XXX
 SG_ Output_3_Interlock : 34|1@0+ (1,0) [0|0] "" Vector__XXX
 SG_ Output_4_Interlock : 35|1@0+ (1,0) [0|0] "" Vector__XXX
 SG_ Output_5_Interlock : 36|1@0+ (1,0) [0|0] "" Vector__XXX
 SG_ Output_6_Interlock : 37|1@0+ (1,0) [0|0] "" Vector__XXX
 SG_ BMU_Reset_signal : 56|1@0+ (1,0) [0|0] "" Vector__XXX
 SG_ Output_7_Interlock : 38|1@0+ (1,0) [0|0] "" Vector__XXX
 SG_ Output_8_Interlock : 39|1@0+ (1,0) [0|0] "" Vector__XXX
 SG_ Output_9_Interlock : 40|1@0+ (1,0) [0|0] "" Vector__XXX
 SG_ Output_10_Interlock : 41|1@0+ (1,0) [0|0] "" Vector__XXX
 SG_ Output_11_Interlock : 42|1@0+ (1,0) [0|0] "" Vector__XXX
 SG_ Output_12_Interlock : 43|1@0+ (1,0) [0|0] "" Vector__XXX
 SG_ Output_13_Interlock : 44|1@0+ (1,0) [0|0] "" Vector__XXX

CM_ SG_ 1484 State_of_Charge "BMU state of charge (SoC)";
CM_ SG_ 1484 State_of_Health "BMU state of health (SoH)";
CM_ SG_ 1484 Number_balancing_cells "Number of cells currently balancing.";
CM_ SG_ 1485 State_of_Charge "BMU state of charge (SoC)";
CM_ SG_ 1485 State_of_Health "BMU state of health (SoH)";
CM_ SG_ 1485 Number_balancing_cells "Number of cells currently balancing.";
CM_ SG_ 1486 State_of_Charge "BMU state of charge (SoC)";
CM_ SG_ 1486 State_of_Health "BMU state of health (SoH)";
CM_ SG_ 1486 Number_balancing_cells "Number of cells currently balancing.";
CM_ SG_ 1487 State_of_Charge "BMU state of charge (SoC)";
CM_ SG_ 1487 State_of_Health "BMU state of health (SoH)";
CM_ SG_ 1487 Number_balancing_cells "Number of cells currently balancing.";
CM_ BO_ 1488 "io = inputs and outputs";
CM_ SG_ 1488 Analog_input_1 "Analog Input 6 (HX, MX-Pro) OR Analog Input 5 (R32, R24 and MX)";
CM_ SG_ 1488 Analog_input_2 "Analog Input 7 (HX, MX-Pro) OR Analog Input 6 (R32, R24 and MX)";
CM_ SG_ 1488 Analog_input_3 "Analog Input 8 (HX, MX-Pro) OR empty registers (R32, R24 and MX)";
CM_ BO_ 1489 "io = inputs and outputs";
CM_ SG_ 1489 Analog_input_1 "Analog Input 6 (HX, MX-Pro) OR Analog Input 5 (R32, R24 and MX)";
CM_ SG_ 1489 Analog_input_2 "Analog Input 7 (HX, MX-Pro) OR Analog Input 6 (R32, R24 and MX)";
CM_ SG_ 1489 Analog_input_3 "Analog Input 8 (HX, MX-Pro) OR empty registers (R32, R24 and MX)";
CM_ BO_ 1490 "io = inputs and outputs";
CM_ SG_ 1490 Analog_input_1 "Analog Input 6 (HX, MX-Pro) OR Analog Input 5 (R32, R24 and MX)";
CM_ SG_ 1490 Analog_input_2 "Analog Input 7 (HX, MX-Pro) OR Analog Input 6 (R32, R24 and MX)";
CM_ SG_ 1490 Analog_input_3 "Analog Input 8 (HX, MX-Pro) OR empty registers (R32, R24 and MX)";
CM_ BO_ 1491 "io = inputs and outputs";
CM_ SG_ 1491 Analog_input_1 "Analog Input 6 (HX, MX-Pro) OR Analog Input 5 (R32, R24 and MX)";
CM_ SG_ 1491 Analog_input_2 "Analog Input 7 (HX, MX-Pro) OR Analog Input 6 (R32, R24 and MX)";
CM_ SG_ 1491 Analog_input_3 "Analog Input 8 (HX, MX-Pro) OR empty registers (R32, R24 and MX)";
CM_ BO_ 1492 "io = inputs and outputs";
CM_ SG_ 1492 Analog_input_1 "Analog Input 6 (HX, MX-Pro) OR Analog Input 5 (R32, R24 and MX)";
CM_ SG_ 1492 Analog_input_2 "Analog Input 7 (HX, MX-Pro) OR Analog Input 6 (R32, R24 and MX)";
CM_ SG_ 1492 Analog_input_3 "Analog Input 8 (HX, MX-Pro) OR empty registers (R32, R24 and MX)";
CM_ BO_ 1493 "io = inputs and outputs";
CM_ SG_ 1493 Analog_input_1 "Analog Input 6 (HX, MX-Pro) OR Analog Input 5 (R32, R24 and MX)";
CM_ SG_ 1493 Analog_input_2 "Analog Input 7 (HX, MX-Pro) OR Analog Input 6 (R32, R24 and MX)";
CM_ SG_ 1493 Analog_input_3 "Analog Input 8 (HX, MX-Pro) OR empty registers (R32, R24 and MX)";
CM_ BO_ 1494 "io = inputs and outputs";
CM_ SG_ 1494 Analog_input_1 "Analog Input 6 (HX, MX-Pro) OR Analog Input 5 (R32, R24 and MX)";
CM_ SG_ 1494 Analog_input_2 "Analog Input 7 (HX, MX-Pro) OR Analog Input 6 (R32, R24 and MX)";
CM_ SG_ 1494 Analog_input_3 "Analog Input 8 (HX, MX-Pro) OR empty registers (R32, R24 and MX)";
CM_ BO_ 1495 "io = inputs and outputs";
CM_ SG_ 1495 Analog_input_1 "Analog Input 6 (HX, MX-Pro) OR Analog Input 5 (R32, R24 and MX)";
CM_ SG_ 1495 Analog_input_2 "Analog Input 7 (HX, MX-Pro) OR Analog Input 6 (R32, R24 and MX)";
CM_ SG_ 1495 Analog_input_3 "Analog Input 8 (HX, MX-Pro) OR empty registers (R32, R24 and MX)";
CM_ BO_ 1496 "io = inputs and outputs";
CM_ SG_ 1496 Analog_input_1 "Analog Input 6 (HX, MX-Pro) OR Analog Input 5 (R32, R24 and MX)";
CM_ SG_ 1496 Analog_input_2 "Analog Input 7 (HX, MX-Pro) OR Analog Input 6 (R32, R24 and MX)";
CM_ SG_ 1496 Analog_input_3 "Analog Input 8 (HX, MX-Pro) OR empty registers (R32, R24 and MX)";
CM_ BO_ 1497 "io = inputs and outputs";
CM_ SG_ 1497 Analog_input_1 "Analog Input 6 (HX, MX-Pro) OR Analog Input 5 (R32, R24 and MX)";
CM_ SG_ 1497 Analog_input_2 "Analog Input 7 (HX, MX-Pro) OR Analog Input 6 (R32, R24 and MX)";
CM_ SG_ 1497 Analog_input_3 "Analog Input 8 (HX, MX-Pro) OR empty registers (R32, R24 and MX)";
CM_ BO_ 1498 "io = inputs and outputs";
CM_ SG_ 1498 Analog_input_1 "Analog Input 6 (HX, MX-Pro) OR Analog Input 5 (R32, R24 and MX)";
CM_ SG_ 1498 Analog_input_2 "Analog Input 7 (HX, MX-Pro) OR Analog Input 6 (R32, R24 and MX)";
CM_ SG_ 1498 Analog_input_3 "Analog Input 8 (HX, MX-Pro) OR empty registers (R32, R24 and MX)";
CM_ BO_ 1499 "io = inputs and outputs";
CM_ SG_ 1499 Analog_input_1 "Analog Input 6 (HX, MX-Pro) OR Analog Input 5 (R32, R24 and MX)";
CM_ SG_ 1499 Analog_input_2 "Analog Input 7 (HX, MX-Pro) OR Analog Input 6 (R32, R24 and MX)";
CM_ SG_ 1499 Analog_input_3 "Analog Input 8 (HX, MX-Pro) OR empty registers (R32, R24 and MX)";
CM_ BO_ 1500 "io = inputs and outputs";
CM_ SG_ 1500 Analog_input_1 "Analog Input 6 (HX, MX-Pro) OR Analog Input 5 (R32, R24 and MX)";
CM_ SG_ 1500 Analog_input_2 "Analog Input 7 (HX, MX-Pro) OR Analog Input 6 (R32, R24 and MX)";
CM_ SG_ 1500 Analog_input_3 "Analog Input 8 (HX, MX-Pro) OR empty registers (R32, R24 and MX)";
CM_ BO_ 1501 "io = inputs and outputs";
CM_ SG_ 1501 Analog_input_1 "Analog Input 6 (HX, MX-Pro) OR Analog Input 5 (R32, R24 and MX)";
CM_ SG_ 1501 Analog_input_2 "Analog Input 7 (HX, MX-Pro) OR Analog Input 6 (R32, R24 and MX)";
CM_ SG_ 1501 Analog_input_3 "Analog Input 8 (HX, MX-Pro) OR empty registers (R32, R24 and MX)";
CM_ BO_ 1502 "io = inputs and outputs";
CM_ SG_ 1502 Analog_input_1 "Analog Input 6 (HX, MX-Pro) OR Analog Input 5 (R32, R24 and MX)";
CM_ SG_ 1502 Analog_input_2 "Analog Input 7 (HX, MX-Pro) OR Analog Input 6 (R32, R24 and MX)";
CM_ SG_ 1502 Analog_input_3 "Analog Input 8 (HX, MX-Pro) OR empty registers (R32, R24 and MX)";
CM_ BO_ 1503 "io = inputs and outputs";
CM_ SG_ 1503 Analog_input_1 "Analog Input 6 (HX, MX-Pro) OR Analog Input 5 (R32, R24 and MX)";
CM_ SG_ 1503 Analog_input_2 "Analog Input 7 (HX, MX-Pro) OR Analog Input 6 (R32, R24 and MX)";
CM_ SG_ 1503 Analog_input_3 "Analog Input 8 (HX, MX-Pro) OR empty registers (R32, R24 and MX)";
CM_ SG_ 1504 Remaining_capacity "Remaining capacity in Ah of the BMU";
CM_ SG_ 1504 Contactors_opened_under_load_cnt "Times that power relays have opened while current �Maximum switching current� is exceeded";
CM_ SG_ 1504 Equivalent_cycles "Total charged capacity divided by the nominal capacity (resolution of 1 cycle)";
CM_ SG_ 1504 Cycles_since_fully_charged "Number of equivalent cycles since last fully charged (BMU has entered to CHARGED state)";
CM_ SG_ 1504 Fully_charged_counter "Number of times where the battery has been fully charged (BMU has entered to CHARGED state)";
CM_ SG_ 1504 Total_charged_energy "Integral of the BMU measured charge energy along time. Being energy, the measured current times the battery voltage";
CM_ SG_ 1504 Total_discharged_energy "Integral of the BMU measured discharge energy along time. Being energy, the measured current times the battery voltage";
CM_ SG_ 1504 Overvoltage_protection_counter "Number of times that different protections have been triggered, in this case, overvoltage";
CM_ SG_ 1504 Total_charged_capacity "Integral of the BMU measured charge current along time";
CM_ SG_ 1504 Fully_discharged_counter "Number of times where the battery has been fully discharged (BMU has entered to DISCHARGED state)";
CM_ SG_ 1504 Overcurrent_protection_counter "Number of times that different protections have been triggered, in this case, overcurrent.";
CM_ SG_ 1504 Total_discharged_capacity "Integral of the BMU measured discharge current along time.";
CM_ SG_ 1504 Overtemperature_protection_count "Number of times that different protections have been triggered, in this case, over temperature.";
CM_ SG_ 1504 Undertemperature_protection_coun "Number of times that different protections have been triggered, in this case, undertemperature.";
CM_ SG_ 1504 Undervoltage_protection_counter "Number of times that different protections have been triggered, in this case, undervoltage.";
CM_ SG_ 1505 Remaining_capacity "Remaining capacity in Ah of the BMU";
CM_ SG_ 1505 Contactors_opened_under_load_cnt "Times that power relays have opened while current �Maximum switching current� is exceeded";
CM_ SG_ 1505 Equivalent_cycles "Total charged capacity divided by the nominal capacity (resolution of 1 cycle)";
CM_ SG_ 1505 Cycles_since_fully_charged "Number of equivalent cycles since last fully charged (BMU has entered to CHARGED state)";
CM_ SG_ 1505 Fully_charged_counter "Number of times where the battery has been fully charged (BMU has entered to CHARGED state)";
CM_ SG_ 1505 Total_charged_energy "Integral of the BMU measured charge energy along time. Being energy, the measured current times the battery voltage";
CM_ SG_ 1505 Total_discharged_energy "Integral of the BMU measured discharge energy along time. Being energy, the measured current times the battery voltage";
CM_ SG_ 1505 Overvoltage_protection_counter "Number of times that different protections have been triggered, in this case, overvoltage";
CM_ SG_ 1505 Total_charged_capacity "Integral of the BMU measured charge current along time";
CM_ SG_ 1505 Fully_discharged_counter "Number of times where the battery has been fully discharged (BMU has entered to DISCHARGED state)";
CM_ SG_ 1505 Overcurrent_protection_counter "Number of times that different protections have been triggered, in this case, overcurrent.";
CM_ SG_ 1505 Total_discharged_capacity "Integral of the BMU measured discharge current along time.";
CM_ SG_ 1505 Overtemperature_protection_count "Number of times that different protections have been triggered, in this case, over temperature.";
CM_ SG_ 1505 Undertemperature_protection_coun "Number of times that different protections have been triggered, in this case, undertemperature.";
CM_ SG_ 1505 Undervoltage_protection_counter "Number of times that different protections have been triggered, in this case, undervoltage.";
CM_ SG_ 1506 Remaining_capacity "Remaining capacity in Ah of the BMU";
CM_ SG_ 1506 Contactors_opened_under_load_cnt "Times that power relays have opened while current �Maximum switching current� is exceeded";
CM_ SG_ 1506 Equivalent_cycles "Total charged capacity divided by the nominal capacity (resolution of 1 cycle)";
CM_ SG_ 1506 Cycles_since_fully_charged "Number of equivalent cycles since last fully charged (BMU has entered to CHARGED state)";
CM_ SG_ 1506 Fully_charged_counter "Number of times where the battery has been fully charged (BMU has entered to CHARGED state)";
CM_ SG_ 1506 Total_charged_energy "Integral of the BMU measured charge energy along time. Being energy, the measured current times the battery voltage";
CM_ SG_ 1506 Total_discharged_energy "Integral of the BMU measured discharge energy along time. Being energy, the measured current times the battery voltage";
CM_ SG_ 1506 Overvoltage_protection_counter "Number of times that different protections have been triggered, in this case, overvoltage";
CM_ SG_ 1506 Total_charged_capacity "Integral of the BMU measured charge current along time";
CM_ SG_ 1506 Fully_discharged_counter "Number of times where the battery has been fully discharged (BMU has entered to DISCHARGED state)";
CM_ SG_ 1506 Overcurrent_protection_counter "Number of times that different protections have been triggered, in this case, overcurrent.";
CM_ SG_ 1506 Total_discharged_capacity "Integral of the BMU measured discharge current along time.";
CM_ SG_ 1506 Overtemperature_protection_count "Number of times that different protections have been triggered, in this case, over temperature.";
CM_ SG_ 1506 Undertemperature_protection_coun "Number of times that different protections have been triggered, in this case, undertemperature.";
CM_ SG_ 1506 Undervoltage_protection_counter "Number of times that different protections have been triggered, in this case, undervoltage.";
CM_ SG_ 1507 Remaining_capacity "Remaining capacity in Ah of the BMU";
CM_ SG_ 1507 Contactors_opened_under_load_cnt "Times that power relays have opened while current �Maximum switching current� is exceeded";
CM_ SG_ 1507 Equivalent_cycles "Total charged capacity divided by the nominal capacity (resolution of 1 cycle)";
CM_ SG_ 1507 Cycles_since_fully_charged "Number of equivalent cycles since last fully charged (BMU has entered to CHARGED state)";
CM_ SG_ 1507 Fully_charged_counter "Number of times where the battery has been fully charged (BMU has entered to CHARGED state)";
CM_ SG_ 1507 Total_charged_energy "Integral of the BMU measured charge energy along time. Being energy, the measured current times the battery voltage";
CM_ SG_ 1507 Total_discharged_energy "Integral of the BMU measured discharge energy along time. Being energy, the measured current times the battery voltage";
CM_ SG_ 1507 Overvoltage_protection_counter "Number of times that different protections have been triggered, in this case, overvoltage";
CM_ SG_ 1507 Total_charged_capacity "Integral of the BMU measured charge current along time";
CM_ SG_ 1507 Fully_discharged_counter "Number of times where the battery has been fully discharged (BMU has entered to DISCHARGED state)";
CM_ SG_ 1507 Overcurrent_protection_counter "Number of times that different protections have been triggered, in this case, overcurrent.";
CM_ SG_ 1507 Total_discharged_capacity "Integral of the BMU measured discharge current along time.";
CM_ SG_ 1507 Overtemperature_protection_count "Number of times that different protections have been triggered, in this case, over temperature.";
CM_ SG_ 1507 Undertemperature_protection_coun "Number of times that different protections have been triggered, in this case, undertemperature.";
CM_ SG_ 1507 Undervoltage_protection_counter "Number of times that different protections have been triggered, in this case, undervoltage.";
CM_ SG_ 1508 Remaining_capacity "Remaining capacity in Ah of the BMU";
CM_ SG_ 1508 Contactors_opened_under_load_cnt "Times that power relays have opened while current �Maximum switching current� is exceeded";
CM_ SG_ 1508 Equivalent_cycles "Total charged capacity divided by the nominal capacity (resolution of 1 cycle)";
CM_ SG_ 1508 Cycles_since_fully_charged "Number of equivalent cycles since last fully charged (BMU has entered to CHARGED state)";
CM_ SG_ 1508 Fully_charged_counter "Number of times where the battery has been fully charged (BMU has entered to CHARGED state)";
CM_ SG_ 1508 Total_charged_energy "Integral of the BMU measured charge energy along time. Being energy, the measured current times the battery voltage";
CM_ SG_ 1508 Total_discharged_energy "Integral of the BMU measured discharge energy along time. Being energy, the measured current times the battery voltage";
CM_ SG_ 1508 Overvoltage_protection_counter "Number of times that different protections have been triggered, in this case, overvoltage";
CM_ SG_ 1508 Total_charged_capacity "Integral of the BMU measured charge current along time";
CM_ SG_ 1508 Fully_discharged_counter "Number of times where the battery has been fully discharged (BMU has entered to DISCHARGED state)";
CM_ SG_ 1508 Overcurrent_protection_counter "Number of times that different protections have been triggered, in this case, overcurrent.";
CM_ SG_ 1508 Total_discharged_capacity "Integral of the BMU measured discharge current along time.";
CM_ SG_ 1508 Overtemperature_protection_count "Number of times that different protections have been triggered, in this case, over temperature.";
CM_ SG_ 1508 Undertemperature_protection_coun "Number of times that different protections have been triggered, in this case, undertemperature.";
CM_ SG_ 1508 Undervoltage_protection_counter "Number of times that different protections have been triggered, in this case, undervoltage.";
CM_ SG_ 1509 Remaining_capacity "Remaining capacity in Ah of the BMU";
CM_ SG_ 1509 Contactors_opened_under_load_cnt "Times that power relays have opened while current �Maximum switching current� is exceeded";
CM_ SG_ 1509 Equivalent_cycles "Total charged capacity divided by the nominal capacity (resolution of 1 cycle)";
CM_ SG_ 1509 Cycles_since_fully_charged "Number of equivalent cycles since last fully charged (BMU has entered to CHARGED state)";
CM_ SG_ 1509 Fully_charged_counter "Number of times where the battery has been fully charged (BMU has entered to CHARGED state)";
CM_ SG_ 1509 Total_charged_energy "Integral of the BMU measured charge energy along time. Being energy, the measured current times the battery voltage";
CM_ SG_ 1509 Total_discharged_energy "Integral of the BMU measured discharge energy along time. Being energy, the measured current times the battery voltage";
CM_ SG_ 1509 Overvoltage_protection_counter "Number of times that different protections have been triggered, in this case, overvoltage";
CM_ SG_ 1509 Total_charged_capacity "Integral of the BMU measured charge current along time";
CM_ SG_ 1509 Fully_discharged_counter "Number of times where the battery has been fully discharged (BMU has entered to DISCHARGED state)";
CM_ SG_ 1509 Overcurrent_protection_counter "Number of times that different protections have been triggered, in this case, overcurrent.";
CM_ SG_ 1509 Total_discharged_capacity "Integral of the BMU measured discharge current along time.";
CM_ SG_ 1509 Overtemperature_protection_count "Number of times that different protections have been triggered, in this case, over temperature.";
CM_ SG_ 1509 Undertemperature_protection_coun "Number of times that different protections have been triggered, in this case, undertemperature.";
CM_ SG_ 1509 Undervoltage_protection_counter "Number of times that different protections have been triggered, in this case, undervoltage.";
CM_ SG_ 1510 Remaining_capacity "Remaining capacity in Ah of the BMU";
CM_ SG_ 1510 Contactors_opened_under_load_cnt "Times that power relays have opened while current �Maximum switching current� is exceeded";
CM_ SG_ 1510 Equivalent_cycles "Total charged capacity divided by the nominal capacity (resolution of 1 cycle)";
CM_ SG_ 1510 Cycles_since_fully_charged "Number of equivalent cycles since last fully charged (BMU has entered to CHARGED state)";
CM_ SG_ 1510 Fully_charged_counter "Number of times where the battery has been fully charged (BMU has entered to CHARGED state)";
CM_ SG_ 1510 Total_charged_energy "Integral of the BMU measured charge energy along time. Being energy, the measured current times the battery voltage";
CM_ SG_ 1510 Total_discharged_energy "Integral of the BMU measured discharge energy along time. Being energy, the measured current times the battery voltage";
CM_ SG_ 1510 Overvoltage_protection_counter "Number of times that different protections have been triggered, in this case, overvoltage";
CM_ SG_ 1510 Total_charged_capacity "Integral of the BMU measured charge current along time";
CM_ SG_ 1510 Fully_discharged_counter "Number of times where the battery has been fully discharged (BMU has entered to DISCHARGED state)";
CM_ SG_ 1510 Overcurrent_protection_counter "Number of times that different protections have been triggered, in this case, overcurrent.";
CM_ SG_ 1510 Total_discharged_capacity "Integral of the BMU measured discharge current along time.";
CM_ SG_ 1510 Overtemperature_protection_count "Number of times that different protections have been triggered, in this case, over temperature.";
CM_ SG_ 1510 Undertemperature_protection_coun "Number of times that different protections have been triggered, in this case, undertemperature.";
CM_ SG_ 1510 Undervoltage_protection_counter "Number of times that different protections have been triggered, in this case, undervoltage.";
CM_ SG_ 1511 Remaining_capacity "Remaining capacity in Ah of the BMU";
CM_ SG_ 1511 Contactors_opened_under_load_cnt "Times that power relays have opened while current �Maximum switching current� is exceeded";
CM_ SG_ 1511 Equivalent_cycles "Total charged capacity divided by the nominal capacity (resolution of 1 cycle)";
CM_ SG_ 1511 Cycles_since_fully_charged "Number of equivalent cycles since last fully charged (BMU has entered to CHARGED state)";
CM_ SG_ 1511 Fully_charged_counter "Number of times where the battery has been fully charged (BMU has entered to CHARGED state)";
CM_ SG_ 1511 Total_charged_energy "Integral of the BMU measured charge energy along time. Being energy, the measured current times the battery voltage";
CM_ SG_ 1511 Total_discharged_energy "Integral of the BMU measured discharge energy along time. Being energy, the measured current times the battery voltage";
CM_ SG_ 1511 Overvoltage_protection_counter "Number of times that different protections have been triggered, in this case, overvoltage";
CM_ SG_ 1511 Total_charged_capacity "Integral of the BMU measured charge current along time";
CM_ SG_ 1511 Fully_discharged_counter "Number of times where the battery has been fully discharged (BMU has entered to DISCHARGED state)";
CM_ SG_ 1511 Overcurrent_protection_counter "Number of times that different protections have been triggered, in this case, overcurrent.";
CM_ SG_ 1511 Total_discharged_capacity "Integral of the BMU measured discharge current along time.";
CM_ SG_ 1511 Overtemperature_protection_count "Number of times that different protections have been triggered, in this case, over temperature.";
CM_ SG_ 1511 Undertemperature_protection_coun "Number of times that different protections have been triggered, in this case, undertemperature.";
CM_ SG_ 1511 Undervoltage_protection_counter "Number of times that different protections have been triggered, in this case, undervoltage.";
CM_ SG_ 1512 Remaining_capacity "Remaining capacity in Ah of the BMU";
CM_ SG_ 1512 Contactors_opened_under_load_cnt "Times that power relays have opened while current �Maximum switching current� is exceeded";
CM_ SG_ 1512 Equivalent_cycles "Total charged capacity divided by the nominal capacity (resolution of 1 cycle)";
CM_ SG_ 1512 Cycles_since_fully_charged "Number of equivalent cycles since last fully charged (BMU has entered to CHARGED state)";
CM_ SG_ 1512 Fully_charged_counter "Number of times where the battery has been fully charged (BMU has entered to CHARGED state)";
CM_ SG_ 1512 Total_charged_energy "Integral of the BMU measured charge energy along time. Being energy, the measured current times the battery voltage";
CM_ SG_ 1512 Total_discharged_energy "Integral of the BMU measured discharge energy along time. Being energy, the measured current times the battery voltage";
CM_ SG_ 1512 Overvoltage_protection_counter "Number of times that different protections have been triggered, in this case, overvoltage";
CM_ SG_ 1512 Total_charged_capacity "Integral of the BMU measured charge current along time";
CM_ SG_ 1512 Fully_discharged_counter "Number of times where the battery has been fully discharged (BMU has entered to DISCHARGED state)";
CM_ SG_ 1512 Overcurrent_protection_counter "Number of times that different protections have been triggered, in this case, overcurrent.";
CM_ SG_ 1512 Total_discharged_capacity "Integral of the BMU measured discharge current along time.";
CM_ SG_ 1512 Overtemperature_protection_count "Number of times that different protections have been triggered, in this case, over temperature.";
CM_ SG_ 1512 Undertemperature_protection_coun "Number of times that different protections have been triggered, in this case, undertemperature.";
CM_ SG_ 1512 Undervoltage_protection_counter "Number of times that different protections have been triggered, in this case, undervoltage.";
CM_ SG_ 1513 Remaining_capacity "Remaining capacity in Ah of the BMU";
CM_ SG_ 1513 Contactors_opened_under_load_cnt "Times that power relays have opened while current �Maximum switching current� is exceeded";
CM_ SG_ 1513 Equivalent_cycles "Total charged capacity divided by the nominal capacity (resolution of 1 cycle)";
CM_ SG_ 1513 Cycles_since_fully_charged "Number of equivalent cycles since last fully charged (BMU has entered to CHARGED state)";
CM_ SG_ 1513 Fully_charged_counter "Number of times where the battery has been fully charged (BMU has entered to CHARGED state)";
CM_ SG_ 1513 Total_charged_energy "Integral of the BMU measured charge energy along time. Being energy, the measured current times the battery voltage";
CM_ SG_ 1513 Total_discharged_energy "Integral of the BMU measured discharge energy along time. Being energy, the measured current times the battery voltage";
CM_ SG_ 1513 Overvoltage_protection_counter "Number of times that different protections have been triggered, in this case, overvoltage";
CM_ SG_ 1513 Total_charged_capacity "Integral of the BMU measured charge current along time";
CM_ SG_ 1513 Fully_discharged_counter "Number of times where the battery has been fully discharged (BMU has entered to DISCHARGED state)";
CM_ SG_ 1513 Overcurrent_protection_counter "Number of times that different protections have been triggered, in this case, overcurrent.";
CM_ SG_ 1513 Total_discharged_capacity "Integral of the BMU measured discharge current along time.";
CM_ SG_ 1513 Overtemperature_protection_count "Number of times that different protections have been triggered, in this case, over temperature.";
CM_ SG_ 1513 Undertemperature_protection_coun "Number of times that different protections have been triggered, in this case, undertemperature.";
CM_ SG_ 1513 Undervoltage_protection_counter "Number of times that different protections have been triggered, in this case, undervoltage.";
CM_ SG_ 1514 Remaining_capacity "Remaining capacity in Ah of the BMU";
CM_ SG_ 1514 Contactors_opened_under_load_cnt "Times that power relays have opened while current �Maximum switching current� is exceeded";
CM_ SG_ 1514 Equivalent_cycles "Total charged capacity divided by the nominal capacity (resolution of 1 cycle)";
CM_ SG_ 1514 Cycles_since_fully_charged "Number of equivalent cycles since last fully charged (BMU has entered to CHARGED state)";
CM_ SG_ 1514 Fully_charged_counter "Number of times where the battery has been fully charged (BMU has entered to CHARGED state)";
CM_ SG_ 1514 Total_charged_energy "Integral of the BMU measured charge energy along time. Being energy, the measured current times the battery voltage";
CM_ SG_ 1514 Total_discharged_energy "Integral of the BMU measured discharge energy along time. Being energy, the measured current times the battery voltage";
CM_ SG_ 1514 Overvoltage_protection_counter "Number of times that different protections have been triggered, in this case, overvoltage";
CM_ SG_ 1514 Total_charged_capacity "Integral of the BMU measured charge current along time";
CM_ SG_ 1514 Fully_discharged_counter "Number of times where the battery has been fully discharged (BMU has entered to DISCHARGED state)";
CM_ SG_ 1514 Overcurrent_protection_counter "Number of times that different protections have been triggered, in this case, overcurrent.";
CM_ SG_ 1514 Total_discharged_capacity "Integral of the BMU measured discharge current along time.";
CM_ SG_ 1514 Overtemperature_protection_count "Number of times that different protections have been triggered, in this case, over temperature.";
CM_ SG_ 1514 Undertemperature_protection_coun "Number of times that different protections have been triggered, in this case, undertemperature.";
CM_ SG_ 1514 Undervoltage_protection_counter "Number of times that different protections have been triggered, in this case, undervoltage.";
CM_ SG_ 1515 Remaining_capacity "Remaining capacity in Ah of the BMU";
CM_ SG_ 1515 Contactors_opened_under_load_cnt "Times that power relays have opened while current �Maximum switching current� is exceeded";
CM_ SG_ 1515 Equivalent_cycles "Total charged capacity divided by the nominal capacity (resolution of 1 cycle)";
CM_ SG_ 1515 Cycles_since_fully_charged "Number of equivalent cycles since last fully charged (BMU has entered to CHARGED state)";
CM_ SG_ 1515 Fully_charged_counter "Number of times where the battery has been fully charged (BMU has entered to CHARGED state)";
CM_ SG_ 1515 Total_charged_energy "Integral of the BMU measured charge energy along time. Being energy, the measured current times the battery voltage";
CM_ SG_ 1515 Total_discharged_energy "Integral of the BMU measured discharge energy along time. Being energy, the measured current times the battery voltage";
CM_ SG_ 1515 Overvoltage_protection_counter "Number of times that different protections have been triggered, in this case, overvoltage";
CM_ SG_ 1515 Total_charged_capacity "Integral of the BMU measured charge current along time";
CM_ SG_ 1515 Fully_discharged_counter "Number of times where the battery has been fully discharged (BMU has entered to DISCHARGED state)";
CM_ SG_ 1515 Overcurrent_protection_counter "Number of times that different protections have been triggered, in this case, overcurrent.";
CM_ SG_ 1515 Total_discharged_capacity "Integral of the BMU measured discharge current along time.";
CM_ SG_ 1515 Overtemperature_protection_count "Number of times that different protections have been triggered, in this case, over temperature.";
CM_ SG_ 1515 Undertemperature_protection_coun "Number of times that different protections have been triggered, in this case, undertemperature.";
CM_ SG_ 1515 Undervoltage_protection_counter "Number of times that different protections have been triggered, in this case, undervoltage.";
CM_ SG_ 1516 Remaining_capacity "Remaining capacity in Ah of the BMU";
CM_ SG_ 1516 Contactors_opened_under_load_cnt "Times that power relays have opened while current �Maximum switching current� is exceeded";
CM_ SG_ 1516 Equivalent_cycles "Total charged capacity divided by the nominal capacity (resolution of 1 cycle)";
CM_ SG_ 1516 Cycles_since_fully_charged "Number of equivalent cycles since last fully charged (BMU has entered to CHARGED state)";
CM_ SG_ 1516 Fully_charged_counter "Number of times where the battery has been fully charged (BMU has entered to CHARGED state)";
CM_ SG_ 1516 Total_charged_energy "Integral of the BMU measured charge energy along time. Being energy, the measured current times the battery voltage";
CM_ SG_ 1516 Total_discharged_energy "Integral of the BMU measured discharge energy along time. Being energy, the measured current times the battery voltage";
CM_ SG_ 1516 Overvoltage_protection_counter "Number of times that different protections have been triggered, in this case, overvoltage";
CM_ SG_ 1516 Total_charged_capacity "Integral of the BMU measured charge current along time";
CM_ SG_ 1516 Fully_discharged_counter "Number of times where the battery has been fully discharged (BMU has entered to DISCHARGED state)";
CM_ SG_ 1516 Overcurrent_protection_counter "Number of times that different protections have been triggered, in this case, overcurrent.";
CM_ SG_ 1516 Total_discharged_capacity "Integral of the BMU measured discharge current along time.";
CM_ SG_ 1516 Overtemperature_protection_count "Number of times that different protections have been triggered, in this case, over temperature.";
CM_ SG_ 1516 Undertemperature_protection_coun "Number of times that different protections have been triggered, in this case, undertemperature.";
CM_ SG_ 1516 Undervoltage_protection_counter "Number of times that different protections have been triggered, in this case, undervoltage.";
CM_ SG_ 1517 Remaining_capacity "Remaining capacity in Ah of the BMU";
CM_ SG_ 1517 Contactors_opened_under_load_cnt "Times that power relays have opened while current �Maximum switching current� is exceeded";
CM_ SG_ 1517 Equivalent_cycles "Total charged capacity divided by the nominal capacity (resolution of 1 cycle)";
CM_ SG_ 1517 Cycles_since_fully_charged "Number of equivalent cycles since last fully charged (BMU has entered to CHARGED state)";
CM_ SG_ 1517 Fully_charged_counter "Number of times where the battery has been fully charged (BMU has entered to CHARGED state)";
CM_ SG_ 1517 Total_charged_energy "Integral of the BMU measured charge energy along time. Being energy, the measured current times the battery voltage";
CM_ SG_ 1517 Total_discharged_energy "Integral of the BMU measured discharge energy along time. Being energy, the measured current times the battery voltage";
CM_ SG_ 1517 Overvoltage_protection_counter "Number of times that different protections have been triggered, in this case, overvoltage";
CM_ SG_ 1517 Total_charged_capacity "Integral of the BMU measured charge current along time";
CM_ SG_ 1517 Fully_discharged_counter "Number of times where the battery has been fully discharged (BMU has entered to DISCHARGED state)";
CM_ SG_ 1517 Overcurrent_protection_counter "Number of times that different protections have been triggered, in this case, overcurrent.";
CM_ SG_ 1517 Total_discharged_capacity "Integral of the BMU measured discharge current along time.";
CM_ SG_ 1517 Overtemperature_protection_count "Number of times that different protections have been triggered, in this case, over temperature.";
CM_ SG_ 1517 Undertemperature_protection_coun "Number of times that different protections have been triggered, in this case, undertemperature.";
CM_ SG_ 1517 Undervoltage_protection_counter "Number of times that different protections have been triggered, in this case, undervoltage.";
CM_ SG_ 1518 Remaining_capacity "Remaining capacity in Ah of the BMU";
CM_ SG_ 1518 Contactors_opened_under_load_cnt "Times that power relays have opened while current �Maximum switching current� is exceeded";
CM_ SG_ 1518 Equivalent_cycles "Total charged capacity divided by the nominal capacity (resolution of 1 cycle)";
CM_ SG_ 1518 Cycles_since_fully_charged "Number of equivalent cycles since last fully charged (BMU has entered to CHARGED state)";
CM_ SG_ 1518 Fully_charged_counter "Number of times where the battery has been fully charged (BMU has entered to CHARGED state)";
CM_ SG_ 1518 Total_charged_energy "Integral of the BMU measured charge energy along time. Being energy, the measured current times the battery voltage";
CM_ SG_ 1518 Total_discharged_energy "Integral of the BMU measured discharge energy along time. Being energy, the measured current times the battery voltage";
CM_ SG_ 1518 Overvoltage_protection_counter "Number of times that different protections have been triggered, in this case, overvoltage";
CM_ SG_ 1518 Total_charged_capacity "Integral of the BMU measured charge current along time";
CM_ SG_ 1518 Fully_discharged_counter "Number of times where the battery has been fully discharged (BMU has entered to DISCHARGED state)";
CM_ SG_ 1518 Overcurrent_protection_counter "Number of times that different protections have been triggered, in this case, overcurrent.";
CM_ SG_ 1518 Total_discharged_capacity "Integral of the BMU measured discharge current along time.";
CM_ SG_ 1518 Overtemperature_protection_count "Number of times that different protections have been triggered, in this case, over temperature.";
CM_ SG_ 1518 Undertemperature_protection_coun "Number of times that different protections have been triggered, in this case, undertemperature.";
CM_ SG_ 1518 Undervoltage_protection_counter "Number of times that different protections have been triggered, in this case, undervoltage.";
CM_ SG_ 1519 Remaining_capacity "Remaining capacity in Ah of the BMU";
CM_ SG_ 1519 Contactors_opened_under_load_cnt "Times that power relays have opened while current �Maximum switching current� is exceeded";
CM_ SG_ 1519 Equivalent_cycles "Total charged capacity divided by the nominal capacity (resolution of 1 cycle)";
CM_ SG_ 1519 Cycles_since_fully_charged "Number of equivalent cycles since last fully charged (BMU has entered to CHARGED state)";
CM_ SG_ 1519 Fully_charged_counter "Number of times where the battery has been fully charged (BMU has entered to CHARGED state)";
CM_ SG_ 1519 Total_charged_energy "Integral of the BMU measured charge energy along time. Being energy, the measured current times the battery voltage";
CM_ SG_ 1519 Total_discharged_energy "Integral of the BMU measured discharge energy along time. Being energy, the measured current times the battery voltage";
CM_ SG_ 1519 Overvoltage_protection_counter "Number of times that different protections have been triggered, in this case, overvoltage";
CM_ SG_ 1519 Total_charged_capacity "Integral of the BMU measured charge current along time";
CM_ SG_ 1519 Fully_discharged_counter "Number of times where the battery has been fully discharged (BMU has entered to DISCHARGED state)";
CM_ SG_ 1519 Overcurrent_protection_counter "Number of times that different protections have been triggered, in this case, overcurrent.";
CM_ SG_ 1519 Total_discharged_capacity "Integral of the BMU measured discharge current along time.";
CM_ SG_ 1519 Overtemperature_protection_count "Number of times that different protections have been triggered, in this case, over temperature.";
CM_ SG_ 1519 Undertemperature_protection_coun "Number of times that different protections have been triggered, in this case, undertemperature.";
CM_ SG_ 1519 Undervoltage_protection_counter "Number of times that different protections have been triggered, in this case, undervoltage.";
CM_ SG_ 1520 Configuration_CRC "Configuration CRC";
CM_ SG_ 1520 String_capacity "String capacity configured on BMU Settings -> SoA";
CM_ SG_ 1520 Number_of_CMU_link_devices_found "Number of CMUs and wBMS-VIC devices found during initialization";
CM_ SG_ 1520 Device_ID "Identifier of the BMU";
CM_ SG_ 1520 Software_version_major "BMU software version X.Y.Z (major (X), minor (Y) and patch (Z))";
CM_ SG_ 1520 Software_version_minor "BMU software version X.Y.Z (major (X), minor (Y) and patch (Z))";
CM_ SG_ 1520 Software_version_patch "BMU software version X.Y.Z (major (X), minor (Y) and patch (Z))";
CM_ SG_ 1520 Bootloader_version_major "Bootloader software version X.Y (major (X) and minor (Y))";
CM_ SG_ 1520 Bootloader_version_minor "Bootloader software version X.Y (major (X) and minor (Y))";
CM_ SG_ 1520 Hardware_version_major "Hardware software version X.Y (major (x) and minor (Y))";
CM_ SG_ 1520 Hardware_version_minor "Hardware software version X.Y (major (x) and minor (Y))";
CM_ SG_ 1520 Precharge_configured_time "Configured precharge time on BMU Settings Power Relays";
CM_ SG_ 1521 Configuration_CRC "Configuration CRC";
CM_ SG_ 1521 String_capacity "String capacity configured on BMU Settings -> SoA";
CM_ SG_ 1521 Number_of_CMU_link_devices_found "Number of CMUs and wBMS-VIC devices found during initialization";
CM_ SG_ 1521 Device_ID "Identifier of the BMU";
CM_ SG_ 1521 Software_version_major "BMU software version X.Y.Z (major (X), minor (Y) and patch (Z))";
CM_ SG_ 1521 Software_version_minor "BMU software version X.Y.Z (major (X), minor (Y) and patch (Z))";
CM_ SG_ 1521 Software_version_patch "BMU software version X.Y.Z (major (X), minor (Y) and patch (Z))";
CM_ SG_ 1521 Bootloader_version_major "Bootloader software version X.Y (major (X) and minor (Y))";
CM_ SG_ 1521 Bootloader_version_minor "Bootloader software version X.Y (major (X) and minor (Y))";
CM_ SG_ 1521 Hardware_version_major "Hardware software version X.Y (major (x) and minor (Y))";
CM_ SG_ 1521 Hardware_version_minor "Hardware software version X.Y (major (x) and minor (Y))";
CM_ SG_ 1521 Precharge_configured_time "Configured precharge time on BMU Settings Power Relays";
CM_ SG_ 1522 Configuration_CRC "Configuration CRC";
CM_ SG_ 1522 String_capacity "String capacity configured on BMU Settings -> SoA";
CM_ SG_ 1522 Number_of_CMU_link_devices_found "Number of CMUs and wBMS-VIC devices found during initialization";
CM_ SG_ 1522 Device_ID "Identifier of the BMU";
CM_ SG_ 1522 Software_version_major "BMU software version X.Y.Z (major (X), minor (Y) and patch (Z))";
CM_ SG_ 1522 Software_version_minor "BMU software version X.Y.Z (major (X), minor (Y) and patch (Z))";
CM_ SG_ 1522 Software_version_patch "BMU software version X.Y.Z (major (X), minor (Y) and patch (Z))";
CM_ SG_ 1522 Bootloader_version_major "Bootloader software version X.Y (major (X) and minor (Y))";
CM_ SG_ 1522 Bootloader_version_minor "Bootloader software version X.Y (major (X) and minor (Y))";
CM_ SG_ 1522 Hardware_version_major "Hardware software version X.Y (major (x) and minor (Y))";
CM_ SG_ 1522 Hardware_version_minor "Hardware software version X.Y (major (x) and minor (Y))";
CM_ SG_ 1522 Precharge_configured_time "Configured precharge time on BMU Settings Power Relays";
CM_ SG_ 1523 Configuration_CRC "Configuration CRC";
CM_ SG_ 1523 String_capacity "String capacity configured on BMU Settings -> SoA";
CM_ SG_ 1523 Number_of_CMU_link_devices_found "Number of CMUs and wBMS-VIC devices found during initialization";
CM_ SG_ 1523 Device_ID "Identifier of the BMU";
CM_ SG_ 1523 Software_version_major "BMU software version X.Y.Z (major (X), minor (Y) and patch (Z))";
CM_ SG_ 1523 Software_version_minor "BMU software version X.Y.Z (major (X), minor (Y) and patch (Z))";
CM_ SG_ 1523 Software_version_patch "BMU software version X.Y.Z (major (X), minor (Y) and patch (Z))";
CM_ SG_ 1523 Bootloader_version_major "Bootloader software version X.Y (major (X) and minor (Y))";
CM_ SG_ 1523 Bootloader_version_minor "Bootloader software version X.Y (major (X) and minor (Y))";
CM_ SG_ 1523 Hardware_version_major "Hardware software version X.Y (major (x) and minor (Y))";
CM_ SG_ 1523 Hardware_version_minor "Hardware software version X.Y (major (x) and minor (Y))";
CM_ SG_ 1523 Precharge_configured_time "Configured precharge time on BMU Settings Power Relays";
CM_ SG_ 1524 Configuration_CRC "Configuration CRC";
CM_ SG_ 1524 String_capacity "String capacity configured on BMU Settings -> SoA";
CM_ SG_ 1524 Number_of_CMU_link_devices_found "Number of CMUs and wBMS-VIC devices found during initialization";
CM_ SG_ 1524 BMU_ID "Identifier of the BMU";
CM_ SG_ 1524 Software_version_major "BMU software version X.Y.Z (major (X), minor (Y) and patch (Z))";
CM_ SG_ 1524 Software_version_minor "BMU software version X.Y.Z (major (X), minor (Y) and patch (Z))";
CM_ SG_ 1524 Software_version_patch "BMU software version X.Y.Z (major (X), minor (Y) and patch (Z))";
CM_ SG_ 1524 Bootloader_version_major "Bootloader software version X.Y (major (X) and minor (Y))";
CM_ SG_ 1524 Bootloader_version_minor "Bootloader software version X.Y (major (X) and minor (Y))";
CM_ SG_ 1524 Hardware_version_major "Hardware software version X.Y (major (x) and minor (Y))";
CM_ SG_ 1524 Hardware_version_minor "Hardware software version X.Y (major (x) and minor (Y))";
CM_ SG_ 1524 Precharge_configured_time "Configured precharge time on BMU Settings Power Relays";
CM_ SG_ 1525 Configuration_CRC "Configuration CRC";
CM_ SG_ 1525 String_capacity "String capacity configured on BMU Settings -> SoA";
CM_ SG_ 1525 Number_of_CMU_link_devices_found "Number of CMUs and wBMS-VIC devices found during initialization";
CM_ SG_ 1525 Device_ID "Identifier of the BMU";
CM_ SG_ 1525 Software_version_major "BMU software version X.Y.Z (major (X), minor (Y) and patch (Z))";
CM_ SG_ 1525 Software_version_minor "BMU software version X.Y.Z (major (X), minor (Y) and patch (Z))";
CM_ SG_ 1525 Software_version_patch "BMU software version X.Y.Z (major (X), minor (Y) and patch (Z))";
CM_ SG_ 1525 Bootloader_version_major "Bootloader software version X.Y (major (X) and minor (Y))";
CM_ SG_ 1525 Bootloader_version_minor "Bootloader software version X.Y (major (X) and minor (Y))";
CM_ SG_ 1525 Hardware_version_major "Hardware software version X.Y (major (x) and minor (Y))";
CM_ SG_ 1525 Hardware_version_minor "Hardware software version X.Y (major (x) and minor (Y))";
CM_ SG_ 1525 Precharge_configured_time "Configured precharge time on BMU Settings Power Relays";
CM_ SG_ 1526 Configuration_CRC "Configuration CRC";
CM_ SG_ 1526 String_capacity "String capacity configured on BMU Settings -> SoA";
CM_ SG_ 1526 Number_of_CMU_link_devices_found "Number of CMUs and wBMS-VIC devices found during initialization";
CM_ SG_ 1526 Device_ID "Identifier of the BMU";
CM_ SG_ 1526 Software_version_major "BMU software version X.Y.Z (major (X), minor (Y) and patch (Z))";
CM_ SG_ 1526 Software_version_minor "BMU software version X.Y.Z (major (X), minor (Y) and patch (Z))";
CM_ SG_ 1526 Software_version_patch "BMU software version X.Y.Z (major (X), minor (Y) and patch (Z))";
CM_ SG_ 1526 Bootloader_version_major "Bootloader software version X.Y (major (X) and minor (Y))";
CM_ SG_ 1526 Bootloader_version_minor "Bootloader software version X.Y (major (X) and minor (Y))";
CM_ SG_ 1526 Hardware_version_major "Hardware software version X.Y (major (x) and minor (Y))";
CM_ SG_ 1526 Hardware_version_minor "Hardware software version X.Y (major (x) and minor (Y))";
CM_ SG_ 1526 Precharge_configured_time "Configured precharge time on BMU Settings Power Relays";
CM_ SG_ 1527 Configuration_CRC "Configuration CRC";
CM_ SG_ 1527 String_capacity "String capacity configured on BMU Settings -> SoA";
CM_ SG_ 1527 Number_of_CMU_link_devices_found "Number of CMUs and wBMS-VIC devices found during initialization";
CM_ SG_ 1527 Device_ID "Identifier of the BMU";
CM_ SG_ 1527 Software_version_major "BMU software version X.Y.Z (major (X), minor (Y) and patch (Z))";
CM_ SG_ 1527 Software_version_minor "BMU software version X.Y.Z (major (X), minor (Y) and patch (Z))";
CM_ SG_ 1527 Software_version_patch "BMU software version X.Y.Z (major (X), minor (Y) and patch (Z))";
CM_ SG_ 1527 Bootloader_version_major "Bootloader software version X.Y (major (X) and minor (Y))";
CM_ SG_ 1527 Bootloader_version_minor "Bootloader software version X.Y (major (X) and minor (Y))";
CM_ SG_ 1527 Hardware_version_major "Hardware software version X.Y (major (x) and minor (Y))";
CM_ SG_ 1527 Hardware_version_minor "Hardware software version X.Y (major (x) and minor (Y))";
CM_ SG_ 1527 Precharge_configured_time "Configured precharge time on BMU Settings Power Relays";
CM_ SG_ 1528 Configuration_CRC "Configuration CRC";
CM_ SG_ 1528 String_capacity "String capacity configured on BMU Settings -> SoA";
CM_ SG_ 1528 Number_of_CMU_link_devices_found "Number of CMUs and wBMS-VIC devices found during initialization";
CM_ SG_ 1528 Device_ID "Identifier of the BMU";
CM_ SG_ 1528 Software_version_major "BMU software version X.Y.Z (major (X), minor (Y) and patch (Z))";
CM_ SG_ 1528 Software_version_minor "BMU software version X.Y.Z (major (X), minor (Y) and patch (Z))";
CM_ SG_ 1528 Software_version_patch "BMU software version X.Y.Z (major (X), minor (Y) and patch (Z))";
CM_ SG_ 1528 Bootloader_version_major "Bootloader software version X.Y (major (X) and minor (Y))";
CM_ SG_ 1528 Bootloader_version_minor "Bootloader software version X.Y (major (X) and minor (Y))";
CM_ SG_ 1528 Hardware_version_major "Hardware software version X.Y (major (x) and minor (Y))";
CM_ SG_ 1528 Hardware_version_minor "Hardware software version X.Y (major (x) and minor (Y))";
CM_ SG_ 1528 Precharge_configured_time "Configured precharge time on BMU Settings Power Relays";
CM_ SG_ 1529 Configuration_CRC "Configuration CRC";
CM_ SG_ 1529 String_capacity "String capacity configured on BMU Settings -> SoA";
CM_ SG_ 1529 Number_of_CMU_link_devices_found "Number of CMUs and wBMS-VIC devices found during initialization";
CM_ SG_ 1529 Device_ID "Identifier of the BMU";
CM_ SG_ 1529 Software_version_major "BMU software version X.Y.Z (major (X), minor (Y) and patch (Z))";
CM_ SG_ 1529 Software_version_minor "BMU software version X.Y.Z (major (X), minor (Y) and patch (Z))";
CM_ SG_ 1529 Software_version_patch "BMU software version X.Y.Z (major (X), minor (Y) and patch (Z))";
CM_ SG_ 1529 Bootloader_version_major "Bootloader software version X.Y (major (X) and minor (Y))";
CM_ SG_ 1529 Bootloader_version_minor "Bootloader software version X.Y (major (X) and minor (Y))";
CM_ SG_ 1529 Hardware_version_major "Hardware software version X.Y (major (x) and minor (Y))";
CM_ SG_ 1529 Hardware_version_minor "Hardware software version X.Y (major (x) and minor (Y))";
CM_ SG_ 1529 Precharge_configured_time "Configured precharge time on BMU Settings Power Relays";
CM_ SG_ 1530 Configuration_CRC "Configuration CRC";
CM_ SG_ 1530 String_capacity "String capacity configured on BMU Settings -> SoA";
CM_ SG_ 1530 Number_of_CMU_link_devices_found "Number of CMUs and wBMS-VIC devices found during initialization";
CM_ SG_ 1530 Device_ID "Identifier of the BMU";
CM_ SG_ 1530 Software_version_major "BMU software version X.Y.Z (major (X), minor (Y) and patch (Z))";
CM_ SG_ 1530 Software_version_minor "BMU software version X.Y.Z (major (X), minor (Y) and patch (Z))";
CM_ SG_ 1530 Software_version_patch "BMU software version X.Y.Z (major (X), minor (Y) and patch (Z))";
CM_ SG_ 1530 Bootloader_version_major "Bootloader software version X.Y (major (X) and minor (Y))";
CM_ SG_ 1530 Bootloader_version_minor "Bootloader software version X.Y (major (X) and minor (Y))";
CM_ SG_ 1530 Hardware_version_major "Hardware software version X.Y (major (x) and minor (Y))";
CM_ SG_ 1530 Hardware_version_minor "Hardware software version X.Y (major (x) and minor (Y))";
CM_ SG_ 1530 Precharge_configured_time "Configured precharge time on BMU Settings Power Relays";
CM_ SG_ 1531 Configuration_CRC "Configuration CRC";
CM_ SG_ 1531 String_capacity "String capacity configured on BMU Settings -> SoA";
CM_ SG_ 1531 Number_of_CMU_link_devices_found "Number of CMUs and wBMS-VIC devices found during initialization";
CM_ SG_ 1531 Device_ID "Identifier of the BMU";
CM_ SG_ 1531 Software_version_major "BMU software version X.Y.Z (major (X), minor (Y) and patch (Z))";
CM_ SG_ 1531 Software_version_minor "BMU software version X.Y.Z (major (X), minor (Y) and patch (Z))";
CM_ SG_ 1531 Software_version_patch "BMU software version X.Y.Z (major (X), minor (Y) and patch (Z))";
CM_ SG_ 1531 Bootloader_version_major "Bootloader software version X.Y (major (X) and minor (Y))";
CM_ SG_ 1531 Bootloader_version_minor "Bootloader software version X.Y (major (X) and minor (Y))";
CM_ SG_ 1531 Hardware_version_major "Hardware software version X.Y (major (x) and minor (Y))";
CM_ SG_ 1531 Hardware_version_minor "Hardware software version X.Y (major (x) and minor (Y))";
CM_ SG_ 1531 Precharge_configured_time "Configured precharge time on BMU Settings Power Relays";
CM_ SG_ 1532 Configuration_CRC "Configuration CRC";
CM_ SG_ 1532 String_capacity "String capacity configured on BMU Settings -> SoA";
CM_ SG_ 1532 Number_of_CMU_link_devices_found "Number of CMUs and wBMS-VIC devices found during initialization";
CM_ SG_ 1532 Device_ID "Identifier of the BMU";
CM_ SG_ 1532 Software_version_major "BMU software version X.Y.Z (major (X), minor (Y) and patch (Z))";
CM_ SG_ 1532 Software_version_minor "BMU software version X.Y.Z (major (X), minor (Y) and patch (Z))";
CM_ SG_ 1532 Software_version_patch "BMU software version X.Y.Z (major (X), minor (Y) and patch (Z))";
CM_ SG_ 1532 Bootloader_version_major "Bootloader software version X.Y (major (X) and minor (Y))";
CM_ SG_ 1532 Bootloader_version_minor "Bootloader software version X.Y (major (X) and minor (Y))";
CM_ SG_ 1532 Hardware_version_major "Hardware software version X.Y (major (x) and minor (Y))";
CM_ SG_ 1532 Hardware_version_minor "Hardware software version X.Y (major (x) and minor (Y))";
CM_ SG_ 1532 Precharge_configured_time "Configured precharge time on BMU Settings Power Relays";
CM_ SG_ 1533 Configuration_CRC "Configuration CRC";
CM_ SG_ 1533 String_capacity "String capacity configured on BMU Settings -> SoA";
CM_ SG_ 1533 Number_of_CMU_link_devices_found "Number of CMUs and wBMS-VIC devices found during initialization";
CM_ SG_ 1533 Device_ID "Identifier of the BMU";
CM_ SG_ 1533 Software_version_major "BMU software version X.Y.Z (major (X), minor (Y) and patch (Z))";
CM_ SG_ 1533 Software_version_minor "BMU software version X.Y.Z (major (X), minor (Y) and patch (Z))";
CM_ SG_ 1533 Software_version_patch "BMU software version X.Y.Z (major (X), minor (Y) and patch (Z))";
CM_ SG_ 1533 Bootloader_version_major "Bootloader software version X.Y (major (X) and minor (Y))";
CM_ SG_ 1533 Bootloader_version_minor "Bootloader software version X.Y (major (X) and minor (Y))";
CM_ SG_ 1533 Hardware_version_major "Hardware software version X.Y (major (x) and minor (Y))";
CM_ SG_ 1533 Hardware_version_minor "Hardware software version X.Y (major (x) and minor (Y))";
CM_ SG_ 1533 Precharge_configured_time "Configured precharge time on BMU Settings Power Relays";
CM_ SG_ 1534 Configuration_CRC "Configuration CRC";
CM_ SG_ 1534 String_capacity "String capacity configured on BMU Settings -> SoA";
CM_ SG_ 1534 Number_of_CMU_link_devices_found "Number of CMUs and wBMS-VIC devices found during initialization";
CM_ SG_ 1534 Device_ID "Identifier of the BMU";
CM_ SG_ 1534 Software_version_major "BMU software version X.Y.Z (major (X), minor (Y) and patch (Z))";
CM_ SG_ 1534 Software_version_minor "BMU software version X.Y.Z (major (X), minor (Y) and patch (Z))";
CM_ SG_ 1534 Software_version_patch "BMU software version X.Y.Z (major (X), minor (Y) and patch (Z))";
CM_ SG_ 1534 Bootloader_version_major "Bootloader software version X.Y (major (X) and minor (Y))";
CM_ SG_ 1534 Bootloader_version_minor "Bootloader software version X.Y (major (X) and minor (Y))";
CM_ SG_ 1534 Hardware_version_major "Hardware software version X.Y (major (x) and minor (Y))";
CM_ SG_ 1534 Hardware_version_minor "Hardware software version X.Y (major (x) and minor (Y))";
CM_ SG_ 1534 Precharge_configured_time "Configured precharge time on BMU Settings Power Relays";
CM_ SG_ 1535 Configuration_CRC "Configuration CRC";
CM_ SG_ 1535 String_capacity "String capacity configured on BMU Settings -> SoA";
CM_ SG_ 1535 Number_of_CMU_link_devices_found "Number of CMUs and wBMS-VIC devices found during initialization";
CM_ SG_ 1535 Device_ID "Identifier of the BMU";
CM_ SG_ 1535 Software_version_major "BMU software version X.Y.Z (major (X), minor (Y) and patch (Z))";
CM_ SG_ 1535 Software_version_minor "BMU software version X.Y.Z (major (X), minor (Y) and patch (Z))";
CM_ SG_ 1535 Software_version_patch "BMU software version X.Y.Z (major (X), minor (Y) and patch (Z))";
CM_ SG_ 1535 Bootloader_version_major "Bootloader software version X.Y (major (X) and minor (Y))";
CM_ SG_ 1535 Bootloader_version_minor "Bootloader software version X.Y (major (X) and minor (Y))";
CM_ SG_ 1535 Hardware_version_major "Hardware software version X.Y (major (x) and minor (Y))";
CM_ SG_ 1535 Hardware_version_minor "Hardware software version X.Y (major (x) and minor (Y))";
CM_ SG_ 1535 Precharge_configured_time "Configured precharge time on BMU Settings Power Relays";
VAL_ 1484 Cells_unbalanced_flag 0 "IDLE" 1 "ACTIVE" ;
VAL_ 1484 Cells_balancing_flag 0 "IDLE - NO CELLS ARE BALANCING" 1 "ACTIVE - AT LEAST ONE CELLS IS BALANCING" ;
VAL_ 1484 Null_current_flag 0 "IDLE" 1 "ACTIVE" ;
VAL_ 1484 Cells_relaxed_flag 0 "IDLE" 1 "ACTIVE" ;
VAL_ 1485 Cells_unbalanced_flag 0 "IDLE" 1 "ACTIVE" ;
VAL_ 1485 Cells_balancing_flag 0 "IDLE - NO CELLS ARE BALANCING" 1 "ACTIVE - AT LEAST ONE CELLS IS BALANCING" ;
VAL_ 1485 Null_current_flag 0 "IDLE" 1 "ACTIVE" ;
VAL_ 1485 Cells_relaxed_flag 0 "IDLE" 1 "ACTIVE" ;
VAL_ 1486 Cells_unbalanced_flag 0 "IDLE" 1 "ACTIVE" ;
VAL_ 1486 Cells_balancing_flag 0 "IDLE - NO CELLS ARE BALANCING" 1 "ACTIVE - AT LEAST ONE CELLS IS BALANCING" ;
VAL_ 1486 Null_current_flag 0 "IDLE" 1 "ACTIVE" ;
VAL_ 1486 Cells_relaxed_flag 0 "IDLE" 1 "ACTIVE" ;
VAL_ 1487 Cells_unbalanced_flag 0 "IDLE" 1 "ACTIVE" ;
VAL_ 1487 Cells_balancing_flag 0 "IDLE - NO CELLS ARE BALANCING" 1 "ACTIVE - AT LEAST ONE CELLS IS BALANCING" ;
VAL_ 1487 Null_current_flag 0 "IDLE" 1 "ACTIVE" ;
VAL_ 1487 Cells_relaxed_flag 0 "IDLE" 1 "ACTIVE" ;
VAL_ 1488 Positive_power_relay_status 0 "STATUS_OPEN" 1 "STATUS_CLOSED" ;
VAL_ 1488 Negative_power_relay_status 0 "STATUS_OPEN" 1 "STATUS_CLOSED" ;
VAL_ 1488 Precharge_power_relay_status 0 "STATUS_OPEN" 1 "STATUS_CLOSED" ;
VAL_ 1488 Middle_power_relay_status 0 "STATUS_OPEN" 1 "STATUS_CLOSED" ;
VAL_ 1488 Sleep_mode_request_flag 0 "STATUS_IDLE" 1 "STATUS_ACTIVE" ;
VAL_ 1488 Emergency_button_alarm_flag 0 "STATUS_IDLE" 1 "STATUS_ACTIVE" ;
VAL_ 1488 Start_signal_interlock_flag 0 "STATUS_IDLE" 1 "STATUS_ACTIVE" ;
VAL_ 1488 Start_signal_actuation_req_flag 0 "STATUS_IDLE" 1 "STATUS_ACTIVE" ;
VAL_ 1488 Heating_pad_request_flag 0 "IDLE" 1 "ACTIVE" ;
VAL_ 1488 Input_1_state 0 "IDLE" 1 "ACTIVE" ;
VAL_ 1488 Input_2_state 0 "IDLE" 1 "ACTIVE" ;
VAL_ 1488 Input_3_state 0 "IDLE" 1 "ACTIVE" ;
VAL_ 1488 Input_4_state 0 "IDLE" 1 "ACTIVE" ;
VAL_ 1488 Input_5_state 0 "IDLE" 1 "ACTIVE" ;
VAL_ 1488 Output_1_state 0 "IDLE" 1 "ACTIVE" ;
VAL_ 1488 Output_2_state 0 "IDLE" 1 "ACTIVE" ;
VAL_ 1488 Output_3_state 0 "IDLE" 1 "ACTIVE" ;
VAL_ 1488 Output_4_state 0 "IDLE" 1 "ACTIVE" ;
VAL_ 1488 Output_5_state 0 "IDLE" 1 "ACTIVE" ;
VAL_ 1488 Output_6_state 0 "IDLE" 1 "ACTIVE" ;
VAL_ 1488 Input_6_state 0 "IDLE" 1 "ACTIVE" ;
VAL_ 1488 Input_7_state 0 "IDLE" 1 "ACTIVE" ;
VAL_ 1488 Input_8_state 0 "IDLE" 1 "ACTIVE" ;
VAL_ 1488 Input_9_state 0 "IDLE" 1 "ACTIVE" ;
VAL_ 1488 Input_10_state 0 "IDLE" 1 "ACTIVE" ;
VAL_ 1488 Input_11_state 0 "IDLE" 1 "ACTIVE" ;
VAL_ 1488 Input_12_state 0 "IDLE" 1 "ACTIVE" ;
VAL_ 1488 Output_7_state 0 "IDLE" 1 "ACTIVE" ;
VAL_ 1488 Output_8_state 0 "IDLE" 1 "ACTIVE" ;
VAL_ 1488 Output_9_state 0 "IDLE" 1 "ACTIVE" ;
VAL_ 1488 Output_10_state 0 "IDLE" 1 "ACTIVE" ;
VAL_ 1488 Output_11_state 0 "IDLE" 1 "ACTIVE" ;
VAL_ 1488 Output_12_state 0 "IDLE" 1 "ACTIVE" ;
VAL_ 1488 Output_13_state 0 "IDLE" 1 "ACTIVE" ;
VAL_ 1489 Positive_power_relay_status 0 "STATUS_OPEN" 1 "STATUS_CLOSED" ;
VAL_ 1489 Negative_power_relay_status 0 "STATUS_OPEN" 1 "STATUS_CLOSED" ;
VAL_ 1489 Precharge_power_relay_status 0 "STATUS_OPEN" 1 "STATUS_CLOSED" ;
VAL_ 1489 Middle_power_relay_status 0 "STATUS_OPEN" 1 "STATUS_CLOSED" ;
VAL_ 1489 Sleep_mode_request_flag 0 "STATUS_IDLE" 1 "STATUS_ACTIVE" ;
VAL_ 1489 Emergency_button_alarm_flag 0 "STATUS_IDLE" 1 "STATUS_ACTIVE" ;
VAL_ 1489 Start_signal_interlock_flag 0 "STATUS_IDLE" 1 "STATUS_ACTIVE" ;
VAL_ 1489 Start_signal_actuation_req_flag 0 "STATUS_IDLE" 1 "STATUS_ACTIVE" ;
VAL_ 1489 Heating_pad_request_flag 0 "IDLE" 1 "ACTIVE" ;
VAL_ 1489 Input_1_state 0 "IDLE" 1 "ACTIVE" ;
VAL_ 1489 Input_2_state 0 "IDLE" 1 "ACTIVE" ;
VAL_ 1489 Input_3_state 0 "IDLE" 1 "ACTIVE" ;
VAL_ 1489 Input_4_state 0 "IDLE" 1 "ACTIVE" ;
VAL_ 1489 Input_5_state 0 "IDLE" 1 "ACTIVE" ;
VAL_ 1489 Output_1_state 0 "IDLE" 1 "ACTIVE" ;
VAL_ 1489 Output_2_state 0 "IDLE" 1 "ACTIVE" ;
VAL_ 1489 Output_3_state 0 "IDLE" 1 "ACTIVE" ;
VAL_ 1489 Output_4_state 0 "IDLE" 1 "ACTIVE" ;
VAL_ 1489 Output_5_state 0 "IDLE" 1 "ACTIVE" ;
VAL_ 1489 Output_6_state 0 "IDLE" 1 "ACTIVE" ;
VAL_ 1489 Input_6_state 0 "IDLE" 1 "ACTIVE" ;
VAL_ 1489 Input_7_state 0 "IDLE" 1 "ACTIVE" ;
VAL_ 1489 Input_8_state 0 "IDLE" 1 "ACTIVE" ;
VAL_ 1489 Input_9_state 0 "IDLE" 1 "ACTIVE" ;
VAL_ 1489 Input_10_state 0 "IDLE" 1 "ACTIVE" ;
VAL_ 1489 Input_11_state 0 "IDLE" 1 "ACTIVE" ;
VAL_ 1489 Input_12_state 0 "IDLE" 1 "ACTIVE" ;
VAL_ 1489 Output_7_state 0 "IDLE" 1 "ACTIVE" ;
VAL_ 1489 Output_8_state 0 "IDLE" 1 "ACTIVE" ;
VAL_ 1489 Output_9_state 0 "IDLE" 1 "ACTIVE" ;
VAL_ 1489 Output_10_state 0 "IDLE" 1 "ACTIVE" ;
VAL_ 1489 Output_11_state 0 "IDLE" 1 "ACTIVE" ;
VAL_ 1489 Output_12_state 0 "IDLE" 1 "ACTIVE" ;
VAL_ 1489 Output_13_state 0 "IDLE" 1 "ACTIVE" ;
VAL_ 1490 Positive_power_relay_status 0 "STATUS_OPEN" 1 "STATUS_CLOSED" ;
VAL_ 1490 Negative_power_relay_status 0 "STATUS_OPEN" 1 "STATUS_CLOSED" ;
VAL_ 1490 Precharge_power_relay_status 0 "STATUS_OPEN" 1 "STATUS_CLOSED" ;
VAL_ 1490 Middle_power_relay_status 0 "STATUS_OPEN" 1 "STATUS_CLOSED" ;
VAL_ 1490 Sleep_mode_request_flag 0 "STATUS_IDLE" 1 "STATUS_ACTIVE" ;
VAL_ 1490 Emergency_button_alarm_flag 0 "STATUS_IDLE" 1 "STATUS_ACTIVE" ;
VAL_ 1490 Start_signal_interlock_flag 0 "STATUS_IDLE" 1 "STATUS_ACTIVE" ;
VAL_ 1490 Start_signal_actuation_req_flag 0 "STATUS_IDLE" 1 "STATUS_ACTIVE" ;
VAL_ 1490 Heating_pad_request_flag 0 "IDLE" 1 "ACTIVE" ;
VAL_ 1490 Input_1_state 0 "IDLE" 1 "ACTIVE" ;
VAL_ 1490 Input_2_state 0 "IDLE" 1 "ACTIVE" ;
VAL_ 1490 Input_3_state 0 "IDLE" 1 "ACTIVE" ;
VAL_ 1490 Input_4_state 0 "IDLE" 1 "ACTIVE" ;
VAL_ 1490 Input_5_state 0 "IDLE" 1 "ACTIVE" ;
VAL_ 1490 Output_1_state 0 "IDLE" 1 "ACTIVE" ;
VAL_ 1490 Output_2_state 0 "IDLE" 1 "ACTIVE" ;
VAL_ 1490 Output_3_state 0 "IDLE" 1 "ACTIVE" ;
VAL_ 1490 Output_4_state 0 "IDLE" 1 "ACTIVE" ;
VAL_ 1490 Output_5_state 0 "IDLE" 1 "ACTIVE" ;
VAL_ 1490 Output_6_state 0 "IDLE" 1 "ACTIVE" ;
VAL_ 1490 Input_6_state 0 "IDLE" 1 "ACTIVE" ;
VAL_ 1490 Input_7_state 0 "IDLE" 1 "ACTIVE" ;
VAL_ 1490 Input_8_state 0 "IDLE" 1 "ACTIVE" ;
VAL_ 1490 Input_9_state 0 "IDLE" 1 "ACTIVE" ;
VAL_ 1490 Input_10_state 0 "IDLE" 1 "ACTIVE" ;
VAL_ 1490 Input_11_state 0 "IDLE" 1 "ACTIVE" ;
VAL_ 1490 Input_12_state 0 "IDLE" 1 "ACTIVE" ;
VAL_ 1490 Output_7_state 0 "IDLE" 1 "ACTIVE" ;
VAL_ 1490 Output_8_state 0 "IDLE" 1 "ACTIVE" ;
VAL_ 1490 Output_9_state 0 "IDLE" 1 "ACTIVE" ;
VAL_ 1490 Output_10_state 0 "IDLE" 1 "ACTIVE" ;
VAL_ 1490 Output_11_state 0 "IDLE" 1 "ACTIVE" ;
VAL_ 1490 Output_12_state 0 "IDLE" 1 "ACTIVE" ;
VAL_ 1490 Output_13_state 0 "IDLE" 1 "ACTIVE" ;
VAL_ 1491 Positive_power_relay_status 0 "STATUS_OPEN" 1 "STATUS_CLOSED" ;
VAL_ 1491 Negative_power_relay_status 0 "STATUS_OPEN" 1 "STATUS_CLOSED" ;
VAL_ 1491 Precharge_power_relay_status 0 "STATUS_OPEN" 1 "STATUS_CLOSED" ;
VAL_ 1491 Middle_power_relay_status 0 "STATUS_OPEN" 1 "STATUS_CLOSED" ;
VAL_ 1491 Sleep_mode_request_flag 0 "STATUS_IDLE" 1 "STATUS_ACTIVE" ;
VAL_ 1491 Emergency_button_alarm_flag 0 "STATUS_IDLE" 1 "STATUS_ACTIVE" ;
VAL_ 1491 Start_signal_interlock_flag 0 "STATUS_IDLE" 1 "STATUS_ACTIVE" ;
VAL_ 1491 Start_signal_actuation_req_flag 0 "STATUS_IDLE" 1 "STATUS_ACTIVE" ;
VAL_ 1491 Heating_pad_request_flag 0 "IDLE" 1 "ACTIVE" ;
VAL_ 1491 Input_1_state 0 "IDLE" 1 "ACTIVE" ;
VAL_ 1491 Input_2_state 0 "IDLE" 1 "ACTIVE" ;
VAL_ 1491 Input_3_state 0 "IDLE" 1 "ACTIVE" ;
VAL_ 1491 Input_4_state 0 "IDLE" 1 "ACTIVE" ;
VAL_ 1491 Input_5_state 0 "IDLE" 1 "ACTIVE" ;
VAL_ 1491 Output_1_state 0 "IDLE" 1 "ACTIVE" ;
VAL_ 1491 Output_2_state 0 "IDLE" 1 "ACTIVE" ;
VAL_ 1491 Output_3_state 0 "IDLE" 1 "ACTIVE" ;
VAL_ 1491 Output_4_state 0 "IDLE" 1 "ACTIVE" ;
VAL_ 1491 Output_5_state 0 "IDLE" 1 "ACTIVE" ;
VAL_ 1491 Output_6_state 0 "IDLE" 1 "ACTIVE" ;
VAL_ 1491 Input_6_state 0 "IDLE" 1 "ACTIVE" ;
VAL_ 1491 Input_7_state 0 "IDLE" 1 "ACTIVE" ;
VAL_ 1491 Input_8_state 0 "IDLE" 1 "ACTIVE" ;
VAL_ 1491 Input_9_state 0 "IDLE" 1 "ACTIVE" ;
VAL_ 1491 Input_10_state 0 "IDLE" 1 "ACTIVE" ;
VAL_ 1491 Input_11_state 0 "IDLE" 1 "ACTIVE" ;
VAL_ 1491 Input_12_state 0 "IDLE" 1 "ACTIVE" ;
VAL_ 1491 Output_7_state 0 "IDLE" 1 "ACTIVE" ;
VAL_ 1491 Output_8_state 0 "IDLE" 1 "ACTIVE" ;
VAL_ 1491 Output_9_state 0 "IDLE" 1 "ACTIVE" ;
VAL_ 1491 Output_10_state 0 "IDLE" 1 "ACTIVE" ;
VAL_ 1491 Output_11_state 0 "IDLE" 1 "ACTIVE" ;
VAL_ 1491 Output_12_state 0 "IDLE" 1 "ACTIVE" ;
VAL_ 1491 Output_13_state 0 "IDLE" 1 "ACTIVE" ;
VAL_ 1492 Positive_power_relay_status 0 "STATUS_OPEN" 1 "STATUS_CLOSED" ;
VAL_ 1492 Negative_power_relay_status 0 "STATUS_OPEN" 1 "STATUS_CLOSED" ;
VAL_ 1492 Precharge_power_relay_status 0 "STATUS_OPEN" 1 "STATUS_CLOSED" ;
VAL_ 1492 Middle_power_relay_status 0 "STATUS_OPEN" 1 "STATUS_CLOSED" ;
VAL_ 1492 Sleep_mode_request_flag 0 "STATUS_IDLE" 1 "STATUS_ACTIVE" ;
VAL_ 1492 Emergency_button_alarm_flag 0 "STATUS_IDLE" 1 "STATUS_ACTIVE" ;
VAL_ 1492 Start_signal_interlock_flag 0 "STATUS_IDLE" 1 "STATUS_ACTIVE" ;
VAL_ 1492 Start_signal_actuation_req_flag 0 "STATUS_IDLE" 1 "STATUS_ACTIVE" ;
VAL_ 1492 Heating_pad_request_flag 0 "IDLE" 1 "ACTIVE" ;
VAL_ 1492 Input_1_state 0 "IDLE" 1 "ACTIVE" ;
VAL_ 1492 Input_2_state 0 "IDLE" 1 "ACTIVE" ;
VAL_ 1492 Input_3_state 0 "IDLE" 1 "ACTIVE" ;
VAL_ 1492 Input_4_state 0 "IDLE" 1 "ACTIVE" ;
VAL_ 1492 Input_5_state 0 "IDLE" 1 "ACTIVE" ;
VAL_ 1492 Output_1_state 0 "IDLE" 1 "ACTIVE" ;
VAL_ 1492 Output_2_state 0 "IDLE" 1 "ACTIVE" ;
VAL_ 1492 Output_3_state 0 "IDLE" 1 "ACTIVE" ;
VAL_ 1492 Output_4_state 0 "IDLE" 1 "ACTIVE" ;
VAL_ 1492 Output_5_state 0 "IDLE" 1 "ACTIVE" ;
VAL_ 1492 Output_6_state 0 "IDLE" 1 "ACTIVE" ;
VAL_ 1492 Input_6_state 0 "IDLE" 1 "ACTIVE" ;
VAL_ 1492 Input_7_state 0 "IDLE" 1 "ACTIVE" ;
VAL_ 1492 Input_8_state 0 "IDLE" 1 "ACTIVE" ;
VAL_ 1492 Input_9_state 0 "IDLE" 1 "ACTIVE" ;
VAL_ 1492 Input_10_state 0 "IDLE" 1 "ACTIVE" ;
VAL_ 1492 Input_11_state 0 "IDLE" 1 "ACTIVE" ;
VAL_ 1492 Input_12_state 0 "IDLE" 1 "ACTIVE" ;
VAL_ 1492 Output_7_state 0 "IDLE" 1 "ACTIVE" ;
VAL_ 1492 Output_8_state 0 "IDLE" 1 "ACTIVE" ;
VAL_ 1492 Output_9_state 0 "IDLE" 1 "ACTIVE" ;
VAL_ 1492 Output_10_state 0 "IDLE" 1 "ACTIVE" ;
VAL_ 1492 Output_11_state 0 "IDLE" 1 "ACTIVE" ;
VAL_ 1492 Output_12_state 0 "IDLE" 1 "ACTIVE" ;
VAL_ 1492 Output_13_state 0 "IDLE" 1 "ACTIVE" ;
VAL_ 1493 Positive_power_relay_status 0 "STATUS_OPEN" 1 "STATUS_CLOSED" ;
VAL_ 1493 Negative_power_relay_status 0 "STATUS_OPEN" 1 "STATUS_CLOSED" ;
VAL_ 1493 Precharge_power_relay_status 0 "STATUS_OPEN" 1 "STATUS_CLOSED" ;
VAL_ 1493 Middle_power_relay_status 0 "STATUS_OPEN" 1 "STATUS_CLOSED" ;
VAL_ 1493 Sleep_mode_request_flag 0 "STATUS_IDLE" 1 "STATUS_ACTIVE" ;
VAL_ 1493 Emergency_button_alarm_flag 0 "STATUS_IDLE" 1 "STATUS_ACTIVE" ;
VAL_ 1493 Start_signal_interlock_flag 0 "STATUS_IDLE" 1 "STATUS_ACTIVE" ;
VAL_ 1493 Start_signal_actuation_req_flag 0 "STATUS_IDLE" 1 "STATUS_ACTIVE" ;
VAL_ 1493 Heating_pad_request_flag 0 "IDLE" 1 "ACTIVE" ;
VAL_ 1493 Input_1_state 0 "IDLE" 1 "ACTIVE" ;
VAL_ 1493 Input_2_state 0 "IDLE" 1 "ACTIVE" ;
VAL_ 1493 Input_3_state 0 "IDLE" 1 "ACTIVE" ;
VAL_ 1493 Input_4_state 0 "IDLE" 1 "ACTIVE" ;
VAL_ 1493 Input_5_state 0 "IDLE" 1 "ACTIVE" ;
VAL_ 1493 Output_1_state 0 "IDLE" 1 "ACTIVE" ;
VAL_ 1493 Output_2_state 0 "IDLE" 1 "ACTIVE" ;
VAL_ 1493 Output_3_state 0 "IDLE" 1 "ACTIVE" ;
VAL_ 1493 Output_4_state 0 "IDLE" 1 "ACTIVE" ;
VAL_ 1493 Output_5_state 0 "IDLE" 1 "ACTIVE" ;
VAL_ 1493 Output_6_state 0 "IDLE" 1 "ACTIVE" ;
VAL_ 1493 Input_6_state 0 "IDLE" 1 "ACTIVE" ;
VAL_ 1493 Input_7_state 0 "IDLE" 1 "ACTIVE" ;
VAL_ 1493 Input_8_state 0 "IDLE" 1 "ACTIVE" ;
VAL_ 1493 Input_9_state 0 "IDLE" 1 "ACTIVE" ;
VAL_ 1493 Input_10_state 0 "IDLE" 1 "ACTIVE" ;
VAL_ 1493 Input_11_state 0 "IDLE" 1 "ACTIVE" ;
VAL_ 1493 Input_12_state 0 "IDLE" 1 "ACTIVE" ;
VAL_ 1493 Output_7_state 0 "IDLE" 1 "ACTIVE" ;
VAL_ 1493 Output_8_state 0 "IDLE" 1 "ACTIVE" ;
VAL_ 1493 Output_9_state 0 "IDLE" 1 "ACTIVE" ;
VAL_ 1493 Output_10_state 0 "IDLE" 1 "ACTIVE" ;
VAL_ 1493 Output_11_state 0 "IDLE" 1 "ACTIVE" ;
VAL_ 1493 Output_12_state 0 "IDLE" 1 "ACTIVE" ;
VAL_ 1493 Output_13_state 0 "IDLE" 1 "ACTIVE" ;
VAL_ 1494 Positive_power_relay_status 0 "STATUS_OPEN" 1 "STATUS_CLOSED" ;
VAL_ 1494 Negative_power_relay_status 0 "STATUS_OPEN" 1 "STATUS_CLOSED" ;
VAL_ 1494 Precharge_power_relay_status 0 "STATUS_OPEN" 1 "STATUS_CLOSED" ;
VAL_ 1494 Middle_power_relay_status 0 "STATUS_OPEN" 1 "STATUS_CLOSED" ;
VAL_ 1494 Sleep_mode_request_flag 0 "STATUS_IDLE" 1 "STATUS_ACTIVE" ;
VAL_ 1494 Emergency_button_alarm_flag 0 "STATUS_IDLE" 1 "STATUS_ACTIVE" ;
VAL_ 1494 Start_signal_interlock_flag 0 "STATUS_IDLE" 1 "STATUS_ACTIVE" ;
VAL_ 1494 Start_signal_actuation_req_flag 0 "STATUS_IDLE" 1 "STATUS_ACTIVE" ;
VAL_ 1494 Heating_pad_request_flag 0 "IDLE" 1 "ACTIVE" ;
VAL_ 1494 Input_1_state 0 "IDLE" 1 "ACTIVE" ;
VAL_ 1494 Input_2_state 0 "IDLE" 1 "ACTIVE" ;
VAL_ 1494 Input_3_state 0 "IDLE" 1 "ACTIVE" ;
VAL_ 1494 Input_4_state 0 "IDLE" 1 "ACTIVE" ;
VAL_ 1494 Input_5_state 0 "IDLE" 1 "ACTIVE" ;
VAL_ 1494 Output_1_state 0 "IDLE" 1 "ACTIVE" ;
VAL_ 1494 Output_2_state 0 "IDLE" 1 "ACTIVE" ;
VAL_ 1494 Output_3_state 0 "IDLE" 1 "ACTIVE" ;
VAL_ 1494 Output_4_state 0 "IDLE" 1 "ACTIVE" ;
VAL_ 1494 Output_5_state 0 "IDLE" 1 "ACTIVE" ;
VAL_ 1494 Output_6_state 0 "IDLE" 1 "ACTIVE" ;
VAL_ 1494 Input_6_state 0 "IDLE" 1 "ACTIVE" ;
VAL_ 1494 Input_7_state 0 "IDLE" 1 "ACTIVE" ;
VAL_ 1494 Input_8_state 0 "IDLE" 1 "ACTIVE" ;
VAL_ 1494 Input_9_state 0 "IDLE" 1 "ACTIVE" ;
VAL_ 1494 Input_10_state 0 "IDLE" 1 "ACTIVE" ;
VAL_ 1494 Input_11_state 0 "IDLE" 1 "ACTIVE" ;
VAL_ 1494 Input_12_state 0 "IDLE" 1 "ACTIVE" ;
VAL_ 1494 Output_7_state 0 "IDLE" 1 "ACTIVE" ;
VAL_ 1494 Output_8_state 0 "IDLE" 1 "ACTIVE" ;
VAL_ 1494 Output_9_state 0 "IDLE" 1 "ACTIVE" ;
VAL_ 1494 Output_10_state 0 "IDLE" 1 "ACTIVE" ;
VAL_ 1494 Output_11_state 0 "IDLE" 1 "ACTIVE" ;
VAL_ 1494 Output_12_state 0 "IDLE" 1 "ACTIVE" ;
VAL_ 1494 Output_13_state 0 "IDLE" 1 "ACTIVE" ;
VAL_ 1495 Positive_power_relay_status 0 "STATUS_OPEN" 1 "STATUS_CLOSED" ;
VAL_ 1495 Negative_power_relay_status 0 "STATUS_OPEN" 1 "STATUS_CLOSED" ;
VAL_ 1495 Precharge_power_relay_status 0 "STATUS_OPEN" 1 "STATUS_CLOSED" ;
VAL_ 1495 Middle_power_relay_status 0 "STATUS_OPEN" 1 "STATUS_CLOSED" ;
VAL_ 1495 Sleep_mode_request_flag 0 "STATUS_IDLE" 1 "STATUS_ACTIVE" ;
VAL_ 1495 Emergency_button_alarm_flag 0 "STATUS_IDLE" 1 "STATUS_ACTIVE" ;
VAL_ 1495 Start_signal_interlock_flag 0 "STATUS_IDLE" 1 "STATUS_ACTIVE" ;
VAL_ 1495 Start_signal_actuation_req_flag 0 "STATUS_IDLE" 1 "STATUS_ACTIVE" ;
VAL_ 1495 Heating_pad_request_flag 0 "IDLE" 1 "ACTIVE" ;
VAL_ 1495 Input_1_state 0 "IDLE" 1 "ACTIVE" ;
VAL_ 1495 Input_2_state 0 "IDLE" 1 "ACTIVE" ;
VAL_ 1495 Input_3_state 0 "IDLE" 1 "ACTIVE" ;
VAL_ 1495 Input_4_state 0 "IDLE" 1 "ACTIVE" ;
VAL_ 1495 Input_5_state 0 "IDLE" 1 "ACTIVE" ;
VAL_ 1495 Output_1_state 0 "IDLE" 1 "ACTIVE" ;
VAL_ 1495 Output_2_state 0 "IDLE" 1 "ACTIVE" ;
VAL_ 1495 Output_3_state 0 "IDLE" 1 "ACTIVE" ;
VAL_ 1495 Output_4_state 0 "IDLE" 1 "ACTIVE" ;
VAL_ 1495 Output_5_state 0 "IDLE" 1 "ACTIVE" ;
VAL_ 1495 Output_6_state 0 "IDLE" 1 "ACTIVE" ;
VAL_ 1495 Input_6_state 0 "IDLE" 1 "ACTIVE" ;
VAL_ 1495 Input_7_state 0 "IDLE" 1 "ACTIVE" ;
VAL_ 1495 Input_8_state 0 "IDLE" 1 "ACTIVE" ;
VAL_ 1495 Input_9_state 0 "IDLE" 1 "ACTIVE" ;
VAL_ 1495 Input_10_state 0 "IDLE" 1 "ACTIVE" ;
VAL_ 1495 Input_11_state 0 "IDLE" 1 "ACTIVE" ;
VAL_ 1495 Input_12_state 0 "IDLE" 1 "ACTIVE" ;
VAL_ 1495 Output_7_state 0 "IDLE" 1 "ACTIVE" ;
VAL_ 1495 Output_8_state 0 "IDLE" 1 "ACTIVE" ;
VAL_ 1495 Output_9_state 0 "IDLE" 1 "ACTIVE" ;
VAL_ 1495 Output_10_state 0 "IDLE" 1 "ACTIVE" ;
VAL_ 1495 Output_11_state 0 "IDLE" 1 "ACTIVE" ;
VAL_ 1495 Output_12_state 0 "IDLE" 1 "ACTIVE" ;
VAL_ 1495 Output_13_state 0 "IDLE" 1 "ACTIVE" ;
VAL_ 1496 Positive_power_relay_status 0 "STATUS_OPEN" 1 "STATUS_CLOSED" ;
VAL_ 1496 Negative_power_relay_status 0 "STATUS_OPEN" 1 "STATUS_CLOSED" ;
VAL_ 1496 Precharge_power_relay_status 0 "STATUS_OPEN" 1 "STATUS_CLOSED" ;
VAL_ 1496 Middle_power_relay_status 0 "STATUS_OPEN" 1 "STATUS_CLOSED" ;
VAL_ 1496 Sleep_mode_request_flag 0 "STATUS_IDLE" 1 "STATUS_ACTIVE" ;
VAL_ 1496 Emergency_button_alarm_flag 0 "STATUS_IDLE" 1 "STATUS_ACTIVE" ;
VAL_ 1496 Start_signal_interlock_flag 0 "STATUS_IDLE" 1 "STATUS_ACTIVE" ;
VAL_ 1496 Start_signal_actuation_req_flag 0 "STATUS_IDLE" 1 "STATUS_ACTIVE" ;
VAL_ 1496 Heating_pad_request_flag 0 "IDLE" 1 "ACTIVE" ;
VAL_ 1496 Input_1_state 0 "IDLE" 1 "ACTIVE" ;
VAL_ 1496 Input_2_state 0 "IDLE" 1 "ACTIVE" ;
VAL_ 1496 Input_3_state 0 "IDLE" 1 "ACTIVE" ;
VAL_ 1496 Input_4_state 0 "IDLE" 1 "ACTIVE" ;
VAL_ 1496 Input_5_state 0 "IDLE" 1 "ACTIVE" ;
VAL_ 1496 Output_1_state 0 "IDLE" 1 "ACTIVE" ;
VAL_ 1496 Output_2_state 0 "IDLE" 1 "ACTIVE" ;
VAL_ 1496 Output_3_state 0 "IDLE" 1 "ACTIVE" ;
VAL_ 1496 Output_4_state 0 "IDLE" 1 "ACTIVE" ;
VAL_ 1496 Output_5_state 0 "IDLE" 1 "ACTIVE" ;
VAL_ 1496 Output_6_state 0 "IDLE" 1 "ACTIVE" ;
VAL_ 1496 Input_6_state 0 "IDLE" 1 "ACTIVE" ;
VAL_ 1496 Input_7_state 0 "IDLE" 1 "ACTIVE" ;
VAL_ 1496 Input_8_state 0 "IDLE" 1 "ACTIVE" ;
VAL_ 1496 Input_9_state 0 "IDLE" 1 "ACTIVE" ;
VAL_ 1496 Input_10_state 0 "IDLE" 1 "ACTIVE" ;
VAL_ 1496 Input_11_state 0 "IDLE" 1 "ACTIVE" ;
VAL_ 1496 Input_12_state 0 "IDLE" 1 "ACTIVE" ;
VAL_ 1496 Output_7_state 0 "IDLE" 1 "ACTIVE" ;
VAL_ 1496 Output_8_state 0 "IDLE" 1 "ACTIVE" ;
VAL_ 1496 Output_9_state 0 "IDLE" 1 "ACTIVE" ;
VAL_ 1496 Output_10_state 0 "IDLE" 1 "ACTIVE" ;
VAL_ 1496 Output_11_state 0 "IDLE" 1 "ACTIVE" ;
VAL_ 1496 Output_12_state 0 "IDLE" 1 "ACTIVE" ;
VAL_ 1496 Output_13_state 0 "IDLE" 1 "ACTIVE" ;
VAL_ 1497 Positive_power_relay_status 0 "STATUS_OPEN" 1 "STATUS_CLOSED" ;
VAL_ 1497 Negative_power_relay_status 0 "STATUS_OPEN" 1 "STATUS_CLOSED" ;
VAL_ 1497 Precharge_power_relay_status 0 "STATUS_OPEN" 1 "STATUS_CLOSED" ;
VAL_ 1497 Middle_power_relay_status 0 "STATUS_OPEN" 1 "STATUS_CLOSED" ;
VAL_ 1497 Sleep_mode_request_flag 0 "STATUS_IDLE" 1 "STATUS_ACTIVE" ;
VAL_ 1497 Emergency_button_alarm_flag 0 "STATUS_IDLE" 1 "STATUS_ACTIVE" ;
VAL_ 1497 Start_signal_interlock_flag 0 "STATUS_IDLE" 1 "STATUS_ACTIVE" ;
VAL_ 1497 Start_signal_actuation_req_flag 0 "STATUS_IDLE" 1 "STATUS_ACTIVE" ;
VAL_ 1497 Heating_pad_request_flag 0 "IDLE" 1 "ACTIVE" ;
VAL_ 1497 Input_1_state 0 "IDLE" 1 "ACTIVE" ;
VAL_ 1497 Input_2_state 0 "IDLE" 1 "ACTIVE" ;
VAL_ 1497 Input_3_state 0 "IDLE" 1 "ACTIVE" ;
VAL_ 1497 Input_4_state 0 "IDLE" 1 "ACTIVE" ;
VAL_ 1497 Input_5_state 0 "IDLE" 1 "ACTIVE" ;
VAL_ 1497 Output_1_state 0 "IDLE" 1 "ACTIVE" ;
VAL_ 1497 Output_2_state 0 "IDLE" 1 "ACTIVE" ;
VAL_ 1497 Output_3_state 0 "IDLE" 1 "ACTIVE" ;
VAL_ 1497 Output_4_state 0 "IDLE" 1 "ACTIVE" ;
VAL_ 1497 Output_5_state 0 "IDLE" 1 "ACTIVE" ;
VAL_ 1497 Output_6_state 0 "IDLE" 1 "ACTIVE" ;
VAL_ 1497 Input_6_state 0 "IDLE" 1 "ACTIVE" ;
VAL_ 1497 Input_7_state 0 "IDLE" 1 "ACTIVE" ;
VAL_ 1497 Input_8_state 0 "IDLE" 1 "ACTIVE" ;
VAL_ 1497 Input_9_state 0 "IDLE" 1 "ACTIVE" ;
VAL_ 1497 Input_10_state 0 "IDLE" 1 "ACTIVE" ;
VAL_ 1497 Input_11_state 0 "IDLE" 1 "ACTIVE" ;
VAL_ 1497 Input_12_state 0 "IDLE" 1 "ACTIVE" ;
VAL_ 1497 Output_7_state 0 "IDLE" 1 "ACTIVE" ;
VAL_ 1497 Output_8_state 0 "IDLE" 1 "ACTIVE" ;
VAL_ 1497 Output_9_state 0 "IDLE" 1 "ACTIVE" ;
VAL_ 1497 Output_10_state 0 "IDLE" 1 "ACTIVE" ;
VAL_ 1497 Output_11_state 0 "IDLE" 1 "ACTIVE" ;
VAL_ 1497 Output_12_state 0 "IDLE" 1 "ACTIVE" ;
VAL_ 1497 Output_13_state 0 "IDLE" 1 "ACTIVE" ;
VAL_ 1498 Positive_power_relay_status 0 "STATUS_OPEN" 1 "STATUS_CLOSED" ;
VAL_ 1498 Negative_power_relay_status 0 "STATUS_OPEN" 1 "STATUS_CLOSED" ;
VAL_ 1498 Precharge_power_relay_status 0 "STATUS_OPEN" 1 "STATUS_CLOSED" ;
VAL_ 1498 Middle_power_relay_status 0 "STATUS_OPEN" 1 "STATUS_CLOSED" ;
VAL_ 1498 Sleep_mode_request_flag 0 "STATUS_IDLE" 1 "STATUS_ACTIVE" ;
VAL_ 1498 Emergency_button_alarm_flag 0 "STATUS_IDLE" 1 "STATUS_ACTIVE" ;
VAL_ 1498 Start_signal_interlock_flag 0 "STATUS_IDLE" 1 "STATUS_ACTIVE" ;
VAL_ 1498 Start_signal_actuation_req_flag 0 "STATUS_IDLE" 1 "STATUS_ACTIVE" ;
VAL_ 1498 Heating_pad_request_flag 0 "IDLE" 1 "ACTIVE" ;
VAL_ 1498 Input_1_state 0 "IDLE" 1 "ACTIVE" ;
VAL_ 1498 Input_2_state 0 "IDLE" 1 "ACTIVE" ;
VAL_ 1498 Input_3_state 0 "IDLE" 1 "ACTIVE" ;
VAL_ 1498 Input_4_state 0 "IDLE" 1 "ACTIVE" ;
VAL_ 1498 Input_5_state 0 "IDLE" 1 "ACTIVE" ;
VAL_ 1498 Output_1_state 0 "IDLE" 1 "ACTIVE" ;
VAL_ 1498 Output_2_state 0 "IDLE" 1 "ACTIVE" ;
VAL_ 1498 Output_3_state 0 "IDLE" 1 "ACTIVE" ;
VAL_ 1498 Output_4_state 0 "IDLE" 1 "ACTIVE" ;
VAL_ 1498 Output_5_state 0 "IDLE" 1 "ACTIVE" ;
VAL_ 1498 Output_6_state 0 "IDLE" 1 "ACTIVE" ;
VAL_ 1498 Input_6_state 0 "IDLE" 1 "ACTIVE" ;
VAL_ 1498 Input_7_state 0 "IDLE" 1 "ACTIVE" ;
VAL_ 1498 Input_8_state 0 "IDLE" 1 "ACTIVE" ;
VAL_ 1498 Input_9_state 0 "IDLE" 1 "ACTIVE" ;
VAL_ 1498 Input_10_state 0 "IDLE" 1 "ACTIVE" ;
VAL_ 1498 Input_11_state 0 "IDLE" 1 "ACTIVE" ;
VAL_ 1498 Input_12_state 0 "IDLE" 1 "ACTIVE" ;
VAL_ 1498 Output_7_state 0 "IDLE" 1 "ACTIVE" ;
VAL_ 1498 Output_8_state 0 "IDLE" 1 "ACTIVE" ;
VAL_ 1498 Output_9_state 0 "IDLE" 1 "ACTIVE" ;
VAL_ 1498 Output_10_state 0 "IDLE" 1 "ACTIVE" ;
VAL_ 1498 Output_11_state 0 "IDLE" 1 "ACTIVE" ;
VAL_ 1498 Output_12_state 0 "IDLE" 1 "ACTIVE" ;
VAL_ 1498 Output_13_state 0 "IDLE" 1 "ACTIVE" ;
VAL_ 1499 Positive_power_relay_status 0 "STATUS_OPEN" 1 "STATUS_CLOSED" ;
VAL_ 1499 Negative_power_relay_status 0 "STATUS_OPEN" 1 "STATUS_CLOSED" ;
VAL_ 1499 Precharge_power_relay_status 0 "STATUS_OPEN" 1 "STATUS_CLOSED" ;
VAL_ 1499 Middle_power_relay_status 0 "STATUS_OPEN" 1 "STATUS_CLOSED" ;
VAL_ 1499 Sleep_mode_request_flag 0 "STATUS_IDLE" 1 "STATUS_ACTIVE" ;
VAL_ 1499 Emergency_button_alarm_flag 0 "STATUS_IDLE" 1 "STATUS_ACTIVE" ;
VAL_ 1499 Start_signal_interlock_flag 0 "STATUS_IDLE" 1 "STATUS_ACTIVE" ;
VAL_ 1499 Start_signal_actuation_req_flag 0 "STATUS_IDLE" 1 "STATUS_ACTIVE" ;
VAL_ 1499 Heating_pad_request_flag 0 "IDLE" 1 "ACTIVE" ;
VAL_ 1499 Input_1_state 0 "IDLE" 1 "ACTIVE" ;
VAL_ 1499 Input_2_state 0 "IDLE" 1 "ACTIVE" ;
VAL_ 1499 Input_3_state 0 "IDLE" 1 "ACTIVE" ;
VAL_ 1499 Input_4_state 0 "IDLE" 1 "ACTIVE" ;
VAL_ 1499 Input_5_state 0 "IDLE" 1 "ACTIVE" ;
VAL_ 1499 Output_1_state 0 "IDLE" 1 "ACTIVE" ;
VAL_ 1499 Output_2_state 0 "IDLE" 1 "ACTIVE" ;
VAL_ 1499 Output_3_state 0 "IDLE" 1 "ACTIVE" ;
VAL_ 1499 Output_4_state 0 "IDLE" 1 "ACTIVE" ;
VAL_ 1499 Output_5_state 0 "IDLE" 1 "ACTIVE" ;
VAL_ 1499 Output_6_state 0 "IDLE" 1 "ACTIVE" ;
VAL_ 1499 Input_6_state 0 "IDLE" 1 "ACTIVE" ;
VAL_ 1499 Input_7_state 0 "IDLE" 1 "ACTIVE" ;
VAL_ 1499 Input_8_state 0 "IDLE" 1 "ACTIVE" ;
VAL_ 1499 Input_9_state 0 "IDLE" 1 "ACTIVE" ;
VAL_ 1499 Input_10_state 0 "IDLE" 1 "ACTIVE" ;
VAL_ 1499 Input_11_state 0 "IDLE" 1 "ACTIVE" ;
VAL_ 1499 Input_12_state 0 "IDLE" 1 "ACTIVE" ;
VAL_ 1499 Output_7_state 0 "IDLE" 1 "ACTIVE" ;
VAL_ 1499 Output_8_state 0 "IDLE" 1 "ACTIVE" ;
VAL_ 1499 Output_9_state 0 "IDLE" 1 "ACTIVE" ;
VAL_ 1499 Output_10_state 0 "IDLE" 1 "ACTIVE" ;
VAL_ 1499 Output_11_state 0 "IDLE" 1 "ACTIVE" ;
VAL_ 1499 Output_12_state 0 "IDLE" 1 "ACTIVE" ;
VAL_ 1499 Output_13_state 0 "IDLE" 1 "ACTIVE" ;
VAL_ 1500 Positive_power_relay_status 0 "STATUS_OPEN" 1 "STATUS_CLOSED" ;
VAL_ 1500 Negative_power_relay_status 0 "STATUS_OPEN" 1 "STATUS_CLOSED" ;
VAL_ 1500 Precharge_power_relay_status 0 "STATUS_OPEN" 1 "STATUS_CLOSED" ;
VAL_ 1500 Middle_power_relay_status 0 "STATUS_OPEN" 1 "STATUS_CLOSED" ;
VAL_ 1500 Sleep_mode_request_flag 0 "STATUS_IDLE" 1 "STATUS_ACTIVE" ;
VAL_ 1500 Emergency_button_alarm_flag 0 "STATUS_IDLE" 1 "STATUS_ACTIVE" ;
VAL_ 1500 Start_signal_interlock_flag 0 "STATUS_IDLE" 1 "STATUS_ACTIVE" ;
VAL_ 1500 Start_signal_actuation_req_flag 0 "STATUS_IDLE" 1 "STATUS_ACTIVE" ;
VAL_ 1500 Heating_pad_request_flag 0 "IDLE" 1 "ACTIVE" ;
VAL_ 1500 Input_1_state 0 "IDLE" 1 "ACTIVE" ;
VAL_ 1500 Input_2_state 0 "IDLE" 1 "ACTIVE" ;
VAL_ 1500 Input_3_state 0 "IDLE" 1 "ACTIVE" ;
VAL_ 1500 Input_4_state 0 "IDLE" 1 "ACTIVE" ;
VAL_ 1500 Input_5_state 0 "IDLE" 1 "ACTIVE" ;
VAL_ 1500 Output_1_state 0 "IDLE" 1 "ACTIVE" ;
VAL_ 1500 Output_2_state 0 "IDLE" 1 "ACTIVE" ;
VAL_ 1500 Output_3_state 0 "IDLE" 1 "ACTIVE" ;
VAL_ 1500 Output_4_state 0 "IDLE" 1 "ACTIVE" ;
VAL_ 1500 Output_5_state 0 "IDLE" 1 "ACTIVE" ;
VAL_ 1500 Output_6_state 0 "IDLE" 1 "ACTIVE" ;
VAL_ 1500 Input_6_state 0 "IDLE" 1 "ACTIVE" ;
VAL_ 1500 Input_7_state 0 "IDLE" 1 "ACTIVE" ;
VAL_ 1500 Input_8_state 0 "IDLE" 1 "ACTIVE" ;
VAL_ 1500 Input_9_state 0 "IDLE" 1 "ACTIVE" ;
VAL_ 1500 Input_10_state 0 "IDLE" 1 "ACTIVE" ;
VAL_ 1500 Input_11_state 0 "IDLE" 1 "ACTIVE" ;
VAL_ 1500 Input_12_state 0 "IDLE" 1 "ACTIVE" ;
VAL_ 1500 Output_7_state 0 "IDLE" 1 "ACTIVE" ;
VAL_ 1500 Output_8_state 0 "IDLE" 1 "ACTIVE" ;
VAL_ 1500 Output_9_state 0 "IDLE" 1 "ACTIVE" ;
VAL_ 1500 Output_10_state 0 "IDLE" 1 "ACTIVE" ;
VAL_ 1500 Output_11_state 0 "IDLE" 1 "ACTIVE" ;
VAL_ 1500 Output_12_state 0 "IDLE" 1 "ACTIVE" ;
VAL_ 1500 Output_13_state 0 "IDLE" 1 "ACTIVE" ;
VAL_ 1501 Positive_power_relay_status 0 "STATUS_OPEN" 1 "STATUS_CLOSED" ;
VAL_ 1501 Negative_power_relay_status 0 "STATUS_OPEN" 1 "STATUS_CLOSED" ;
VAL_ 1501 Precharge_power_relay_status 0 "STATUS_OPEN" 1 "STATUS_CLOSED" ;
VAL_ 1501 Middle_power_relay_status 0 "STATUS_OPEN" 1 "STATUS_CLOSED" ;
VAL_ 1501 Sleep_mode_request_flag 0 "STATUS_IDLE" 1 "STATUS_ACTIVE" ;
VAL_ 1501 Emergency_button_alarm_flag 0 "STATUS_IDLE" 1 "STATUS_ACTIVE" ;
VAL_ 1501 Start_signal_interlock_flag 0 "STATUS_IDLE" 1 "STATUS_ACTIVE" ;
VAL_ 1501 Start_signal_actuation_req_flag 0 "STATUS_IDLE" 1 "STATUS_ACTIVE" ;
VAL_ 1501 Heating_pad_request_flag 0 "IDLE" 1 "ACTIVE" ;
VAL_ 1501 Input_1_state 0 "IDLE" 1 "ACTIVE" ;
VAL_ 1501 Input_2_state 0 "IDLE" 1 "ACTIVE" ;
VAL_ 1501 Input_3_state 0 "IDLE" 1 "ACTIVE" ;
VAL_ 1501 Input_4_state 0 "IDLE" 1 "ACTIVE" ;
VAL_ 1501 Input_5_state 0 "IDLE" 1 "ACTIVE" ;
VAL_ 1501 Output_1_state 0 "IDLE" 1 "ACTIVE" ;
VAL_ 1501 Output_2_state 0 "IDLE" 1 "ACTIVE" ;
VAL_ 1501 Output_3_state 0 "IDLE" 1 "ACTIVE" ;
VAL_ 1501 Output_4_state 0 "IDLE" 1 "ACTIVE" ;
VAL_ 1501 Output_5_state 0 "IDLE" 1 "ACTIVE" ;
VAL_ 1501 Output_6_state 0 "IDLE" 1 "ACTIVE" ;
VAL_ 1501 Input_6_state 0 "IDLE" 1 "ACTIVE" ;
VAL_ 1501 Input_7_state 0 "IDLE" 1 "ACTIVE" ;
VAL_ 1501 Input_8_state 0 "IDLE" 1 "ACTIVE" ;
VAL_ 1501 Input_9_state 0 "IDLE" 1 "ACTIVE" ;
VAL_ 1501 Input_10_state 0 "IDLE" 1 "ACTIVE" ;
VAL_ 1501 Input_11_state 0 "IDLE" 1 "ACTIVE" ;
VAL_ 1501 Input_12_state 0 "IDLE" 1 "ACTIVE" ;
VAL_ 1501 Output_7_state 0 "IDLE" 1 "ACTIVE" ;
VAL_ 1501 Output_8_state 0 "IDLE" 1 "ACTIVE" ;
VAL_ 1501 Output_9_state 0 "IDLE" 1 "ACTIVE" ;
VAL_ 1501 Output_10_state 0 "IDLE" 1 "ACTIVE" ;
VAL_ 1501 Output_11_state 0 "IDLE" 1 "ACTIVE" ;
VAL_ 1501 Output_12_state 0 "IDLE" 1 "ACTIVE" ;
VAL_ 1501 Output_13_state 0 "IDLE" 1 "ACTIVE" ;
VAL_ 1502 Positive_power_relay_status 0 "STATUS_OPEN" 1 "STATUS_CLOSED" ;
VAL_ 1502 Negative_power_relay_status 0 "STATUS_OPEN" 1 "STATUS_CLOSED" ;
VAL_ 1502 Precharge_power_relay_status 0 "STATUS_OPEN" 1 "STATUS_CLOSED" ;
VAL_ 1502 Middle_power_relay_status 0 "STATUS_OPEN" 1 "STATUS_CLOSED" ;
VAL_ 1502 Sleep_mode_request_flag 0 "STATUS_IDLE" 1 "STATUS_ACTIVE" ;
VAL_ 1502 Emergency_button_alarm_flag 0 "STATUS_IDLE" 1 "STATUS_ACTIVE" ;
VAL_ 1502 Start_signal_interlock_flag 0 "STATUS_IDLE" 1 "STATUS_ACTIVE" ;
VAL_ 1502 Start_signal_actuation_req_flag 0 "STATUS_IDLE" 1 "STATUS_ACTIVE" ;
VAL_ 1502 Heating_pad_request_flag 0 "IDLE" 1 "ACTIVE" ;
VAL_ 1502 Input_1_state 0 "IDLE" 1 "ACTIVE" ;
VAL_ 1502 Input_2_state 0 "IDLE" 1 "ACTIVE" ;
VAL_ 1502 Input_3_state 0 "IDLE" 1 "ACTIVE" ;
VAL_ 1502 Input_4_state 0 "IDLE" 1 "ACTIVE" ;
VAL_ 1502 Input_5_state 0 "IDLE" 1 "ACTIVE" ;
VAL_ 1502 Output_1_state 0 "IDLE" 1 "ACTIVE" ;
VAL_ 1502 Output_2_state 0 "IDLE" 1 "ACTIVE" ;
VAL_ 1502 Output_3_state 0 "IDLE" 1 "ACTIVE" ;
VAL_ 1502 Output_4_state 0 "IDLE" 1 "ACTIVE" ;
VAL_ 1502 Output_5_state 0 "IDLE" 1 "ACTIVE" ;
VAL_ 1502 Output_6_state 0 "IDLE" 1 "ACTIVE" ;
VAL_ 1502 Input_6_state 0 "IDLE" 1 "ACTIVE" ;
VAL_ 1502 Input_7_state 0 "IDLE" 1 "ACTIVE" ;
VAL_ 1502 Input_8_state 0 "IDLE" 1 "ACTIVE" ;
VAL_ 1502 Input_9_state 0 "IDLE" 1 "ACTIVE" ;
VAL_ 1502 Input_10_state 0 "IDLE" 1 "ACTIVE" ;
VAL_ 1502 Input_11_state 0 "IDLE" 1 "ACTIVE" ;
VAL_ 1502 Input_12_state 0 "IDLE" 1 "ACTIVE" ;
VAL_ 1502 Output_7_state 0 "IDLE" 1 "ACTIVE" ;
VAL_ 1502 Output_8_state 0 "IDLE" 1 "ACTIVE" ;
VAL_ 1502 Output_9_state 0 "IDLE" 1 "ACTIVE" ;
VAL_ 1502 Output_10_state 0 "IDLE" 1 "ACTIVE" ;
VAL_ 1502 Output_11_state 0 "IDLE" 1 "ACTIVE" ;
VAL_ 1502 Output_12_state 0 "IDLE" 1 "ACTIVE" ;
VAL_ 1502 Output_13_state 0 "IDLE" 1 "ACTIVE" ;
VAL_ 1503 Positive_power_relay_status 0 "STATUS_OPEN" 1 "STATUS_CLOSED" ;
VAL_ 1503 Negative_power_relay_status 0 "STATUS_OPEN" 1 "STATUS_CLOSED" ;
VAL_ 1503 Precharge_power_relay_status 0 "STATUS_OPEN" 1 "STATUS_CLOSED" ;
VAL_ 1503 Middle_power_relay_status 0 "STATUS_OPEN" 1 "STATUS_CLOSED" ;
VAL_ 1503 Sleep_mode_request_flag 0 "STATUS_IDLE" 1 "STATUS_ACTIVE" ;
VAL_ 1503 Emergency_button_alarm_flag 0 "STATUS_IDLE" 1 "STATUS_ACTIVE" ;
VAL_ 1503 Start_signal_interlock_flag 0 "STATUS_IDLE" 1 "STATUS_ACTIVE" ;
VAL_ 1503 Start_signal_actuation_req_flag 0 "STATUS_IDLE" 1 "STATUS_ACTIVE" ;
VAL_ 1503 Heating_pad_request_flag 0 "IDLE" 1 "ACTIVE" ;
VAL_ 1503 Input_1_state 0 "IDLE" 1 "ACTIVE" ;
VAL_ 1503 Input_2_state 0 "IDLE" 1 "ACTIVE" ;
VAL_ 1503 Input_3_state 0 "IDLE" 1 "ACTIVE" ;
VAL_ 1503 Input_4_state 0 "IDLE" 1 "ACTIVE" ;
VAL_ 1503 Input_5_state 0 "IDLE" 1 "ACTIVE" ;
VAL_ 1503 Output_1_state 0 "IDLE" 1 "ACTIVE" ;
VAL_ 1503 Output_2_state 0 "IDLE" 1 "ACTIVE" ;
VAL_ 1503 Output_3_state 0 "IDLE" 1 "ACTIVE" ;
VAL_ 1503 Output_4_state 0 "IDLE" 1 "ACTIVE" ;
VAL_ 1503 Output_5_state 0 "IDLE" 1 "ACTIVE" ;
VAL_ 1503 Output_6_state 0 "IDLE" 1 "ACTIVE" ;
VAL_ 1503 Input_6_state 0 "IDLE" 1 "ACTIVE" ;
VAL_ 1503 Input_7_state 0 "IDLE" 1 "ACTIVE" ;
VAL_ 1503 Input_8_state 0 "IDLE" 1 "ACTIVE" ;
VAL_ 1503 Input_9_state 0 "IDLE" 1 "ACTIVE" ;
VAL_ 1503 Input_10_state 0 "IDLE" 1 "ACTIVE" ;
VAL_ 1503 Input_11_state 0 "IDLE" 1 "ACTIVE" ;
VAL_ 1503 Input_12_state 0 "IDLE" 1 "ACTIVE" ;
VAL_ 1503 Output_7_state 0 "IDLE" 1 "ACTIVE" ;
VAL_ 1503 Output_8_state 0 "IDLE" 1 "ACTIVE" ;
VAL_ 1503 Output_9_state 0 "IDLE" 1 "ACTIVE" ;
VAL_ 1503 Output_10_state 0 "IDLE" 1 "ACTIVE" ;
VAL_ 1503 Output_11_state 0 "IDLE" 1 "ACTIVE" ;
VAL_ 1503 Output_12_state 0 "IDLE" 1 "ACTIVE" ;
VAL_ 1503 Output_13_state 0 "IDLE" 1 "ACTIVE" ;
VAL_ 1520 Hardware_type 1 "wBMS_R24" 2 "wBMS_MX" 3 "wBMS_MX_Pro" 4 "wBMS_R32" 5 "wBMS_HX" ;
VAL_ 1521 Hardware_type 1 "wBMS_R24" 2 "wBMS_MX" 3 "wBMS_MX_Pro" 4 "wBMS_R32" 5 "wBMS_HX" ;
VAL_ 1522 Hardware_type 1 "wBMS_R24" 2 "wBMS_MX" 3 "wBMS_MX_Pro" 4 "wBMS_R32" 5 "wBMS_HX" ;
VAL_ 1523 Hardware_type 1 "wBMS_R24" 2 "wBMS_MX" 3 "wBMS_MX_Pro" 4 "wBMS_R32" 5 "wBMS_HX" ;
VAL_ 1524 Hardware_type 1 "wBMS_R24" 2 "wBMS_MX" 3 "wBMS_MX_Pro" 4 "wBMS_R32" 5 "wBMS_HX" ;
VAL_ 1525 Hardware_type 1 "wBMS_R24" 2 "wBMS_MX" 3 "wBMS_MX_Pro" 4 "wBMS_R32" 5 "wBMS_HX" ;
VAL_ 1526 Hardware_type 1 "wBMS_R24" 2 "wBMS_MX" 3 "wBMS_MX_Pro" 4 "wBMS_R32" 5 "wBMS_HX" ;
VAL_ 1527 Hardware_type 1 "wBMS_R24" 2 "wBMS_MX" 3 "wBMS_MX_Pro" 4 "wBMS_R32" 5 "wBMS_HX" ;
VAL_ 1528 Hardware_type 1 "wBMS_R24" 2 "wBMS_MX" 3 "wBMS_MX_Pro" 4 "wBMS_R32" 5 "wBMS_HX" ;
VAL_ 1529 Hardware_type 1 "wBMS_R24" 2 "wBMS_MX" 3 "wBMS_MX_Pro" 4 "wBMS_R32" 5 "wBMS_HX" ;
VAL_ 1530 Hardware_type 1 "wBMS_R24" 2 "wBMS_MX" 3 "wBMS_MX_Pro" 4 "wBMS_R32" 5 "wBMS_HX" ;
VAL_ 1531 Hardware_type 1 "wBMS_R24" 2 "wBMS_MX" 3 "wBMS_MX_Pro" 4 "wBMS_R32" 5 "wBMS_HX" ;
VAL_ 1532 Hardware_type 1 "wBMS_R24" 2 "wBMS_MX" 3 "wBMS_MX_Pro" 4 "wBMS_R32" 5 "wBMS_HX" ;
VAL_ 1533 Hardware_type 1 "wBMS_R24" 2 "wBMS_MX" 3 "wBMS_MX_Pro" 4 "wBMS_R32" 5 "wBMS_HX" ;
VAL_ 1534 Hardware_type 1 "wBMS_R24" 2 "wBMS_MX" 3 "wBMS_MX_Pro" 4 "wBMS_R32" 5 "wBMS_HX" ;
VAL_ 1535 Hardware_type 1 "wBMS_R24" 2 "wBMS_MX" 3 "wBMS_MX_Pro" 4 "wBMS_R32" 5 "wBMS_HX" ;
VAL_ 560 Output_1_Interlock 0 "IDLE" 1 "ACTIVE" ;
VAL_ 560 Output_2_Interlock 0 "IDLE" 1 "ACTIVE" ;
VAL_ 560 Output_3_Interlock 0 "IDLE" 1 "ACTIVE" ;
VAL_ 560 Output_4_Interlock 0 "IDLE" 1 "ACTIVE" ;
VAL_ 560 Output_5_Interlock 0 "IDLE" 1 "ACTIVE" ;
VAL_ 560 Output_6_Interlock 0 "IDLE" 1 "ACTIVE" ;
VAL_ 560 BMU_Reset_signal 0 "IDLE" 1 "ACTIVE" ;
VAL_ 560 Output_7_Interlock 0 "IDLE" 1 "ACTIVE" ;
VAL_ 560 Output_8_Interlock 0 "IDLE" 1 "ACTIVE" ;
VAL_ 560 Output_9_Interlock 0 "IDLE" 1 "ACTIVE" ;
VAL_ 560 Output_10_Interlock 0 "IDLE" 1 "ACTIVE" ;
VAL_ 560 Output_11_Interlock 0 "IDLE" 1 "ACTIVE" ;
VAL_ 560 Output_12_Interlock 0 "IDLE" 1 "ACTIVE" ;
VAL_ 560 Output_13_Interlock 0 "IDLE" 1 "ACTIVE" ;
VAL_ 561 Output_1_Interlock 0 "IDLE" 1 "ACTIVE" ;
VAL_ 561 Output_2_Interlock 0 "IDLE" 1 "ACTIVE" ;
VAL_ 561 Output_3_Interlock 0 "IDLE" 1 "ACTIVE" ;
VAL_ 561 Output_4_Interlock 0 "IDLE" 1 "ACTIVE" ;
VAL_ 561 Output_5_Interlock 0 "IDLE" 1 "ACTIVE" ;
VAL_ 561 Output_6_Interlock 0 "IDLE" 1 "ACTIVE" ;
VAL_ 561 BMU_Reset_signal 0 "IDLE" 1 "ACTIVE" ;
VAL_ 561 Output_7_Interlock 0 "IDLE" 1 "ACTIVE" ;
VAL_ 561 Output_8_Interlock 0 "IDLE" 1 "ACTIVE" ;
VAL_ 561 Output_9_Interlock 0 "IDLE" 1 "ACTIVE" ;
VAL_ 561 Output_10_Interlock 0 "IDLE" 1 "ACTIVE" ;
VAL_ 561 Output_11_Interlock 0 "IDLE" 1 "ACTIVE" ;
VAL_ 561 Output_12_Interlock 0 "IDLE" 1 "ACTIVE" ;
VAL_ 561 Output_13_Interlock 0 "IDLE" 1 "ACTIVE" ;
VAL_ 562 Output_1_Interlock 0 "IDLE" 1 "ACTIVE" ;
VAL_ 562 Output_2_Interlock 0 "IDLE" 1 "ACTIVE" ;
VAL_ 562 Output_3_Interlock 0 "IDLE" 1 "ACTIVE" ;
VAL_ 562 Output_4_Interlock 0 "IDLE" 1 "ACTIVE" ;
VAL_ 562 Output_5_Interlock 0 "IDLE" 1 "ACTIVE" ;
VAL_ 562 Output_6_Interlock 0 "IDLE" 1 "ACTIVE" ;
VAL_ 562 BMU_Reset_signal 0 "IDLE" 1 "ACTIVE" ;
VAL_ 562 Output_7_Interlock 0 "IDLE" 1 "ACTIVE" ;
VAL_ 562 Output_8_Interlock 0 "IDLE" 1 "ACTIVE" ;
VAL_ 562 Output_9_Interlock 0 "IDLE" 1 "ACTIVE" ;
VAL_ 562 Output_10_Interlock 0 "IDLE" 1 "ACTIVE" ;
VAL_ 562 Output_11_Interlock 0 "IDLE" 1 "ACTIVE" ;
VAL_ 562 Output_12_Interlock 0 "IDLE" 1 "ACTIVE" ;
VAL_ 562 Output_13_Interlock 0 "IDLE" 1 "ACTIVE" ;
VAL_ 563 Output_1_Interlock 0 "IDLE" 1 "ACTIVE" ;
VAL_ 563 Output_2_Interlock 0 "IDLE" 1 "ACTIVE" ;
VAL_ 563 Output_3_Interlock 0 "IDLE" 1 "ACTIVE" ;
VAL_ 563 Output_4_Interlock 0 "IDLE" 1 "ACTIVE" ;
VAL_ 563 Output_5_Interlock 0 "IDLE" 1 "ACTIVE" ;
VAL_ 563 Output_6_Interlock 0 "IDLE" 1 "ACTIVE" ;
VAL_ 563 BMU_Reset_signal 0 "IDLE" 1 "ACTIVE" ;
VAL_ 563 Output_7_Interlock 0 "IDLE" 1 "ACTIVE" ;
VAL_ 563 Output_8_Interlock 0 "IDLE" 1 "ACTIVE" ;
VAL_ 563 Output_9_Interlock 0 "IDLE" 1 "ACTIVE" ;
VAL_ 563 Output_10_Interlock 0 "IDLE" 1 "ACTIVE" ;
VAL_ 563 Output_11_Interlock 0 "IDLE" 1 "ACTIVE" ;
VAL_ 563 Output_12_Interlock 0 "IDLE" 1 "ACTIVE" ;
VAL_ 563 Output_13_Interlock 0 "IDLE" 1 "ACTIVE" ;
VAL_ 564 Output_1_Interlock 0 "IDLE" 1 "ACTIVE" ;
VAL_ 564 Output_2_Interlock 0 "IDLE" 1 "ACTIVE" ;
VAL_ 564 Output_3_Interlock 0 "IDLE" 1 "ACTIVE" ;
VAL_ 564 Output_4_Interlock 0 "IDLE" 1 "ACTIVE" ;
VAL_ 564 Output_5_Interlock 0 "IDLE" 1 "ACTIVE" ;
VAL_ 564 Output_6_Interlock 0 "IDLE" 1 "ACTIVE" ;
VAL_ 564 BMU_Reset_signal 0 "IDLE" 1 "ACTIVE" ;
VAL_ 564 Output_7_Interlock 0 "IDLE" 1 "ACTIVE" ;
VAL_ 564 Output_8_Interlock 0 "IDLE" 1 "ACTIVE" ;
VAL_ 564 Output_9_Interlock 0 "IDLE" 1 "ACTIVE" ;
VAL_ 564 Output_10_Interlock 0 "IDLE" 1 "ACTIVE" ;
VAL_ 564 Output_11_Interlock 0 "IDLE" 1 "ACTIVE" ;
VAL_ 564 Output_12_Interlock 0 "IDLE" 1 "ACTIVE" ;
VAL_ 564 Output_13_Interlock 0 "IDLE" 1 "ACTIVE" ;
VAL_ 565 Output_1_Interlock 0 "IDLE" 1 "ACTIVE" ;
VAL_ 565 Output_2_Interlock 0 "IDLE" 1 "ACTIVE" ;
VAL_ 565 Output_3_Interlock 0 "IDLE" 1 "ACTIVE" ;
VAL_ 565 Output_4_Interlock 0 "IDLE" 1 "ACTIVE" ;
VAL_ 565 Output_5_Interlock 0 "IDLE" 1 "ACTIVE" ;
VAL_ 565 Output_6_Interlock 0 "IDLE" 1 "ACTIVE" ;
VAL_ 565 BMU_Reset_signal 0 "IDLE" 1 "ACTIVE" ;
VAL_ 565 Output_7_Interlock 0 "IDLE" 1 "ACTIVE" ;
VAL_ 565 Output_8_Interlock 0 "IDLE" 1 "ACTIVE" ;
VAL_ 565 Output_9_Interlock 0 "IDLE" 1 "ACTIVE" ;
VAL_ 565 Output_10_Interlock 0 "IDLE" 1 "ACTIVE" ;
VAL_ 565 Output_11_Interlock 0 "IDLE" 1 "ACTIVE" ;
VAL_ 565 Output_12_Interlock 0 "IDLE" 1 "ACTIVE" ;
VAL_ 565 Output_13_Interlock 0 "IDLE" 1 "ACTIVE" ;
VAL_ 566 Output_1_Interlock 0 "IDLE" 1 "ACTIVE" ;
VAL_ 566 Output_2_Interlock 0 "IDLE" 1 "ACTIVE" ;
VAL_ 566 Output_3_Interlock 0 "IDLE" 1 "ACTIVE" ;
VAL_ 566 Output_4_Interlock 0 "IDLE" 1 "ACTIVE" ;
VAL_ 566 Output_5_Interlock 0 "IDLE" 1 "ACTIVE" ;
VAL_ 566 Output_6_Interlock 0 "IDLE" 1 "ACTIVE" ;
VAL_ 566 BMU_Reset_signal 0 "IDLE" 1 "ACTIVE" ;
VAL_ 566 Output_7_Interlock 0 "IDLE" 1 "ACTIVE" ;
VAL_ 566 Output_8_Interlock 0 "IDLE" 1 "ACTIVE" ;
VAL_ 566 Output_9_Interlock 0 "IDLE" 1 "ACTIVE" ;
VAL_ 566 Output_10_Interlock 0 "IDLE" 1 "ACTIVE" ;
VAL_ 566 Output_11_Interlock 0 "IDLE" 1 "ACTIVE" ;
VAL_ 566 Output_12_Interlock 0 "IDLE" 1 "ACTIVE" ;
VAL_ 566 Output_13_Interlock 0 "IDLE" 1 "ACTIVE" ;
VAL_ 567 Output_1_Interlock 0 "IDLE" 1 "ACTIVE" ;
VAL_ 567 Output_2_Interlock 0 "IDLE" 1 "ACTIVE" ;
VAL_ 567 Output_3_Interlock 0 "IDLE" 1 "ACTIVE" ;
VAL_ 567 Output_4_Interlock 0 "IDLE" 1 "ACTIVE" ;
VAL_ 567 Output_5_Interlock 0 "IDLE" 1 "ACTIVE" ;
VAL_ 567 Output_6_Interlock 0 "IDLE" 1 "ACTIVE" ;
VAL_ 567 BMU_Reset_signal 0 "IDLE" 1 "ACTIVE" ;
VAL_ 567 Output_7_Interlock 0 "IDLE" 1 "ACTIVE" ;
VAL_ 567 Output_8_Interlock 0 "IDLE" 1 "ACTIVE" ;
VAL_ 567 Output_9_Interlock 0 "IDLE" 1 "ACTIVE" ;
VAL_ 567 Output_10_Interlock 0 "IDLE" 1 "ACTIVE" ;
VAL_ 567 Output_11_Interlock 0 "IDLE" 1 "ACTIVE" ;
VAL_ 567 Output_12_Interlock 0 "IDLE" 1 "ACTIVE" ;
VAL_ 567 Output_13_Interlock 0 "IDLE" 1 "ACTIVE" ;
VAL_ 568 Output_1_Interlock 0 "IDLE" 1 "ACTIVE" ;
VAL_ 568 Output_2_Interlock 0 "IDLE" 1 "ACTIVE" ;
VAL_ 568 Output_3_Interlock 0 "IDLE" 1 "ACTIVE" ;
VAL_ 568 Output_4_Interlock 0 "IDLE" 1 "ACTIVE" ;
VAL_ 568 Output_5_Interlock 0 "IDLE" 1 "ACTIVE" ;
VAL_ 568 Output_6_Interlock 0 "IDLE" 1 "ACTIVE" ;
VAL_ 568 BMU_Reset_signal 0 "IDLE" 1 "ACTIVE" ;
VAL_ 568 Output_7_Interlock 0 "IDLE" 1 "ACTIVE" ;
VAL_ 568 Output_8_Interlock 0 "IDLE" 1 "ACTIVE" ;
VAL_ 568 Output_9_Interlock 0 "IDLE" 1 "ACTIVE" ;
VAL_ 568 Output_10_Interlock 0 "IDLE" 1 "ACTIVE" ;
VAL_ 568 Output_11_Interlock 0 "IDLE" 1 "ACTIVE" ;
VAL_ 568 Output_12_Interlock 0 "IDLE" 1 "ACTIVE" ;
VAL_ 568 Output_13_Interlock 0 "IDLE" 1 "ACTIVE" ;
VAL_ 569 Output_1_Interlock 0 "IDLE" 1 "ACTIVE" ;
VAL_ 569 Output_2_Interlock 0 "IDLE" 1 "ACTIVE" ;
VAL_ 569 Output_3_Interlock 0 "IDLE" 1 "ACTIVE" ;
VAL_ 569 Output_4_Interlock 0 "IDLE" 1 "ACTIVE" ;
VAL_ 569 Output_5_Interlock 0 "IDLE" 1 "ACTIVE" ;
VAL_ 569 Output_6_Interlock 0 "IDLE" 1 "ACTIVE" ;
VAL_ 569 BMU_Reset_signal 0 "IDLE" 1 "ACTIVE" ;
VAL_ 569 Output_7_Interlock 0 "IDLE" 1 "ACTIVE" ;
VAL_ 569 Output_8_Interlock 0 "IDLE" 1 "ACTIVE" ;
VAL_ 569 Output_9_Interlock 0 "IDLE" 1 "ACTIVE" ;
VAL_ 569 Output_10_Interlock 0 "IDLE" 1 "ACTIVE" ;
VAL_ 569 Output_11_Interlock 0 "IDLE" 1 "ACTIVE" ;
VAL_ 569 Output_12_Interlock 0 "IDLE" 1 "ACTIVE" ;
VAL_ 569 Output_13_Interlock 0 "IDLE" 1 "ACTIVE" ;
VAL_ 570 Output_1_Interlock 0 "IDLE" 1 "ACTIVE" ;
VAL_ 570 Output_2_Interlock 0 "IDLE" 1 "ACTIVE" ;
VAL_ 570 Output_3_Interlock 0 "IDLE" 1 "ACTIVE" ;
VAL_ 570 Output_4_Interlock 0 "IDLE" 1 "ACTIVE" ;
VAL_ 570 Output_5_Interlock 0 "IDLE" 1 "ACTIVE" ;
VAL_ 570 Output_6_Interlock 0 "IDLE" 1 "ACTIVE" ;
VAL_ 570 BMU_Reset_signal 0 "IDLE" 1 "ACTIVE" ;
VAL_ 570 Output_7_Interlock 0 "IDLE" 1 "ACTIVE" ;
VAL_ 570 Output_8_Interlock 0 "IDLE" 1 "ACTIVE" ;
VAL_ 570 Output_9_Interlock 0 "IDLE" 1 "ACTIVE" ;
VAL_ 570 Output_10_Interlock 0 "IDLE" 1 "ACTIVE" ;
VAL_ 570 Output_11_Interlock 0 "IDLE" 1 "ACTIVE" ;
VAL_ 570 Output_12_Interlock 0 "IDLE" 1 "ACTIVE" ;
VAL_ 570 Output_13_Interlock 0 "IDLE" 1 "ACTIVE" ;
VAL_ 571 Output_1_Interlock 0 "IDLE" 1 "ACTIVE" ;
VAL_ 571 Output_2_Interlock 0 "IDLE" 1 "ACTIVE" ;
VAL_ 571 Output_3_Interlock 0 "IDLE" 1 "ACTIVE" ;
VAL_ 571 Output_4_Interlock 0 "IDLE" 1 "ACTIVE" ;
VAL_ 571 Output_5_Interlock 0 "IDLE" 1 "ACTIVE" ;
VAL_ 571 Output_6_Interlock 0 "IDLE" 1 "ACTIVE" ;
VAL_ 571 BMU_Reset_signal 0 "IDLE" 1 "ACTIVE" ;
VAL_ 571 Output_7_Interlock 0 "IDLE" 1 "ACTIVE" ;
VAL_ 571 Output_8_Interlock 0 "IDLE" 1 "ACTIVE" ;
VAL_ 571 Output_9_Interlock 0 "IDLE" 1 "ACTIVE" ;
VAL_ 571 Output_10_Interlock 0 "IDLE" 1 "ACTIVE" ;
VAL_ 571 Output_11_Interlock 0 "IDLE" 1 "ACTIVE" ;
VAL_ 571 Output_12_Interlock 0 "IDLE" 1 "ACTIVE" ;
VAL_ 571 Output_13_Interlock 0 "IDLE" 1 "ACTIVE" ;
VAL_ 572 Output_1_Interlock 0 "IDLE" 1 "ACTIVE" ;
VAL_ 572 Output_2_Interlock 0 "IDLE" 1 "ACTIVE" ;
VAL_ 572 Output_3_Interlock 0 "IDLE" 1 "ACTIVE" ;
VAL_ 572 Output_4_Interlock 0 "IDLE" 1 "ACTIVE" ;
VAL_ 572 Output_5_Interlock 0 "IDLE" 1 "ACTIVE" ;
VAL_ 572 Output_6_Interlock 0 "IDLE" 1 "ACTIVE" ;
VAL_ 572 BMU_Reset_signal 0 "IDLE" 1 "ACTIVE" ;
VAL_ 572 Output_7_Interlock 0 "IDLE" 1 "ACTIVE" ;
VAL_ 572 Output_8_Interlock 0 "IDLE" 1 "ACTIVE" ;
VAL_ 572 Output_9_Interlock 0 "IDLE" 1 "ACTIVE" ;
VAL_ 572 Output_10_Interlock 0 "IDLE" 1 "ACTIVE" ;
VAL_ 572 Output_11_Interlock 0 "IDLE" 1 "ACTIVE" ;
VAL_ 572 Output_12_Interlock 0 "IDLE" 1 "ACTIVE" ;
VAL_ 572 Output_13_Interlock 0 "IDLE" 1 "ACTIVE" ;
VAL_ 573 Output_1_Interlock 0 "IDLE" 1 "ACTIVE" ;
VAL_ 573 Output_2_Interlock 0 "IDLE" 1 "ACTIVE" ;
VAL_ 573 Output_3_Interlock 0 "IDLE" 1 "ACTIVE" ;
VAL_ 573 Output_4_Interlock 0 "IDLE" 1 "ACTIVE" ;
VAL_ 573 Output_5_Interlock 0 "IDLE" 1 "ACTIVE" ;
VAL_ 573 Output_6_Interlock 0 "IDLE" 1 "ACTIVE" ;
VAL_ 573 BMU_Reset_signal 0 "IDLE" 1 "ACTIVE" ;
VAL_ 573 Output_7_Interlock 0 "IDLE" 1 "ACTIVE" ;
VAL_ 573 Output_8_Interlock 0 "IDLE" 1 "ACTIVE" ;
VAL_ 573 Output_9_Interlock 0 "IDLE" 1 "ACTIVE" ;
VAL_ 573 Output_10_Interlock 0 "IDLE" 1 "ACTIVE" ;
VAL_ 573 Output_11_Interlock 0 "IDLE" 1 "ACTIVE" ;
VAL_ 573 Output_12_Interlock 0 "IDLE" 1 "ACTIVE" ;
VAL_ 573 Output_13_Interlock 0 "IDLE" 1 "ACTIVE" ;
VAL_ 574 Output_1_Interlock 0 "IDLE" 1 "ACTIVE" ;
VAL_ 574 Output_2_Interlock 0 "IDLE" 1 "ACTIVE" ;
VAL_ 574 Output_3_Interlock 0 "IDLE" 1 "ACTIVE" ;
VAL_ 574 Output_4_Interlock 0 "IDLE" 1 "ACTIVE" ;
VAL_ 574 Output_5_Interlock 0 "IDLE" 1 "ACTIVE" ;
VAL_ 574 Output_6_Interlock 0 "IDLE" 1 "ACTIVE" ;
VAL_ 574 BMU_Reset_signal 0 "IDLE" 1 "ACTIVE" ;
VAL_ 574 Output_7_Interlock 0 "IDLE" 1 "ACTIVE" ;
VAL_ 574 Output_8_Interlock 0 "IDLE" 1 "ACTIVE" ;
VAL_ 574 Output_9_Interlock 0 "IDLE" 1 "ACTIVE" ;
VAL_ 574 Output_10_Interlock 0 "IDLE" 1 "ACTIVE" ;
VAL_ 574 Output_11_Interlock 0 "IDLE" 1 "ACTIVE" ;
VAL_ 574 Output_12_Interlock 0 "IDLE" 1 "ACTIVE" ;
VAL_ 574 Output_13_Interlock 0 "IDLE" 1 "ACTIVE" ;
VAL_ 575 Output_1_Interlock 0 "IDLE" 1 "ACTIVE" ;
VAL_ 575 Output_2_Interlock 0 "IDLE" 1 "ACTIVE" ;
VAL_ 575 Output_3_Interlock 0 "IDLE" 1 "ACTIVE" ;
VAL_ 575 Output_4_Interlock 0 "IDLE" 1 "ACTIVE" ;
VAL_ 575 Output_5_Interlock 0 "IDLE" 1 "ACTIVE" ;
VAL_ 575 Output_6_Interlock 0 "IDLE" 1 "ACTIVE" ;
VAL_ 575 BMU_Reset_signal 0 "IDLE" 1 "ACTIVE" ;
VAL_ 575 Output_7_Interlock 0 "IDLE" 1 "ACTIVE" ;
VAL_ 575 Output_8_Interlock 0 "IDLE" 1 "ACTIVE" ;
VAL_ 575 Output_9_Interlock 0 "IDLE" 1 "ACTIVE" ;
VAL_ 575 Output_10_Interlock 0 "IDLE" 1 "ACTIVE" ;
VAL_ 575 Output_11_Interlock 0 "IDLE" 1 "ACTIVE" ;
VAL_ 575 Output_12_Interlock 0 "IDLE" 1 "ACTIVE" ;
VAL_ 575 Output_13_Interlock 0 "IDLE" 1 "ACTIVE" ;
